VERSION ""

NS_ :

BS_:

BU_: CEM20 GW IDM Tester

BO_ 719 IFC_FD3: 64 IDM
 SG_ AttentionDivsAlarmTimGrad : 445|2@0+ (1,0) [0|3] "NoUnit" Vector__XXX
 SG_ TraLightCtrlSts : 383|3@0+ (1,0) [0|7] "NoUnit" Vector__XXX
 SG_ RR_SideCamaErrSts : 373|3@0+ (1,0) [0|7] "NoUnit" Vector__XXX
 SG_ LR_SideCamaErrSts : 360|3@0+ (1,0) [0|7] "NoUnit" Vector__XXX
 SG_ ILC_InterSysInfoDisp : 359|3@0+ (1,0) [0|7] "NoUnit" Vector__XXX
 SG_ TraLightSwtResp : 344|1@0+ (1,0) [0|1] "" Vector__XXX
 SG_ TraLightRmdInfoDisp : 349|5@0+ (1,0) [0|31] "" Vector__XXX
 SG_ TraLightWarnInfoDisp : 337|4@0+ (1,0) [0|15] "" Vector__XXX
 SG_ TSR_TFL_EgoVeh : 341|4@0+ (1,0) [0|15] "" Vector__XXX
 SG_ TSR_TFL7_LightColor : 328|3@0+ (1,0) [0|7] "" Vector__XXX
 SG_ TSR_TFL7_LightType : 332|4@0+ (1,0) [0|15] "" Vector__XXX
 SG_ TSR_TFL6_LightColor : 335|3@0+ (1,0) [0|7] "" Vector__XXX
 SG_ TSR_TFL6_LightType : 319|4@0+ (1,0) [0|15] "" Vector__XXX
 SG_ TSR_TFL5_LightColor : 307|3@0+ (1,0) [0|7] "" Vector__XXX
 SG_ TSR_TFL5_LightType : 311|4@0+ (1,0) [0|15] "" Vector__XXX
 SG_ TSR_TFL4_LightColor : 298|3@0+ (1,0) [0|7] "" Vector__XXX
 SG_ TSR_TFL4_LightType : 302|4@0+ (1,0) [0|15] "" Vector__XXX
 SG_ TSR_TFL3_LightColor : 289|3@0+ (1,0) [0|7] "" Vector__XXX
 SG_ TSR_TFL3_LightType : 293|4@0+ (1,0) [0|15] "" Vector__XXX
 SG_ TSR_TFL2_LightColor : 280|3@0+ (1,0) [0|8] "" Vector__XXX
 SG_ TSR_TFL2_LightType : 284|4@0+ (1,0) [0|15] "" Vector__XXX
 SG_ TSR_TFL1_LightColor : 287|3@0+ (1,0) [0|7] "" Vector__XXX
 SG_ TSR_TFL7_LightTime : 279|8@0+ (1,0) [0|255] "s" Vector__XXX
 SG_ TSR_TFL6_LightTime : 271|8@0+ (1,0) [0|255] "s" Vector__XXX
 SG_ NavDecActive : 239|4@0+ (1,0) [0|15] "NoUnit" Vector__XXX
 SG_ NavDecSwtResp : 225|1@0+ (1,0) [0|1] "NoUnit" Vector__XXX
 SG_ LCMode_Swt_Resp : 227|2@0+ (1,0) [0|3] "" Vector__XXX
 SG_ RainMode_Swt_Resp : 228|1@0+ (1,0) [0|1] "" Vector__XXX
 SG_ TSR_Traffic_Light_Ri : 230|2@0+ (1,0) [0|3] "" Vector__XXX
 SG_ Zebra_Mark_Dx : 223|9@0+ (0.5,0) [0|150] "m" Vector__XXX
 SG_ TSR_Traffic_Light_Le : 210|2@0+ (1,0) [0|3] "" Vector__XXX
 SG_ TSR_Traffic_Light_Through : 212|2@0+ (1,0) [0|3] "" Vector__XXX
 SG_ TSR_Traffic_Light : 214|2@0+ (1,0) [0|3] "" Vector__XXX
 SG_ Grid_Mark_Dx : 207|9@0+ (0.5,0) [0|150] "m" Vector__XXX
 SG_ LaneChngCfmSwt_Resp : 189|1@0+ (1,0) [0|1] "" Vector__XXX
 SG_ ALC_SwtReq_Resp : 190|1@0+ (1,0) [0|1] "" Vector__XXX
 SG_ AutoSpdSetSwt_Resp : 191|1@0+ (1,0) [0|1] "" Vector__XXX
 SG_ VoiceBrdcSwt_Resp : 176|1@0+ (1,0) [0|1] "" Vector__XXX
 SG_ UsrManSts_Resp : 180|4@0+ (1,0) [0|15] "" Vector__XXX
 SG_ HWA_InhibitWarn : 183|3@0+ (1,0) [0|7] "" Vector__XXX
 SG_ Grid_Mark_Detn : 169|2@0+ (1,0) [0|3] "" Vector__XXX
 SG_ Zebra_Mark_Detn : 171|2@0+ (1,0) [0|3] "" Vector__XXX
 SG_ Stop_Mark_Detn : 173|2@0+ (1,0) [0|3] "" Vector__XXX
 SG_ IFC_Line02_Source : 174|1@0+ (1,0) [0|1] "" Vector__XXX
 SG_ Stop_Mark_Dx : 167|9@0+ (0.5,0) [0|150] "m" Vector__XXX
 SG_ TSR_Traffic_Light_Posn : 153|2@0+ (1,0) [0|3] "" Vector__XXX
 SG_ NOH_WarnInfoDisp : 157|4@0+ (1,0) [0|15] "" Vector__XXX
 SG_ MRC_TakOver_Req : 159|2@0+ (1,0) [0|3] "" Vector__XXX
 SG_ IFC_Line01_Source : 144|1@0+ (1,0) [0|1] "" Vector__XXX
 SG_ MRC_InterSysInfoDisp : 148|4@0+ (1,0) [0|15] "" Vector__XXX
 SG_ HWA_TakOver_Trig : 151|3@0+ (1,0) [0|7] "" Vector__XXX
 SG_ HWA_TakOver_Req : 137|2@0+ (1,0) [0|3] "" Vector__XXX
 SG_ HWA_WarnInfoDisp : 141|4@0+ (1,0) [0|15] "" Vector__XXX
 SG_ HWA_ALC_Trig : 143|2@0+ (1,0) [0|3] "" Vector__XXX
 SG_ RollingCounter_IFC7 : 123|4@0+ (1,0) [0|15] "" Vector__XXX
 SG_ HMA_Sts : 127|3@0+ (1,0) [0|7] "" Vector__XXX
 SG_ HMA_HibeamReq : 113|2@0+ (1,0) [0|3] "" Vector__XXX
 SG_ IDC_L2_FWshrReq : 119|2@0+ (1,0) [0|3] "" Vector__XXX
 SG_ TSRSpdLimWarnAu : 104|1@0+ (1,0) [0|1] "NoUnit" Vector__XXX
 SG_ IDC_L2_FWiperReq : 107|3@0+ (1,0) [0|7] "" Vector__XXX
 SG_ TSRWarnResp : 108|1@0+ (1,0) [0|1] "" Vector__XXX
 SG_ IDC_L2_TurnLightReq : 110|2@0+ (1,0) [0|3] "" Vector__XXX
 SG_ IDC_L2_EmgyLightReq : 111|1@0+ (1,0) [0|1] "" Vector__XXX
 SG_ TSR_Snvty : 100|5@0+ (1,-15) [-15|15] "km/h" Vector__XXX
 SG_ TSRSpdLimWarn : 101|1@0+ (1,0) [0|1] "" Vector__XXX
 SG_ TSRTrfcSignVal : 93|8@0+ (1,0) [0|255] "" Vector__XXX
 SG_ TSRTrfcSignValCfdc : 95|2@0+ (1,0) [0|3] "" Vector__XXX
 SG_ TSRSpdLimSts : 81|2@0+ (1,0) [0|3] "" Vector__XXX
 SG_ TSRSpdLim : 87|6@0+ (1,0) [0|63] "" Vector__XXX
 SG_ TSRSts : 74|3@0+ (1,0) [0|7] "" Vector__XXX
 SG_ TSRSpdLimCfdc : 76|2@0+ (1,0) [0|3] "" Vector__XXX
 SG_ TSRSpdLimUnit : 78|2@0+ (1,0) [0|3] "" Vector__XXX
 SG_ TSRResp : 79|1@0+ (1,0) [0|1] "" Vector__XXX
 SG_ Checksum_IFC7 : 71|8@0+ (1,0) [0|255] "" Vector__XXX
 SG_ TSR_TFL1_LightType : 63|4@0+ (1,0) [0|15] "" Vector__XXX
 SG_ TSR_TFL5_LightTime : 55|8@0+ (1,0) [0|255] "s" Vector__XXX
 SG_ TSR_TFL4_LightTime : 47|8@0+ (1,0) [0|255] "s" Vector__XXX
 SG_ TSR_TFL3_LightTime : 39|8@0+ (1,0) [0|255] "s" Vector__XXX
 SG_ TSR_TFL2_LightTime : 31|8@0+ (1,0) [0|255] "s" Vector__XXX
 SG_ TSR_TFL1_LightTime : 23|8@0+ (1,0) [0|255] "s" Vector__XXX
 SG_ TSRConSpdLimWarn : 9|1@0+ (1,0) [0|1] "" Vector__XXX
 SG_ TSRConSpdLim : 15|6@0+ (1,0) [0|63] "" Vector__XXX

BO_ 395 AEB_FD1: 64 IDM
 SG_ RAEB_Warn : 413|3@0+ (1,0) [0|7] "NoUnit" Vector__XXX
 SG_ RAEB_State : 400|3@0+ (1,0) [0|7] "NoUnit" Vector__XXX
 SG_ EBA_State : 403|3@0+ (1,0) [0|7] "NoUnit" Vector__XXX
 SG_ AEB_State : 406|3@0+ (1,0) [0|7] "NoUnit" Vector__XXX
 SG_ AWB_State : 393|3@0+ (1,0) [0|7] "NoUnit" Vector__XXX
 SG_ FCW_State : 396|3@0+ (1,0) [0|7] "NoUnit" Vector__XXX
 SG_ DW_State : 399|3@0+ (1,0) [0|7] "NoUnit" Vector__XXX
 SG_ RollingCounter_AEB6 : 187|4@0+ (1,0) [0|15] "NoUnit" Vector__XXX
 SG_ ExcpADASBrkgHldReq : 173|2@0+ (1,0) [0|3] "NoUnit" Vector__XXX
 SG_ DrvPrsnt : 175|2@0+ (1,0) [0|3] "NoUnit" Vector__XXX
 SG_ BrkgHldReq : 161|2@0+ (1,0) [0|3] "NoUnit" Vector__XXX
 SG_ BrkgSwtReq : 163|2@0+ (1,0) [0|3] "NoUnit" Vector__XXX
 SG_ EPBModEna : 165|2@0+ (1,0) [0|3] "NoUnit" Vector__XXX
 SG_ EPBModReq : 167|2@0+ (1,0) [0|3] "NoUnit" Vector__XXX
 SG_ EPBModReqVld : 152|1@0+ (1,0) [0|1] "NoUnit" Vector__XXX
 SG_ BrkgTgtTyp : 154|2@0+ (1,0) [0|3] "NoUnit" Vector__XXX
 SG_ BrkgTgtTrqMod : 156|2@0+ (1,0) [0|3] "NoUnit" Vector__XXX
 SG_ BrkgTgtTrqEna : 158|2@0+ (1,0) [0|3] "NoUnit" Vector__XXX
 SG_ BrkgTgtTrqVld : 159|1@0+ (1,0) [0|1] "NoUnit" Vector__XXX
 SG_ BrkgTgtTrq : 143|16@0+ (1,-1) [0|65534] "Nm" Vector__XXX
 SG_ Checksum_AEB6 : 135|8@0+ (1,0) [0|255] "NoUnit" Vector__XXX
 SG_ RollingCounter_AEB1 : 123|4@0+ (1,0) [0|15] "" Vector__XXX
 SG_ IntellgntAsscRoadTypConfid : 115|4@0+ (0.1,-0.1) [0|1] "NoUnit" Vector__XXX
 SG_ IntellgntAsscRoadTyp : 119|4@0+ (1,0) [0|15] "NoUnit" Vector__XXX
 SG_ AEB_ObjSty : 111|3@0+ (1,0) [0|7] "" Vector__XXX
 SG_ AEB_BrkReqFunc : 99|3@0+ (1,0) [0|7] "" Vector__XXX
 SG_ AEB_AWB_Level : 103|4@0+ (1,0) [0|15] "" Vector__XXX
 SG_ AEB_TgtDecel_ReqValue : 87|16@0+ (0.000488,-16) [-16|15.980592] "m/s2" Vector__XXX
 SG_ AEB_ABP_Req : 72|1@0+ (1,0) [0|1] "" Vector__XXX
 SG_ AEB_AWB_Req : 73|1@0+ (1,0) [0|1] "" Vector__XXX
 SG_ AEB_TgtDecel_Req : 74|1@0+ (1,0) [0|1] "" Vector__XXX
 SG_ AEB_VehHldReq : 75|1@0+ (1,0) [0|1] "" Vector__XXX
 SG_ EBA_TgtDecel_Req : 76|1@0+ (1,0) [0|1] "" Vector__XXX
 SG_ AEB_ABA_Req : 77|1@0+ (1,0) [0|1] "" Vector__XXX
 SG_ AEB_ABA_Level : 79|2@0+ (1,0) [0|3] "" Vector__XXX
 SG_ Checksum_AEB1 : 71|8@0+ (1,0) [0|255] "" Vector__XXX
 SG_ AEB_Flag_VSI : 60|1@0+ (1,0) [0|1] "" Vector__XXX
 SG_ ADAS_ErrSts : 31|3@0+ (1,0) [0|7] "" Vector__XXX
 SG_ RelTgtObjVel_X : 23|8@0+ (0.167,0) [0|42] "mps" Vector__XXX
 SG_ TimeToCllsn : 15|8@0+ (0.004,0) [0|1] "s" Vector__XXX

BO_ 576 IFC_FD4: 64 IDM
 SG_ RollingCounter_IFC_HCM7 : 443|4@0+ (1,0) [0|15] "NoUnit" Vector__XXX
 SG_ Spots7VehObjClassn : 446|3@0+ (1,0) [0|7] "NoUnit" Vector__XXX
 SG_ Spots7TrackingInfo : 447|1@0+ (1,0) [0|1] "NoUnit" Vector__XXX
 SG_ Spot7VertAng : 439|8@0+ (0.125,-5) [-5|26.875] "NoUnit" Vector__XXX
 SG_ Spots7HozLeAngSpd : 431|8@0+ (0.125,-16) [-16|15.875] "DegPerSec" Vector__XXX
 SG_ Spots7Distance : 408|9@0+ (1,0) [0|510] "m" Vector__XXX
 SG_ Spots7Typ : 410|2@0+ (1,0) [0|3] "NoUnit" Vector__XXX
 SG_ Spots7Valid : 411|1@0+ (1,0) [0|1] "NoUnit" Vector__XXX
 SG_ Spots7HozlPosnRiAng : 405|10@0+ (0.08,-40) [-40|40] "Deg" Vector__XXX
 SG_ Spots7HozlPosnLeAng : 399|10@0+ (0.08,-40) [-40|40] "Deg" Vector__XXX
 SG_ Checksum_IFC_HCM7 : 391|8@0+ (1,0) [0|255] "NoUnit" Vector__XXX
 SG_ RollingCounter_IFC_HCM6 : 379|4@0+ (1,0) [0|15] "NoUnit" Vector__XXX
 SG_ Spots6VehObjClassn : 382|3@0+ (1,0) [0|7] "NoUnit" Vector__XXX
 SG_ Spots6TrackingInfo : 383|1@0+ (1,0) [0|1] "NoUnit" Vector__XXX
 SG_ Spot6VertAng : 375|8@0+ (0.125,-5) [-5|26.875] "NoUnit" Vector__XXX
 SG_ Spots6HozLeAngSpd : 367|8@0+ (0.125,-16) [-16|15.875] "DegPerSec" Vector__XXX
 SG_ Spots6Distance : 344|9@0+ (1,0) [0|510] "m" Vector__XXX
 SG_ Spots6Typ : 346|2@0+ (1,0) [0|3] "NoUnit" Vector__XXX
 SG_ Spots6Valid : 347|1@0+ (1,0) [0|1] "NoUnit" Vector__XXX
 SG_ Spots6HozlPosnRiAng : 341|10@0+ (0.08,-40) [-40|40] "Deg" Vector__XXX
 SG_ Spots6HozlPosnLeAng : 335|10@0+ (0.08,-40) [-40|40] "Deg" Vector__XXX
 SG_ Checksum_IFC_HCM6 : 327|8@0+ (1,0) [0|255] "NoUnit" Vector__XXX
 SG_ RollingCounter_IFC_HCM5 : 315|4@0+ (1,0) [0|15] "NoUnit" Vector__XXX
 SG_ Spots5VehObjClassn : 318|3@0+ (1,0) [0|7] "NoUnit" Vector__XXX
 SG_ Spots5TrackingInfo : 319|1@0+ (1,0) [0|1] "NoUnit" Vector__XXX
 SG_ Spot5VertAng : 311|8@0+ (0.125,-5) [-5|26.875] "NoUnit" Vector__XXX
 SG_ Spots5HozLeAngSpd : 303|8@0+ (0.125,-16) [-16|15.875] "DegPerSec" Vector__XXX
 SG_ Spots5Distance : 280|9@0+ (1,0) [0|510] "m" Vector__XXX
 SG_ Spots5Typ : 282|2@0+ (1,0) [0|3] "NoUnit" Vector__XXX
 SG_ Spots5Valid : 283|1@0+ (1,0) [0|1] "NoUnit" Vector__XXX
 SG_ Spots5HozlPosnRiAng : 277|10@0+ (0.08,-40) [-40|40] "Deg" Vector__XXX
 SG_ Spots5HozlPosnLeAng : 271|10@0+ (0.08,-40) [-40|40] "Deg" Vector__XXX
 SG_ Checksum_IFC_HCM5 : 263|8@0+ (1,0) [0|255] "NoUnit" Vector__XXX
 SG_ RollingCounter_IFC_HCM4 : 251|4@0+ (1,0) [0|15] "NoUnit" Vector__XXX
 SG_ Spots4VehObjClassn : 254|3@0+ (1,0) [0|7] "NoUnit" Vector__XXX
 SG_ Spots4TrackingInfo : 255|1@0+ (1,0) [0|1] "NoUnit" Vector__XXX
 SG_ Spot4VertAng : 247|8@0+ (0.125,-5) [-5|26.875] "NoUnit" Vector__XXX
 SG_ Spots4HozLeAngSpd : 239|8@0+ (0.125,-16) [-16|15.875] "DegPerSec" Vector__XXX
 SG_ Spots4Distance : 216|9@0+ (1,0) [0|510] "m" Vector__XXX
 SG_ Spots4Typ : 218|2@0+ (1,0) [0|3] "NoUnit" Vector__XXX
 SG_ Spots4Valid : 219|1@0+ (1,0) [0|1] "NoUnit" Vector__XXX
 SG_ Spots4HozlPosnRiAng : 213|10@0+ (0.08,-40) [-40|40] "Deg" Vector__XXX
 SG_ Spots4HozlPosnLeAng : 207|10@0+ (0.08,-40) [-40|40] "Deg" Vector__XXX
 SG_ Checksum_IFC_HCM4 : 199|8@0+ (1,0) [0|255] "NoUnit" Vector__XXX
 SG_ RollingCounter_IFC_HCM3 : 187|4@0+ (1,0) [0|15] "NoUnit" Vector__XXX
 SG_ Spots3VehObjClassn : 190|3@0+ (1,0) [0|7] "NoUnit" Vector__XXX
 SG_ Spots3TrackingInfo : 191|1@0+ (1,0) [0|1] "NoUnit" Vector__XXX
 SG_ Spot3VertAng : 183|8@0+ (0.125,-5) [-5|26.875] "NoUnit" Vector__XXX
 SG_ Spots3HozLeAngSpd : 175|8@0+ (0.125,-16) [-16|15.875] "DegPerSec" Vector__XXX
 SG_ Spots3Distance : 152|9@0+ (1,0) [0|510] "m" Vector__XXX
 SG_ Spots3Typ : 154|2@0+ (1,0) [0|3] "NoUnit" Vector__XXX
 SG_ Spots3Valid : 155|1@0+ (1,0) [0|1] "NoUnit" Vector__XXX
 SG_ Spots3HozlPosnRiAng : 149|10@0+ (0.08,-40) [-40|40] "Deg" Vector__XXX
 SG_ Spots3HozlPosnLeAng : 143|10@0+ (0.08,-40) [-40|40] "Deg" Vector__XXX
 SG_ Checksum_IFC_HCM3 : 135|8@0+ (1,0) [0|255] "NoUnit" Vector__XXX
 SG_ RollingCounter_IFC_HCM2 : 123|4@0+ (1,0) [0|15] "NoUnit" Vector__XXX
 SG_ Spots2VehObjClassn : 126|3@0+ (1,0) [0|7] "NoUnit" Vector__XXX
 SG_ Spots2TrackingInfo : 127|1@0+ (1,0) [0|1] "NoUnit" Vector__XXX
 SG_ Spot2VertAng : 119|8@0+ (0.125,-5) [-5|26.875] "NoUnit" Vector__XXX
 SG_ Spots2HozLeAngSpd : 111|8@0+ (0.125,-16) [-16|15.875] "DegPerSec" Vector__XXX
 SG_ Spots2Distance : 88|9@0+ (1,0) [0|510] "m" Vector__XXX
 SG_ Spots2Typ : 90|2@0+ (1,0) [0|3] "NoUnit" Vector__XXX
 SG_ Spots2Valid : 91|1@0+ (1,0) [0|1] "NoUnit" Vector__XXX
 SG_ Spots2HozlPosnRiAng : 85|10@0+ (0.08,-40) [-40|40] "Deg" Vector__XXX
 SG_ Spots2HozlPosnLeAng : 79|10@0+ (0.08,-40) [-40|40] "Deg" Vector__XXX
 SG_ Checksum_IFC_HCM2 : 71|8@0+ (1,0) [0|255] "NoUnit" Vector__XXX
 SG_ RollingCounter_IFC_HCM1 : 59|4@0+ (1,0) [0|15] "NoUnit" Vector__XXX
 SG_ Spots1VehObjClassn : 62|3@0+ (1,0) [0|7] "NoUnit" Vector__XXX
 SG_ Spots1TrackingInfo : 63|1@0+ (1,0) [0|1] "NoUnit" Vector__XXX
 SG_ Spot1VertAng : 55|8@0+ (0.125,-5) [-5|26.875] "NoUnit" Vector__XXX
 SG_ Spots1HozLeAngSpd : 47|8@0+ (0.125,-16) [-16|15.875] "DegPerSec" Vector__XXX
 SG_ Spots1Distance : 24|9@0+ (1,0) [0|510] "m" Vector__XXX
 SG_ Spots1Typ : 26|2@0+ (1,0) [0|3] "NoUnit" Vector__XXX
 SG_ Spots1Valid : 27|1@0+ (1,0) [0|1] "NoUnit" Vector__XXX
 SG_ Spots1HozlPosnRiAng : 21|10@0+ (0.08,-40) [-40|40] "Deg" Vector__XXX
 SG_ Spots1HozlPosnLeAng : 15|10@0+ (0.08,-40) [-40|40] "Deg" Vector__XXX
 SG_ Checksum_IFC_HCM1 : 7|8@0+ (1,0) [0|255] "NoUnit" Vector__XXX

BO_ 667 HAP_FD7: 64 IDM
 SG_ HAVP_LrngDst : 375|10@0+ (1,0) [0|1000] "m" Vector__XXX
 SG_ PAVP_ScFail_info : 367|5@0+ (1,0) [0|31] "" Vector__XXX
 SG_ HAVP_ScFail_info : 351|5@0+ (1,0) [0|31] "" Vector__XXX
 SG_ UnPrkgSpaReasons : 341|6@0+ (1,0) [0|63] "NoUnit" Vector__XXX

BO_ 674 IFC_FD7: 48 IDM
 SG_ RP_Num_Points_Per_Tube : 207|16@0+ (1,0) [0|1200] "" Vector__XXX
 SG_ RP_Algo_MCU_TimeStamp : 135|64@0+ (1,0) [0|18446744073709500416] "ms" Vector__XXX
 SG_ RP_Shock_Dist_R : 108|10@0+ (0.02,0) [0|20] "m" Vector__XXX
 SG_ RP_Shock_Height_R : 101|9@0+ (0.002,-0.3) [-0.3|0.3] "m" Vector__XXX
 SG_ RP_Shock_Dist_L : 95|10@0+ (0.02,0) [0|20] "m" Vector__XXX
 SG_ RP_Shock_Confidence_L : 86|7@0+ (0.01,0) [0|1] "" Vector__XXX
 SG_ RP_Shock_Height_L : 79|9@0+ (0.002,-0.3) [-0.3|0.3] "m" Vector__XXX
 SG_ RP_Shock_Detected_R : 60|1@0+ (1,0) [0|1] "" Vector__XXX
 SG_ RP_Shock_Detected_L : 61|1@0+ (1,0) [0|1] "" Vector__XXX
 SG_ RP_New_Measurment : 62|1@0+ (1,0) [0|1] "" Vector__XXX
 SG_ RP_Valid : 63|1@0+ (1,0) [0|1] "" Vector__XXX
 SG_ RP_Shock_Confidence_R : 55|7@0+ (0.01,0) [0|1] "" Vector__XXX
 SG_ RP_Start_Point_Distance : 35|10@0+ (0.01,0) [0|10] "m" Vector__XXX
 SG_ RP_Used_Speed : 31|12@0+ (0.05,-10) [-10|100] "m/s" Vector__XXX
 SG_ RP_Sync_ID : 15|8@0+ (1,0) [0|255] "" Vector__XXX

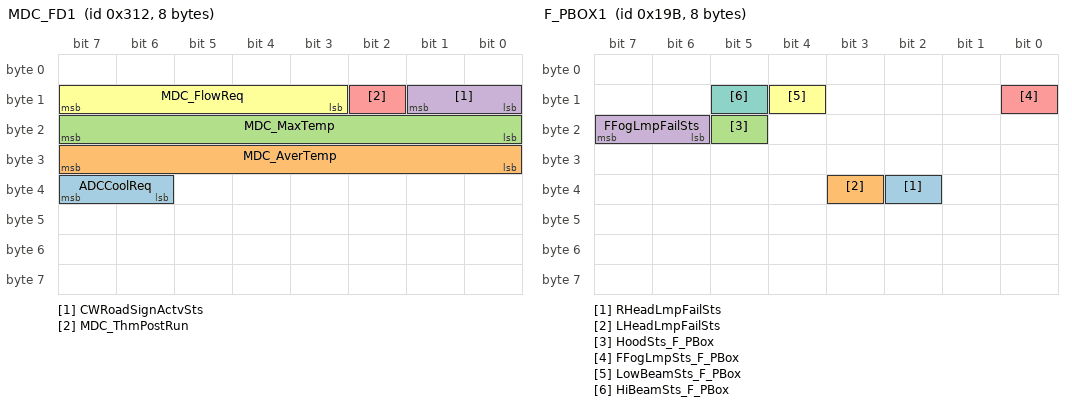
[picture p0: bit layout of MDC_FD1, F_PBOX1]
BO_ 786 MDC_FD1: 8 IDM
 SG_ ADCCoolReq : 39|2@0+ (1,0) [0|3] "NoUnit" Vector__XXX
 SG_ MDC_AverTemp : 31|8@0+ (1,-50) [-50|204] "DegCgrd" Vector__XXX
 SG_ MDC_MaxTemp : 23|8@0+ (1,-50) [-50|204] "DegCgrd" Vector__XXX
 SG_ CWRoadSignActvSts : 9|2@0+ (1,0) [0|3] "NoUnit" Vector__XXX
 SG_ MDC_ThmPostRun : 10|1@0+ (1,0) [0|1] "NoUnit" Vector__XXX
 SG_ MDC_FlowReq : 15|5@0+ (0.25,0) [0|4] "NoUnit" Vector__XXX

BO_ 1125 IDC_Sync_Req: 16 IDM
 SG_ IDC_Sync_Req : 7|128@0+ (1,0) [0|0] "" Vector__XXX

BO_ 573 IFC_FD2: 64 IDM
 SG_ MAC_Check_IFC_FD2 : 471|48@0+ (1,0) [0|281474976710655] "" Vector__XXX
 SG_ FreshnessValue_IFC_FD2 : 455|16@0+ (1,0) [0|65535] "" Vector__XXX
 SG_ SceneModSts : 447|3@0+ (1,0) [0|7] "NoUnit" Vector__XXX
 SG_ IFC_Line_special02_Curv : 431|15@0+ (1.6e-05,-0.25) [-0.25|0.25] "PerMtr" Vector__XXX
 SG_ IFC_Line_special01_DxEnd : 414|15@0+ (0.01,0) [0|200.01] "m" Vector__XXX
 SG_ IFC_Line_special01_DxStart : 399|15@0+ (0.01,0) [0|200.01] "m" Vector__XXX
 SG_ ACC_LeTgtObjBarDisp_03 : 383|3@0+ (1,0) [0|7] "NoUnit" Vector__XXX
 SG_ TargetPathC1 : 360|9@0+ (0.01,-2) [-2|2.01] "rad" Vector__XXX
 SG_ ACC_RiTgtObjBarDisp_02 : 363|3@0+ (1,0) [0|7] "NoUnit" Vector__XXX
 SG_ IFC_Line_special01_CurvChange : 351|20@0+ (5e-08,-0.024) [-0.024|0.024] "PerMtrSq" Vector__XXX
 SG_ IFC_Line_special01_Curv : 335|15@0+ (1.6e-05,-0.25) [-0.25|0.25] "PerMtr" Vector__XXX
 SG_ ACC_LeTgtObjBarDisp_02 : 318|3@0+ (1,0) [0|7] "NoUnit" Vector__XXX
 SG_ SidePrkgSts : 304|2@0+ (1,0) [0|3] "NoUnit" Vector__XXX
 SG_ HandsoffModSts : 306|2@0+ (1,0) [0|3] "NoUnit" Vector__XXX
 SG_ HandsoffTimSts : 308|2@0+ (1,0) [0|3] "NoUnit" Vector__XXX
 SG_ ACC_TgtObjBarDisp_03 : 311|3@0+ (1,0) [0|7] "NoUnit" Vector__XXX
 SG_ ACC_TgtObjBarDisp_02 : 298|3@0+ (1,0) [0|7] "NoUnit" Vector__XXX
 SG_ IFC_Line_special01_Dy : 295|13@0+ (0.01,-30) [-30|30.01] "m" Vector__XXX
 SG_ IFC_NextRiLane_dy : 275|12@0+ (0.00390625,-8) [-8|7.9921875] "" Vector__XXX
 SG_ IFC_NextLeLane_dy : 271|12@0+ (0.00390625,-8) [-8|7.9921875] "" Vector__XXX
 SG_ SmarFrontviewcamSts : 255|3@0+ (1,0) [0|7] "NoUnit" Vector__XXX
 SG_ IFC_RiLane_dy : 235|12@0+ (0.00390625,-8) [-8|7.9921875] "" Vector__XXX
 SG_ IFC_LeLane_dy : 231|12@0+ (0.00390625,-8) [-8|7.9921875] "" Vector__XXX
 SG_ IFC_NextRiLaneTyp : 218|3@0+ (1,0) [0|7] "" Vector__XXX
 SG_ IFC_NextLeLaneTyp : 221|3@0+ (1,0) [0|7] "" Vector__XXX
 SG_ IFC_RiLaneTyp : 208|3@0+ (1,0) [0|7] "" Vector__XXX
 SG_ IFC_LeLaneTyp : 211|3@0+ (1,0) [0|7] "" Vector__XXX
 SG_ IFC_LaneCurve : 207|12@0+ (1.5e-05,-0.030705) [-0.030705|0.030705] "" Vector__XXX
 SG_ ESSintervention : 189|2@0+ (1,0) [0|3] "" Vector__XXX
 SG_ AESintervention : 191|2@0+ (1,0) [0|3] "" Vector__XXX
 SG_ IFC_Line_special02_Type : 179|4@0+ (1,0) [0|15] "NoUnit" Vector__XXX
 SG_ IFC_Line_special01_Type : 183|4@0+ (1,0) [0|15] "NoUnit" Vector__XXX
 SG_ IFC_Line_special02_HeadingAngle : 161|9@0+ (0.01,-2) [-2|2.01] "rad" Vector__XXX
 SG_ LCKStsIndcr : 163|2@0+ (1,0) [0|3] "" Vector__XXX
 SG_ IntelligentEvaActSts : 165|2@0+ (1,0) [0|3] "" Vector__XXX
 SG_ ELKActSts : 167|2@0+ (1,0) [0|3] "" Vector__XXX
 SG_ CameraBlockageSts : 152|1@0+ (1,0) [0|1] "" Vector__XXX
 SG_ IFCCalibrationSts : 154|2@0+ (1,0) [0|3] "" Vector__XXX
 SG_ IFC_Handsoffwarn : 157|3@0+ (1,0) [0|7] "" Vector__XXX
 SG_ LSSErrSts : 144|3@0+ (1,0) [0|7] "" Vector__XXX
 SG_ TJA_FollowSts : 146|2@0+ (1,0) [0|3] "" Vector__XXX
 SG_ LaneAvailability : 148|2@0+ (1,0) [0|3] "" Vector__XXX
 SG_ ELKMainState : 151|3@0+ (1,0) [0|7] "" Vector__XXX
 SG_ LSSFuncSts : 138|3@0+ (1,0) [0|7] "" Vector__XXX
 SG_ LSSIntervention : 141|3@0+ (1,0) [0|7] "" Vector__XXX
 SG_ LDW_LKAWarn : 143|2@0+ (1,0) [0|3] "" Vector__XXX
 SG_ LCP_Warn : 125|2@0+ (1,0) [0|3] "NoUnit" Vector__XXX
 SG_ IFC_Line_special01_HeadingAngle : 118|9@0+ (0.01,-2) [-2|2.01] "rad" Vector__XXX
 SG_ RiRoad_Mark_Dy : 110|8@0+ (0.1,-8) [-8|8] "m" Vector__XXX
 SG_ RiRoad_Mark_Dx : 103|9@0+ (0.5,0) [0|150] "m" Vector__XXX
 SG_ RiRoad_Mark_Typ : 91|4@0+ (1,0) [0|15] "NoUnit" Vector__XXX
 SG_ ESSErrSts : 92|1@0+ (1,0) [0|1] "" Vector__XXX
 SG_ AESErrSts : 93|1@0+ (1,0) [0|1] "" Vector__XXX
 SG_ ESSSts : 95|2@0+ (1,0) [0|3] "" Vector__XXX
 SG_ AESSts : 81|2@0+ (1,0) [0|3] "" Vector__XXX
 SG_ IntelligentEvaResp : 82|1@0+ (1,0) [0|1] "" Vector__XXX
 SG_ LSSResp : 83|1@0+ (1,0) [0|1] "" Vector__XXX
 SG_ LSSWarnFormResp : 85|2@0+ (1,0) [0|3] "" Vector__XXX
 SG_ ESS_VehResp : 86|1@0+ (1,0) [0|1] "" Vector__XXX
 SG_ ESS_PedResp : 87|1@0+ (1,0) [0|1] "" Vector__XXX
 SG_ IFCHUTInterface : 72|1@0+ (1,0) [0|1] "" Vector__XXX
 SG_ LDW_LKA_Snvty : 74|2@0+ (1,0) [0|3] "" Vector__XXX
 SG_ AESResp : 75|1@0+ (1,0) [0|1] "" Vector__XXX
 SG_ ELKResp : 76|1@0+ (1,0) [0|1] "" Vector__XXX
 SG_ LCKResp : 77|1@0+ (1,0) [0|1] "" Vector__XXX
 SG_ LKAResp : 78|1@0+ (1,0) [0|1] "" Vector__XXX
 SG_ LDWResp : 79|1@0+ (1,0) [0|1] "" Vector__XXX
 SG_ LeRoad_Mark_Typ : 63|4@0+ (1,0) [0|15] "NoUnit" Vector__XXX
 SG_ LeRoad_Mark_Dy : 55|8@0+ (0.1,-8) [-8|8] "m" Vector__XXX
 SG_ Road_Mark_Dy : 47|8@0+ (0.1,-8) [-8|8] "m" Vector__XXX
 SG_ LeRoad_Mark_Dx : 24|9@0+ (0.5,0) [0|150] "m" Vector__XXX
 SG_ Road_Mark_Dx : 17|9@0+ (0.5,0) [0|150] "m" Vector__XXX
 SG_ Road_Mark_Typ : 21|4@0+ (1,0) [0|15] "NoUnit" Vector__XXX
 SG_ HWA_Text_Lib : 11|6@0+ (1,0) [0|63] "NoUnit" Vector__XXX
 SG_ IFC_FeatPt_Type : 15|4@0+ (1,0) [0|15] "NoUnit" Vector__XXX

BO_ 411 F_PBOX1: 8 CEM20
 SG_ RHeadLmpFailSts : 34|1@0+ (1,0) [0|1] "NoUnit"  IDM
 SG_ LHeadLmpFailSts : 35|1@0+ (1,0) [0|1] "NoUnit"  IDM
 SG_ HoodSts_F_PBox : 21|1@0+ (1,0) [0|1] ""  IDM
 SG_ FFogLmpFailSts : 23|2@0+ (1,0) [0|3] "NoUnit"  IDM
 SG_ FFogLmpSts_F_PBox : 8|1@0+ (1,0) [0|1] ""  IDM
 SG_ LowBeamSts_F_PBox : 12|1@0+ (1,0) [0|1] ""  IDM
 SG_ HiBeamSts_F_PBox : 13|1@0+ (1,0) [0|1] ""  IDM

BO_ 412 R_PBOX1: 16 CEM20
 SG_ RFogLmpSts_R_PBox : 28|1@0+ (1,0) [0|1] ""  IDM
 SG_ RFogLmpFailSts_R_PBox : 29|1@0+ (1,0) [0|1] ""  IDM
 SG_ RTurnLmpSts_R_PBox : 30|1@0+ (1,0) [0|1] ""  IDM
 SG_ LTurnLmpSts_R_PBox : 31|1@0+ (1,0) [0|1] ""  IDM
 SG_ LTurnLmpFailSts : 17|2@0+ (1,0) [0|3] "NoUnit"  IDM
 SG_ RTurnLmpFailSts : 19|2@0+ (1,0) [0|3] "NoUnit"  IDM
 SG_ PosnLmpOutpSts_R_PBox : 11|1@0+ (1,0) [0|1] ""  IDM
 SG_ RBrkLmpFailSts : 12|1@0+ (1,0) [0|1] ""  IDM
 SG_ LBrkLmpFailSts : 13|1@0+ (1,0) [0|1] ""  IDM
 SG_ HiPosnBrkLmpFailSts : 15|1@0+ (1,0) [0|1] ""  IDM

BO_ 1121 CEM_Sync: 16 CEM20
 SG_ CEM_Sync : 7|128@0+ (1,0) [0|0] ""  IDM

BO_ 833 TPMS1: 16 CEM20
 SG_ MAC_Check_TPMS1 : 87|48@0+ (1,0) [0|281474976710655] "NoUnit"  IDM
 SG_ FreshnessValue_TPMS1 : 71|16@0+ (1,0) [0|65535] "NoUnit"  IDM
 SG_ TPMS_AutoLoctSts : 39|4@0+ (1,0) [0|5] ""  IDM
 SG_ RRTireTempSts : 25|2@0+ (1,0) [0|3] ""  IDM
 SG_ RLTireTempSts : 27|2@0+ (1,0) [0|3] ""  IDM
 SG_ FRTireTempSts : 29|2@0+ (1,0) [0|3] ""  IDM
 SG_ FLTireTempSts : 31|2@0+ (1,0) [0|3] ""  IDM
 SG_ RRTirePressIndSts : 20|3@0+ (1,0) [0|7] ""  IDM
 SG_ RLTirePressIndSts : 23|3@0+ (1,0) [0|7] ""  IDM
 SG_ TirePressSysFailrIndcn : 9|2@0+ (1,0) [0|3] ""  IDM
 SG_ FRTirePressIndSts : 12|3@0+ (1,0) [0|7] ""  IDM
 SG_ FLTirePressIndSts : 15|3@0+ (1,0) [0|7] ""  IDM

BO_ 837 BCM3: 16 CEM20
 SG_ EnvModDetn : 44|2@0+ (1,0) [0|3] "NoUnit"  IDM
 SG_ HiLowBeamSts : 33|2@0+ (1,0) [0|2] "NoUnit"  IDM
 SG_ DrvDoorLockSts : 34|1@0+ (1,0) [0|1] ""  IDM
 SG_ HazardLmpSwtSts : 8|1@0+ (1,0) [0|1] ""  IDM
 SG_ DoorLockSts : 13|2@0+ (1,0) [0|3] "NoUnit"  IDM

BO_ 473 GW_OTA: 8 CEM20
 SG_ OTApowertrainmode : 12|2@0+ (1,0) [0|3] "NoUnit"  IDM

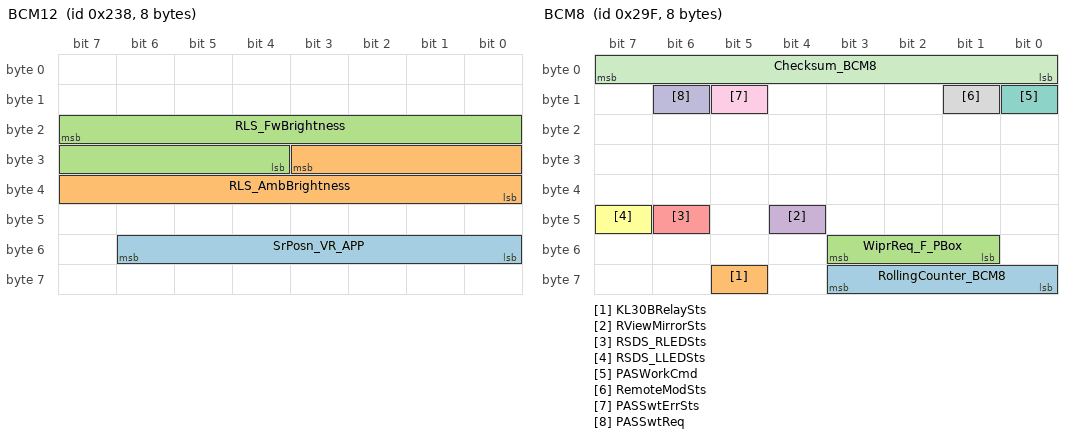
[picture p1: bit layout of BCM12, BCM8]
BO_ 568 BCM12: 8 CEM20
 SG_ SrPosn_VR_APP : 54|7@0+ (1,0) [0|127] ""  IDM
 SG_ RLS_AmbBrightness : 27|12@0+ (20,0) [0|81880] ""  IDM
 SG_ RLS_FwBrightness : 23|12@0+ (6,0) [0|24564] ""  IDM

BO_ 569 GW1: 8 CEM20
 SG_ BasicFunReq : 31|8@0+ (1,0) [1|254] "NoUnit"  IDM
 SG_ BasicFunID : 23|8@0+ (1,0) [1|254] "NoUnit"  IDM

BO_ 661 PEPS2: 8 CEM20
 SG_ SysPowerModVld : 13|1@0+ (1,0) [0|1] ""  IDM
 SG_ SysPowerMod : 15|2@0+ (1,0) [0|3] ""  IDM

BO_ 671 BCM8: 8 CEM20
 SG_ RollingCounter_BCM8 : 59|4@0+ (1,0) [0|15] ""  IDM
 SG_ KL30BRelaySts : 61|1@0+ (1,0) [0|1] ""  IDM
 SG_ WiprReq_F_PBox : 51|3@0+ (1,0) [0|7] ""  IDM
 SG_ RViewMirrorSts : 44|1@0+ (1,0) [0|1] ""  IDM
 SG_ RSDS_RLEDSts : 46|1@0+ (1,0) [0|1] "NoUnit"  IDM
 SG_ RSDS_LLEDSts : 47|1@0+ (1,0) [0|1] "NoUnit"  IDM
 SG_ PASWorkCmd : 8|1@0+ (1,0) [0|1] ""  IDM
 SG_ RemoteModSts : 9|1@0+ (1,0) [0|1] "1"  IDM
 SG_ PASSwtErrSts : 13|1@0+ (1,0) [0|1] "NoUnit"  IDM
 SG_ PASSwtReq : 14|1@0+ (1,0) [0|1] "NoUnit"  IDM
 SG_ Checksum_BCM8 : 7|8@0+ (1,0) [0|255] ""  IDM

BO_ 699 GW_FD1: 64 CEM20
 SG_ OTA_UpgrdModSts : 343|2@0+ (1,0) [0|3] "NoUnit"  IDM

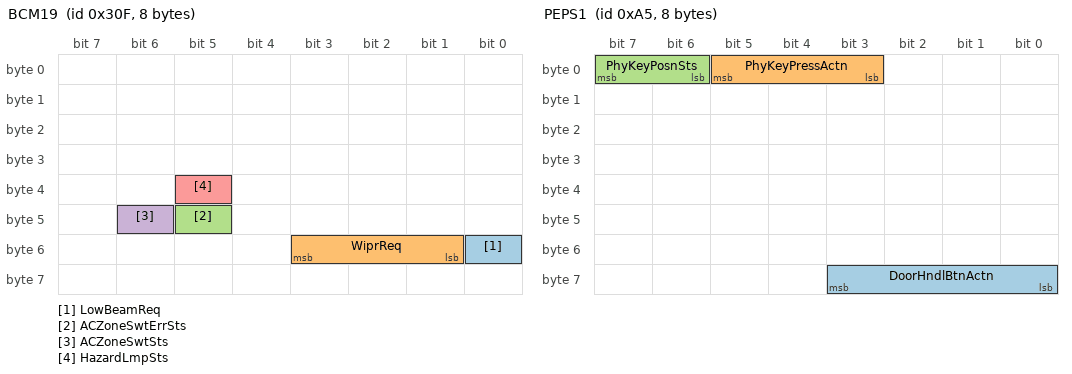
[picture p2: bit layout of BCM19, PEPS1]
BO_ 783 BCM19: 8 CEM20
 SG_ LowBeamReq : 48|1@0+ (1,0) [0|1] "NoUnit"  IDM
 SG_ WiprReq : 51|3@0+ (1,0) [0|7] ""  IDM
 SG_ ACZoneSwtErrSts : 45|1@0+ (1,0) [0|1] ""  IDM
 SG_ ACZoneSwtSts : 46|1@0+ (1,0) [0|1] ""  IDM
 SG_ HazardLmpSts : 37|1@0+ (1,0) [0|1] "NoUnit"  IDM

BO_ 793 BCM1: 16 CEM20
 SG_ RollingCounter_BCM1 : 59|4@0+ (1,0) [0|15] "NoUnit"  IDM
 SG_ PosnLightReq : 61|1@0+ (1,0) [0|1] "NoUnit"  IDM
 SG_ LowBeamSts : 62|1@0+ (1,0) [0|1] "NoUnit"  IDM
 SG_ RLSFailSts : 63|1@0+ (1,0) [0|1] "NoUnit"  IDM
 SG_ HoodSts : 40|1@0+ (1,0) [0|1] "NoUnit"  IDM
 SG_ ReversGearSts : 42|2@0+ (1,0) [0|3] "NoUnit"  IDM
 SG_ BrkPedalSts_BCM : 16|1@0+ (1,0) [0|1] "NoUnit"  IDM
 SG_ WindshldWiprActvSts : 17|1@0+ (1,0) [0|1] ""  IDM
 SG_ RRDoorSts : 19|1@0+ (1,0) [0|1] ""  IDM
 SG_ PassengerDoorSts : 20|1@0+ (1,0) [0|1] ""  IDM
 SG_ LRDoorSts : 21|1@0+ (1,0) [0|1] ""  IDM
 SG_ DrvDoorSts : 22|1@0+ (1,0) [0|1] ""  IDM
 SG_ TrunkSts : 23|1@0+ (1,0) [0|1] ""  IDM
 SG_ HiBeamSts : 11|1@0+ (1,0) [0|1] "NoUnit"  IDM
 SG_ Checksum_BCM1 : 7|8@0+ (1,0) [0|255] "NoUnit"  IDM

BO_ 917 TPMS2: 16 CEM20
 SG_ RRTireTemp : 63|8@0+ (1,-50) [-50|204] "°C"  IDM
 SG_ RRTirePress : 55|8@0+ (1.3725,0) [0|348.615] "kPa"  IDM
 SG_ RLTireTemp : 47|8@0+ (1,-50) [-50|204] "°C"  IDM
 SG_ RLTirePress : 39|8@0+ (1.3725,0) [0|348.615] "kPa"  IDM
 SG_ FRTireTemp : 31|8@0+ (1,-50) [-50|204] "°C"  IDM
 SG_ FRTirePress : 23|8@0+ (1.3725,0) [0|348.615] "kPa"  IDM
 SG_ FLTireTemp : 15|8@0+ (1,-50) [-50|204] "°C"  IDM
 SG_ FLTirePress : 7|8@0+ (1.3725,0) [0|348.615] "kPa"  IDM

BO_ 165 PEPS1: 8 CEM20
 SG_ DoorHndlBtnActn : 59|4@0+ (1,0) [0|15] "NoUnit"  IDM
 SG_ PhyKeyPressActn : 5|3@0+ (1,0) [0|7] "NoUnit"  IDM
 SG_ PhyKeyPosnSts : 7|2@0+ (1,0) [0|3] "NoUnit"  IDM

BO_ 259 ECM_FD2: 64 GW
 SG_ IdleSpdSts : 381|1@0+ (1,0) [0|1] ""  IDM
 SG_ IdleCtrlWhlTrq : 354|11@0+ (5,-3005) [-3000|4500] "Nm"  IDM
 SG_ EngState_PHEV : 351|3@0+ (1,0) [0|7] ""  IDM
 SG_ RollingCounter_ECM2 : 251|4@0+ (1,0) [0|15] "NoUnit"  IDM
 SG_ EngState : 254|2@0+ (1,0) [0|3] "NoUnit"  IDM
 SG_ AccelPedalPosnVldty : 242|2@0+ (1,0) [0|3] "NoUnit"  IDM
 SG_ AccelPedalPosn : 223|8@0+ (0.3937,0) [0|100.3935] "Perc"  IDM
 SG_ Checksum_ECM2 : 199|8@0+ (1,0) [0|255] "NoUnit"  IDM
 SG_ RollingCounter_ECM9 : 123|4@0+ (1,0) [0|15] "NoUnit"  IDM
 SG_ AccelPedlPosnDiagc : 103|8@0+ (0.3937,0) [0|100.3935] "Perc"  IDM
 SG_ EngTgtIdleSpd : 87|8@0+ (10,0) [0|2550] "rpm"  IDM
 SG_ Checksum_ECM9 : 71|8@0+ (1,0) [0|255] "NoUnit"  IDM

BO_ 273 ECM1: 8 GW
 SG_ EngSpdVldty : 63|2@0+ (1,0) [0|3] ""  IDM
 SG_ EngSpd : 47|16@0+ (0.125,0) [0|8191.875] "rpm"  IDM

BO_ 283 VCU_FD2: 64 GW
 SG_ VMCFucActvSts : 423|4@0+ (1,0) [0|15] "NoUnit"  IDM
 SG_ VCU_DrvReqTqWhl_FA : 351|15@0+ (1,-16383) [-16383|16383] "Nm"  IDM
 SG_ VCU_DrvReqTqWhl_RA : 335|15@0+ (1,-16383) [-16383|16383] "Nm"  IDM
 SG_ HCU_VirtLoad_FA : 276|5@0+ (1,0) [0|31] ""  IDM
 SG_ IdleSpdSetPointReq : 271|11@0+ (2,0) [0|4090] "rpm"  IDM
 SG_ AccrPedlAntiMsstpngSts : 209|2@0+ (1,0) [0|3] "NoUnit"  IDM
 SG_ IOTACoolingResp : 211|2@0+ (1,0) [0|3] "NoUnit"  IDM
 SG_ VCU_MaxSpdLimit : 207|12@0+ (0.1,0) [0|300] "kph"  IDM
 SG_ RollingCounter_VCU26 : 187|4@0+ (1,0) [0|15] ""  IDM
 SG_ DrvTrqReqOvld : 189|2@0+ (1,0) [0|3] "NoUnit"  IDM
 SG_ ActTotWheelTrq : 171|13@0+ (5,-20475) [-20475|20475] "Nm"  IDM
 SG_ VCU_DrvReqTqWhl : 167|12@0+ (5,-6000) [-6000|14470] "Nm"  IDM
 SG_ MaxPsblPosWheelTrq : 147|12@0+ (5,0) [0|20470] "Nm"  IDM
 SG_ MinPsblNegWheelTrq : 143|12@0+ (5,-20470) [-20470|0] "Nm"  IDM
 SG_ Checksum_VCU26 : 135|8@0+ (1,0) [0|255] ""  IDM
 SG_ RollingCounter_VCU21 : 123|4@0+ (1,0) [0|15] "NoUnit"  IDM
 SG_ DrvgPrkgTrqRespFlg : 125|2@0+ (1,0) [0|3] "NoUnit"  IDM
 SG_ DrvgPrkgTrqAvailSts : 127|2@0+ (1,0) [0|3] "NoUnit"  IDM
 SG_ DrvTrqReqOvrdvld : 89|1@0+ (1,0) [0|1] "NoUnit"  IDM
 SG_ FMCUIdleSts : 91|2@0+ (1,0) [0|3] "NoUnit"  IDM
 SG_ Checksum_VCU21 : 71|8@0+ (1,0) [0|255] "NoUnit"  IDM
 SG_ RollingCounter_VCU12 : 59|4@0+ (1,0) [0|15] ""  IDM
 SG_ PTDrvMod : 62|3@0+ (1,0) [0|7] "No Unit"  IDM
 SG_ DrvMod : 20|5@0+ (1,0) [0|31] ""  IDM
 SG_ VCU_ACCComIf : 23|1@0+ (1,0) [0|1] "No Unit"  IDM
 SG_ ActDrvMod : 15|5@0+ (1,0) [0|31] "NoUnit"  IDM
 SG_ Checksum_VCU12 : 7|8@0+ (1,0) [0|255] ""  IDM

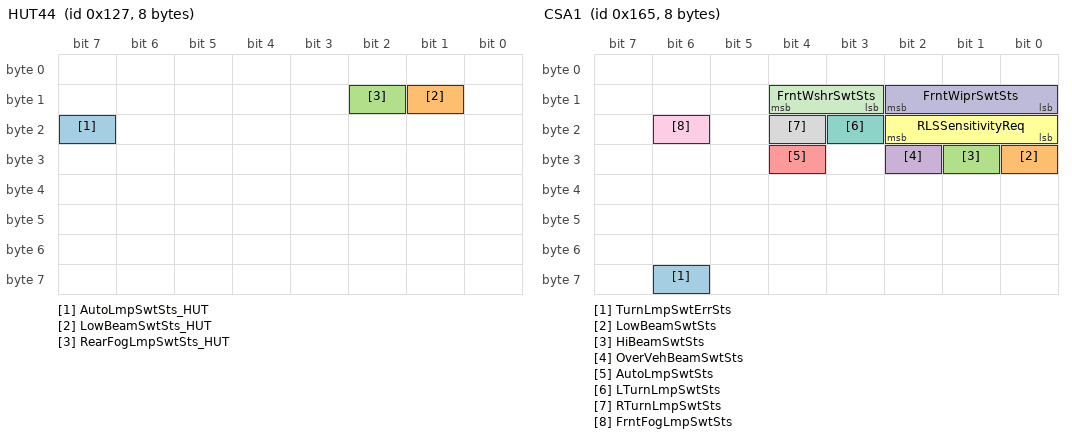
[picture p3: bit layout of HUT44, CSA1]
BO_ 295 HUT44: 8 GW
 SG_ AutoLmpSwtSts_HUT : 23|1@0+ (1,0) [0|1] "NoUnit"  IDM
 SG_ LowBeamSwtSts_HUT : 9|1@0+ (1,0) [0|1] "NoUnit"  IDM
 SG_ RearFogLmpSwtSts_HUT : 10|1@0+ (1,0) [0|1] "NoUnit"  IDM

BO_ 302 IBC_FD1: 64 GW
 SG_ RollingCounter_IBC_FD1_5 : 315|4@0+ (1,0) [0|15] ""  IDM
 SG_ APCFailrSts : 318|3@0+ (1,0) [0|7] ""  IDM
 SG_ BrkgOvrdVld : 306|1@0+ (1,0) [0|1] "NoUnit"  IDM
 SG_ MEBavailability : 308|1@0+ (1,0) [0|1] ""  IDM
 SG_ APCSts : 311|3@0+ (1,0) [0|7] ""  IDM
 SG_ RPAavailability : 297|2@0+ (1,0) [0|3] ""  IDM
 SG_ APAavailability : 298|1@0+ (1,0) [0|1] ""  IDM
 SG_ CddApActvVehHld : 299|1@0+ (1,0) [0|1] ""  IDM
 SG_ AVPavailability : 301|2@0+ (1,0) [0|3] "NoUnit"  IDM
 SG_ DrvBrkOvrdFlg : 303|2@0+ (1,0) [0|3] ""  IDM
 SG_ Checksum_IBC_FD1_5 : 263|8@0+ (1,0) [0|255] ""  IDM
 SG_ HydBrkgActTrq : 163|14@0+ (1,-1) [0|16383] "Nm"  IDM
 SG_ HydBrkgTrqReq : 145|14@0+ (1,-1) [0|16383] "Nm"  IDM
 SG_ DrvBrkgTrqReq : 143|14@0+ (1,-1) [0|16383] "Nm"  IDM
 SG_ RollingCounter_IBC_FD1_2 : 123|4@0+ (1,0) [0|15] "NoUnit"  IDM
 SG_ BrkHldActvSts : 113|2@0+ (1,0) [0|3] "NoUnit"  IDM
 SG_ BrkHldAvailSts : 115|2@0+ (1,0) [0|3] "NoUnit"  IDM
 SG_ BrkgTrqModResp : 119|2@0+ (1,0) [0|3] "NoUnit"  IDM
 SG_ PrkgBrkgTrqAvailSts : 90|3@0+ (1,0) [0|7] "NoUnit"  IDM
 SG_ DrvgBrkgTrqAvailSts : 93|3@0+ (1,0) [0|7] "NoUnit"  IDM
 SG_ Checksum_IBC_FD1_2 : 71|8@0+ (1,0) [0|255] "NoUnit"  IDM
 SG_ RollingCounter_IBC_FD1_1 : 59|4@0+ (1,0) [0|15] "NoUnit"  IDM
 SG_ CST_Status : 49|2@0+ (1,0) [0|3] ""  IDM
 SG_ PushrodStauts : 51|2@0+ (1,0) [0|3] "NoUnit"  IDM
 SG_ BrkFldWarn : 53|2@0+ (1,0) [0|3] ""  IDM
 SG_ InpRodStk : 47|10@0+ (0.05,-5) [-5|46.15] "mm"  IDM
 SG_ InpRodStkSts : 32|1@0+ (1,0) [0|1] "NoUnit"  IDM
 SG_ FWA_Warn : 34|2@0+ (1,0) [0|3] "NoUnit"  IDM
 SG_ PlungerPressSts : 35|1@0+ (1,0) [0|1] "NoUnit"  IDM
 SG_ PlungerPress : 31|12@0+ (0.3,-5) [-5|301.9] "bar"  IDM
 SG_ IBCSysSts : 18|3@0+ (1,0) [0|7] ""  IDM
 SG_ SimtorPressSts : 19|1@0+ (1,0) [0|1] ""  IDM
 SG_ SimtorPress : 15|12@0+ (0.3,-5) [-5|301.9] "Bar"  IDM
 SG_ Checksum_IBC_FD1_1 : 7|8@0+ (1,0) [0|255] "NoUnit"  IDM

BO_ 311 ESP_FD2: 64 GW
 SG_ MAC_Check_ESP_FD2 : 471|48@0+ (1,0) [0|281474976710655] ""  IDM
 SG_ FreshnessValue_ESP_FD2 : 455|16@0+ (1,0) [0|65535] ""  IDM
 SG_ RWSAngMinLimn : 437|10@0+ (0.01,-10) [-10|0] "Deg"  IDM
 SG_ RWSAngMaxLimn : 431|10@0+ (0.01,0) [0|10] "Deg"  IDM
 SG_ RollingCounter_ABS3 : 379|4@0+ (1,0) [0|15] ""  IDM
 SG_ VehOdoInfo : 345|10@0+ (1,0) [0|999] "m"  IDM
 SG_ VehOdoInfoSts : 346|1@0+ (1,0) [0|1] ""  IDM
 SG_ ABSActv : 347|1@0+ (1,0) [0|1] ""  IDM
 SG_ ESP_MILSts : 349|1@0+ (1,0) [0|1] ""  IDM
 SG_ EBDActv : 351|1@0+ (1,0) [0|1] "NoUnit"  IDM
 SG_ VehSpd : 332|13@0+ (0.05625,0) [0|299.98125] "kph"  IDM
 SG_ VehSpdVld : 333|1@0+ (1,0) [0|1] ""  IDM
 SG_ EBDFailSts : 334|1@0+ (1,0) [0|1] ""  IDM
 SG_ ABSFailSts : 335|1@0+ (1,0) [0|1] ""  IDM
 SG_ Checksum_ABS3 : 327|8@0+ (1,0) [0|255] ""  IDM
 SG_ RollingCounter_ESP4 : 315|4@0+ (1,0) [0|15] "NoUnit"  IDM
 SG_ EBDfailsts_RM : 317|2@0+ (1,0) [0|3] ""  IDM
 SG_ DrvTrqIncReqActv_FA : 318|1@0+ (1,0) [0|1] "NoUnit"  IDM
 SG_ DrvTrqRedReqActv_FA : 319|1@0+ (1,0) [0|1] "NoUnit"  IDM
 SG_ DrvTrqRedSlowReq_FA : 303|16@0+ (1,-3000) [-3000|14475] "Nm"  IDM
 SG_ DrvTrqRedFastReq_FA : 287|16@0+ (1,-3000) [-3000|14475] "NM"  IDM
 SG_ DrvTrqIncReq_FA : 271|16@0+ (1,-3000) [-3000|5000] "NM"  IDM
 SG_ Checksum_ESP4 : 263|8@0+ (1,0) [0|255] "NoUnit"  IDM
 SG_ RollingCounter_ESP7 : 251|4@0+ (1,0) [0|15] ""  IDM
 SG_ ESP_APS_GearBoxEna : 252|1@0+ (1,0) [0|1] ""  IDM
 SG_ ESP_APS_TgtGear : 242|3@0+ (1,0) [0|7] ""  IDM
 SG_ APS_EngTrqReqEna : 247|1@0+ (1,0) [0|1] ""  IDM
 SG_ EngTrqReq : 231|16@0+ (1,-16383) [-16383|16384] "Nm"  IDM
 SG_ LgtCtrlrFailr : 220|3@0+ (1,0) [0|7] ""  IDM
 SG_ LgtCtrlrSts : 223|3@0+ (1,0) [0|7] "NoUnit"  IDM
 SG_ ESP_MEBBrkAvail : 209|1@0+ (1,0) [0|1] "NoUnit"  IDM
 SG_ FourWhlsBrkTrq : 207|14@0+ (1,0) [0|16383] ""  IDM
 SG_ Checksum_ESP7 : 199|8@0+ (1,0) [0|255] ""  IDM
 SG_ RollingCounter_ESP1 : 187|4@0+ (1,0) [0|15] ""  IDM
 SG_ TrqMaxLim : 171|12@0+ (1,0) [0|4094] "Nm"  IDM
 SG_ ClutOpenReq : 173|2@0+ (1,0) [0|3] ""  IDM
 SG_ MSRActv_RA : 174|1@0+ (1,0) [0|1] ""  IDM
 SG_ IMC_Actv : 175|1@0+ (1,0) [0|1] ""  IDM
 SG_ ESP_MasterCylBrkPress : 159|16@0+ (0.03125,-42.5) [-42.5|425] "bar"  IDM
 SG_ ESP_MasterCylBrkPressVld : 144|1@0+ (1,0) [0|1] ""  IDM
 SG_ GearShftInhibitReq_FA : 145|1@0+ (1,0) [0|1] ""  IDM
 SG_ VDCActv : 148|1@0+ (1,0) [0|1] ""  IDM
 SG_ MSRActv : 149|1@0+ (1,0) [0|1] ""  IDM
 SG_ PTCActv : 150|1@0+ (1,0) [0|1] ""  IDM
 SG_ BTCActv : 151|1@0+ (1,0) [0|1] ""  IDM
 SG_ PTCActv_RA : 136|1@0+ (1,0) [0|1] ""  IDM
 SG_ BTCActv_RA : 137|1@0+ (1,0) [0|1] ""  IDM
 SG_ ESPFuncOffSts : 140|1@0+ (1,0) [0|1] ""  IDM
 SG_ ESPActvInfoLmp : 141|1@0+ (1,0) [0|1] ""  IDM
 SG_ ESPBrkLmpCtrl : 142|1@0+ (1,0) [0|1] ""  IDM
 SG_ ESPFailSts : 143|1@0+ (1,0) [0|1] ""  IDM
 SG_ Checksum_ESP1 : 135|8@0+ (1,0) [0|255] ""  IDM
 SG_ RollingCounter_ESP2 : 123|4@0+ (1,0) [0|15] ""  IDM
 SG_ SysOperatingMod_ESP : 127|4@0+ (1,0) [0|15] ""  IDM
 SG_ TAB_Sts : 113|2@0+ (1,0) [0|3] ""  IDM
 SG_ Shift_N_Warn : 114|1@0+ (1,0) [0|1] ""  IDM
 SG_ DrivingModDis : 119|5@0+ (1,0) [0|31] ""  IDM
 SG_ FOURLModShift_Flg : 105|1@0+ (1,0) [0|1] ""  IDM
 SG_ FOURL_Warn : 106|1@0+ (1,0) [0|1] ""  IDM
 SG_ Over_Spd_Warn : 107|1@0+ (1,0) [0|1] ""  IDM
 SG_ DrivingModReq_ESP : 96|5@0+ (1,0) [0|31] ""  IDM
 SG_ SS_func_off : 97|1@0+ (1,0) [0|1] ""  IDM
 SG_ AVHErrSts : 99|2@0+ (1,0) [0|3] ""  IDM
 SG_ AVHSts : 101|2@0+ (1,0) [0|3] ""  IDM
 SG_ CDPVld : 102|1@0+ (1,0) [0|1] ""  IDM
 SG_ CDPActv : 103|1@0+ (1,0) [0|1] "NoUnit"  IDM
 SG_ HDCFault : 89|2@0+ (1,0) [0|3] ""  IDM
 SG_ HDCCtrl : 91|2@0+ (1,0) [0|3] ""  IDM
 SG_ CDDActv : 92|1@0+ (1,0) [0|1] ""  IDM
 SG_ CDDAvailable : 93|1@0+ (1,0) [0|1] ""  IDM
 SG_ AWBAvailable : 94|1@0+ (1,0) [0|1] ""  IDM
 SG_ AWBActv : 95|1@0+ (1,0) [0|1] ""  IDM
 SG_ HHCSts : 80|1@0+ (1,0) [0|1] "NoUnit"  IDM
 SG_ AEBIBActv : 81|1@0+ (1,0) [0|1] ""  IDM
 SG_ AEBBAActv : 82|1@0+ (1,0) [0|1] ""  IDM
 SG_ AEBAvailable : 83|1@0+ (1,0) [0|1] ""  IDM
 SG_ ABPAvailable : 84|1@0+ (1,0) [0|1] ""  IDM
 SG_ ABPActv : 85|1@0+ (1,0) [0|1] ""  IDM
 SG_ ABAavailable : 86|1@0+ (1,0) [0|1] ""  IDM
 SG_ ABAActv : 87|1@0+ (1,0) [0|1] ""  IDM
 SG_ SCMActv : 72|1@0+ (1,0) [0|1] ""  IDM
 SG_ ESP_DiagActv : 73|1@0+ (1,0) [0|1] ""  IDM
 SG_ CTABrkAvailable : 74|1@0+ (1,0) [0|1] "NoUnit"  IDM
 SG_ BrkDskOvrheatd : 75|1@0+ (1,0) [0|1] ""  IDM
 SG_ NoBrkForce : 76|1@0+ (1,0) [0|1] ""  IDM
 SG_ VehStandstill : 78|2@0+ (1,0) [0|3] ""  IDM
 SG_ SwtOffCrsCtrl : 79|1@0+ (1,0) [0|1] ""  IDM
 SG_ Checksum_ESP2 : 71|8@0+ (1,0) [0|255] ""  IDM
 SG_ RWSAngLimnSts : 54|3@0+ (1,0) [0|7] "NoUnit"  IDM
 SG_ RWSAngLimnVld : 55|1@0+ (1,0) [0|1] "NoUnit"  IDM

BO_ 315 ESP_FD3: 64 GW
 SG_ MAC_Check_ESP_FD3 : 471|48@0+ (1,0) [0|281474976710655] ""  IDM
 SG_ FreshnessValue_ESP_FD3 : 455|16@0+ (1,0) [0|65535] ""  IDM
 SG_ RollingCounter_ABS2 : 379|4@0+ (1,0) [0|15] ""  IDM
 SG_ WssRREdgesSumVld : 382|1@0+ (1,0) [0|1] ""  IDM
 SG_ WssRLEdgesSumVld : 383|1@0+ (1,0) [0|1] ""  IDM
 SG_ WssRLEdgesSum : 375|8@0+ (1,0) [0|255] ""  IDM
 SG_ WssRREdgesSum : 367|8@0+ (1,0) [0|255] ""  IDM
 SG_ RRWheelSpd : 348|13@0+ (0.05625,0) [0|299.98125] "km/h"  IDM
 SG_ RRWheelSpdVld : 349|1@0+ (1,0) [0|1] ""  IDM
 SG_ RRWheelDriveDirection : 351|2@0+ (1,0) [0|3] ""  IDM
 SG_ RLWheelSpd : 332|13@0+ (0.05625,0) [0|299.98125] "km/h"  IDM
 SG_ RLWheelSpdVld : 333|1@0+ (1,0) [0|1] ""  IDM
 SG_ RLWheelDriveDirection : 335|2@0+ (1,0) [0|3] ""  IDM
 SG_ Checksum_ABS2 : 327|8@0+ (1,0) [0|255] ""  IDM
 SG_ RollingCounter_ESP9 : 315|4@0+ (1,0) [0|14] ""  IDM
 SG_ IBC_RwsAngReq : 311|12@0+ (0.01,-10) [-10|10] "Deg"  IDM
 SG_ WheelSpdSnsr_GenDir : 294|1@0+ (1,0) [0|1] ""  IDM
 SG_ WheelSpdSnsrGeneralErr : 295|1@0+ (1,0) [0|1] ""  IDM
 SG_ RRWheelSpdSnsr_Dir : 280|1@0+ (1,0) [0|1] ""  IDM
 SG_ RRWheelSpdSnsr_UnderLineFail : 281|1@0+ (1,0) [0|1] ""  IDM
 SG_ RRWheelSpdSnsr_MultiSigFail : 282|1@0+ (1,0) [0|1] ""  IDM
 SG_ RRWheelSpdSnsr_Open : 283|1@0+ (1,0) [0|1] ""  IDM
 SG_ RRWheelSpdSnsr_ShortUBAT : 284|1@0+ (1,0) [0|1] ""  IDM
 SG_ RRWheelSpdSnsr_GND : 285|1@0+ (1,0) [0|1] ""  IDM
 SG_ RLWheelSpdSnsr_Dir : 286|1@0+ (1,0) [0|1] ""  IDM
 SG_ RLWheelSpdSnsr_UnderLineFail : 287|1@0+ (1,0) [0|1] ""  IDM
 SG_ RLWheelSpdSnsr_MultiSigFail : 272|1@0+ (1,0) [0|1] ""  IDM
 SG_ RLWheelSpdSnsr_Open : 273|1@0+ (1,0) [0|1] ""  IDM
 SG_ RLWheelSpdSnsr_ShortUBAT : 274|1@0+ (1,0) [0|1] ""  IDM
 SG_ RLWheelSpdSnsr_GND : 275|1@0+ (1,0) [0|1] ""  IDM
 SG_ FRWheelSpdSnsr_Dir : 276|1@0+ (1,0) [0|1] ""  IDM
 SG_ FRWheelSpdSnsr_UnderLineFail : 277|1@0+ (1,0) [0|1] ""  IDM
 SG_ FRWheelSpdSnsr_MultiSigFail : 278|1@0+ (1,0) [0|1] ""  IDM
 SG_ FRWheelSpdSnsr_Open : 279|1@0+ (1,0) [0|1] ""  IDM
 SG_ FRWheelSpdSnsr_ShortUBAT : 264|1@0+ (1,0) [0|1] ""  IDM
 SG_ FRWheelSpdSnsr_GND : 265|1@0+ (1,0) [0|1] ""  IDM
 SG_ FLWheelSpdSnsr_Dir : 266|1@0+ (1,0) [0|1] ""  IDM
 SG_ FLWheelSpdSnsr_UnderLineFail : 267|1@0+ (1,0) [0|1] ""  IDM
 SG_ FLWheelSpdSnsr_MultiSigFail : 268|1@0+ (1,0) [0|1] ""  IDM
 SG_ FLWheelSpdSnsr_Open : 269|1@0+ (1,0) [0|1] ""  IDM
 SG_ FLWheelSpdSnsr_ShortUBAT : 270|1@0+ (1,0) [0|1] ""  IDM
 SG_ FLWheelSpdSnsr_GND : 271|1@0+ (1,0) [0|1] ""  IDM
 SG_ Checksum_ESP9 : 263|8@0+ (1,0) [0|255] ""  IDM
 SG_ RollingCounter_ESP13 : 251|4@0+ (1,0) [0|14] ""  IDM
 SG_ IBC_RwsCtrlMod : 253|2@0+ (1,0) [0|3] ""  IDM
 SG_ DrvTrqIncReqActv_RA : 255|1@0+ (1,0) [0|1] "NoUnit"  IDM
 SG_ DrvTrqRedReqActv_RA : 232|1@0+ (1,0) [0|1] "NoUnit"  IDM
 SG_ MSRVld : 233|1@0+ (1,0) [0|1] ""  IDM
 SG_ GearShftInhibitReq_RA : 239|1@0+ (1,0) [0|1] ""  IDM
 SG_ DrvTrqRedReq_RA : 223|16@0+ (1,-6000) [-6000|14475] "Nm"  IDM
 SG_ DrvTrqIncReq_RA : 207|16@0+ (1,-6000) [-6000|14475] "Nm"  IDM
 SG_ Checksum_ESP13 : 199|8@0+ (1,0) [0|255] ""  IDM
 SG_ RollingCounter_ESP8 : 187|4@0+ (1,0) [0|14] ""  IDM
 SG_ BumpSts : 188|1@0+ (1,0) [0|1] ""  IDM
 SG_ DrivingModShiftLimn : 191|3@0+ (1,0) [0|7] ""  IDM
 SG_ CCO_TrqReq : 175|16@0+ (0.0030518,-100) [-100|99.999713] "Perc"  IDM
 SG_ CCO_TgtVel : 164|5@0+ (1,2.6) [2.6|33.6] "kph"  IDM
 SG_ HBASts : 165|1@0+ (1,0) [0|1] ""  IDM
 SG_ CCO_Warn : 167|2@0+ (1,0) [0|3] ""  IDM
 SG_ EspFuncOffSts_mode : 152|1@0+ (1,0) [0|1] ""  IDM
 SG_ CCO_Active : 159|2@0+ (1,0) [0|3] ""  IDM
 SG_ DrivingModShiftLimnDisp : 144|1@0+ (1,0) [0|1] ""  IDM
 SG_ SSASts : 150|3@0+ (1,0) [0|7] ""  IDM
 SG_ Checksum_ESP8 : 135|8@0+ (1,0) [0|255] ""  IDM
 SG_ RollingCounter_EPB1 : 123|4@0+ (1,0) [0|15] ""  IDM
 SG_ ESP_DSTSts : 116|3@0+ (1,0) [0|7] ""  IDM
 SG_ ESP_DSTTrqReqDir : 117|1@0+ (1,0) [0|1] ""  IDM
 SG_ ESP_DSTTrqReq : 111|10@0+ (0.01,0) [0|8] "Nm"  IDM
 SG_ EPBTextDisp : 103|4@0+ (1,0) [0|15] ""  IDM
 SG_ EPBRedLmpSts : 89|2@0+ (1,0) [0|3] "NoUnit"  IDM
 SG_ EPBErrSts : 91|2@0+ (1,0) [0|3] ""  IDM
 SG_ EPBSts : 93|2@0+ (1,0) [0|3] ""  IDM
 SG_ EPB_SwtPosn : 95|2@0+ (1,0) [0|3] ""  IDM
 SG_ EPB_SwtPosnVld : 80|1@0+ (1,0) [0|1] ""  IDM
 SG_ PressBrakePedalPointOut : 81|1@0+ (1,0) [0|1] ""  IDM
 SG_ EPB_VirtSwtAvailable : 85|1@0+ (1,0) [0|1] ""  IDM
 SG_ Checksum_EPB1 : 71|8@0+ (1,0) [0|255] ""  IDM
 SG_ RollingCounter_ABS1 : 59|4@0+ (1,0) [0|15] ""  IDM
 SG_ WssFREdgesSumVld : 62|1@0+ (1,0) [0|1] ""  IDM
 SG_ WssFLEdgesSumVld : 63|1@0+ (1,0) [0|1] ""  IDM
 SG_ WssFREdgesSum : 55|8@0+ (1,0) [0|255] ""  IDM
 SG_ WssFLEdgesSum : 47|8@0+ (1,0) [0|255] ""  IDM
 SG_ FRWheelSpd : 28|13@0+ (0.05625,0) [0|299.98125] "km/h"  IDM
 SG_ FRWheelSpdVld : 29|1@0+ (1,0) [0|1] ""  IDM
 SG_ FRWheelDriveDirection : 31|2@0+ (1,0) [0|3] ""  IDM
 SG_ FLWheelSpd : 12|13@0+ (0.05625,0) [0|299.98125] "km/h"  IDM
 SG_ FLWheelSpdVld : 13|1@0+ (1,0) [0|1] ""  IDM
 SG_ FLWheelDriveDirection : 15|2@0+ (1,0) [0|3] ""  IDM
 SG_ Checksum_ABS1 : 7|8@0+ (1,0) [0|255] ""  IDM

BO_ 327 EPS_FD1: 64 GW
 SG_ RollingCounter_EPS3 : 187|4@0+ (1,0) [0|15] "NoUnit"  IDM
 SG_ EPS_HADHndShkRespSt : 190|3@0+ (1,0) [0|7] "NoUnit"  IDM
 SG_ EPS_AngCmdOverRange : 191|1@0+ (1,0) [0|1] "NoUnit"  IDM
 SG_ EPS_AvailStsforHAD : 177|2@0+ (1,0) [0|3] "NoUnit"  IDM
 SG_ EPS_SteerWheelAngVld : 178|1@0+ (1,0) [0|1] "NoUnit"  IDM
 SG_ EPS_HADerror_Reason : 183|4@0+ (1,0) [0|15] "NoUnit"  IDM
 SG_ EPS_SteerWheelSpdSign : 168|1@0+ (1,0) [0|1] "NoUnit"  IDM
 SG_ EPS_SteerWheelSpd : 167|15@0+ (0.1,0) [0|1016] "DegPerSec"  IDM
 SG_ EPS_SteerWheelAngSign : 152|1@0+ (1,0) [0|1] "NoUnit"  IDM
 SG_ EPS_SteerWheelAng : 151|15@0+ (0.1,0) [0|780] "deg"  IDM
 SG_ Checksum_EPS3 : 135|8@0+ (1,0) [0|255] "NoUnit"  IDM
 SG_ RollingCounter_EPS2 : 123|4@0+ (1,0) [0|15] ""  IDM
 SG_ EPS_LKATrqOvlDlvdSts : 125|2@0+ (1,0) [0|3] ""  IDM
 SG_ EPS_DrvInpTrqVal_HighResVld : 126|1@0+ (1,0) [0|1] "NoUnit"  IDM
 SG_ EPS_LKATorqOvrlDlvdVld : 127|1@0+ (1,0) [0|1] ""  IDM
 SG_ EPS_LKATorqOvrlDlvd : 111|16@0+ (0.01,-15) [-15|15] "Nm"  IDM
 SG_ EPS_LKAAngDlvdSts : 83|2@0+ (1,0) [0|3] ""  IDM
 SG_ EPS_DrvInpTrqVal_HighReslolution : 79|12@0+ (0.015625,-31.984375) [-31.984375|32] "Nm"  IDM
 SG_ Checksum_EPS2 : 71|8@0+ (1,0) [0|255] ""  IDM
 SG_ RollingCounter_EPS1 : 59|4@0+ (1,0) [0|15] ""  IDM
 SG_ EPS_SteerMod : 55|3@0+ (1,0) [0|7] ""  IDM
 SG_ SteerSysFltTyp : 39|4@0+ (1,0) [0|15] "NoUnit"  IDM
 SG_ EPS_AvailSts : 29|2@0+ (1,0) [0|3] ""  IDM
 SG_ EPS_InterferDetdVld : 30|1@0+ (1,0) [0|1] ""  IDM
 SG_ EPS_InterferDetd : 31|1@0+ (1,0) [0|1] ""  IDM
 SG_ EPS_DSTCtrlSts : 11|3@0+ (1,0) [0|7] ""  IDM
 SG_ EPS_FailSts : 13|2@0+ (1,0) [0|3] ""  IDM
 SG_ EPS_TrqSnsrSts : 14|1@0+ (1,0) [0|1] ""  IDM
 SG_ Checksum_EPS1 : 7|8@0+ (1,0) [0|255] ""  IDM

BO_ 338 ELD1: 8 GW
 SG_ RearELDLckSts : 39|4@0+ (1,0) [0|15] "NoUnit"  IDM

BO_ 357 CSA1: 8 GW
 SG_ TurnLmpSwtErrSts : 62|1@0+ (1,0) [0|1] "NoUnit"  IDM
 SG_ LowBeamSwtSts : 24|1@0+ (1,0) [0|1] "NoUnit"  IDM
 SG_ HiBeamSwtSts : 25|1@0+ (1,0) [0|1] ""  IDM
 SG_ OverVehBeamSwtSts : 26|1@0+ (1,0) [0|1] "NoUnit"  IDM
 SG_ AutoLmpSwtSts : 28|1@0+ (1,0) [0|1] "NoUnit"  IDM
 SG_ RLSSensitivityReq : 18|3@0+ (1,0) [0|7] ""  IDM
 SG_ LTurnLmpSwtSts : 19|1@0+ (1,0) [0|1] ""  IDM
 SG_ RTurnLmpSwtSts : 20|1@0+ (1,0) [0|1] ""  IDM
 SG_ FrntFogLmpSwtSts : 22|1@0+ (1,0) [0|1] "NoUnit"  IDM
 SG_ FrntWiprSwtSts : 10|3@0+ (1,0) [0|7] ""  IDM
 SG_ FrntWshrSwtSts : 12|2@0+ (1,0) [0|3] ""  IDM

BO_ 388 VCU_FD28: 16 GW
 SG_ RollingCounter_VCU_FD28_2 : 123|4@0+ (1,0) [0|14] "NoUnit"  IDM
 SG_ RRIntgrtdWheelSpd : 81|14@0+ (0.01,-25.01) [-25|138] "mps"  IDM
 SG_ RLIntgrtdWheelSpd : 79|14@0+ (0.01,-25.01) [-25|138] "mps"  IDM
 SG_ Checksum_VCU_FD28_2 : 71|8@0+ (1,0) [0|255] "NoUnit"  IDM
 SG_ RollingCounter_VCU_FD28_1 : 59|4@0+ (1,0) [0|14] "NoUnit"  IDM
 SG_ EstimrResutReliabt : 61|2@0+ (1,0) [0|3] "NoUnit"  IDM
 SG_ EstimdRoadFricCoeff : 53|5@0+ (0.05,-0.05) [0|1] "NoUnit"  IDM
 SG_ FRIntgrtdWheelSpd : 35|14@0+ (0.01,-25.01) [-25|138] "mps"  IDM
 SG_ FLIntgrtdWheelSpd : 17|14@0+ (0.01,-25.01) [-25|138] "mps"  IDM
 SG_ IntgrtdVehSpd : 15|14@0+ (0.01,-25.01) [-25|138] "mps"  IDM
 SG_ Checksum_VCU_FD28_1 : 7|8@0+ (1,0) [0|255] "NoUnit"  IDM

BO_ 474 HUT_FD4: 64 GW
 SG_ OneclickClsIntellgntDrvgReq : 147|2@0+ (1,0) [0|3] "NoUnit"  IDM
 SG_ OutdPrkgReq : 149|2@0+ (1,0) [0|3] "NoUnit"  IDM
 SG_ CamFolwSwtReq : 140|1@0+ (1,0) [0|1] "NoUnit"  IDM
 SG_ PrkModReq : 57|2@0+ (1,0) [0|3] "NoUnit"  IDM
 SG_ TJA_ASCruise : 59|2@0+ (1,0) [0|3] "NoUnit"  IDM
 SG_ RCTA_DispSwtReq : 60|1@0+ (1,0) [0|1] "NoUnit"  IDM
 SG_ AutoPrkOutSwtReq : 61|1@0+ (1,0) [0|1] "NoUnit"  IDM
 SG_ PrkgSlotId : 55|10@0+ (1,0) [1|1023] "NoUnit"  IDM
 SG_ HAVP_UseMod : 41|2@0+ (1,0) [0|3] "NoUnit"  IDM
 SG_ HUT_HAVP_APA_Permit : 43|2@0+ (1,0) [0|3] ""  IDM
 SG_ UserDefinedParkCmd : 44|1@0+ (1,0) [0|1] ""  IDM
 SG_ SlotNum_VR : 35|4@0+ (1,0) [0|15] ""  IDM
 SG_ UserDefPrkMenuSelCmd : 18|3@0+ (1,0) [0|7] ""  IDM
 SG_ HUT_HAVP_Set_Path_Ending : 21|1@0+ (1,0) [0|1] ""  IDM
 SG_ HUT_HAVP_Comfirm_Btn : 8|1@0+ (1,0) [0|1] ""  IDM
 SG_ HUT_HAVP_SelfParLot_Ending : 9|1@0+ (1,0) [0|1] ""  IDM
 SG_ HUT_HAVP_Set_Starting : 10|1@0+ (1,0) [0|1] ""  IDM
 SG_ BackReq_RPA : 15|1@0+ (1,0) [0|1] "NoUnit"  IDM
 SG_ SteerWheelsilentReq : 1|2@0+ (1,0) [0|3] "NoUnit"  IDM

BO_ 489 HUT30: 8 GW
 SG_ BackReq_AVM : 13|1@0+ (1,0) [0|1] ""  IDM

BO_ 490 BLE2: 8 GW
 SG_ RmtPrkRadShieldSet : 34|2@0+ (1,0) [0|3] "NoUnit"  IDM

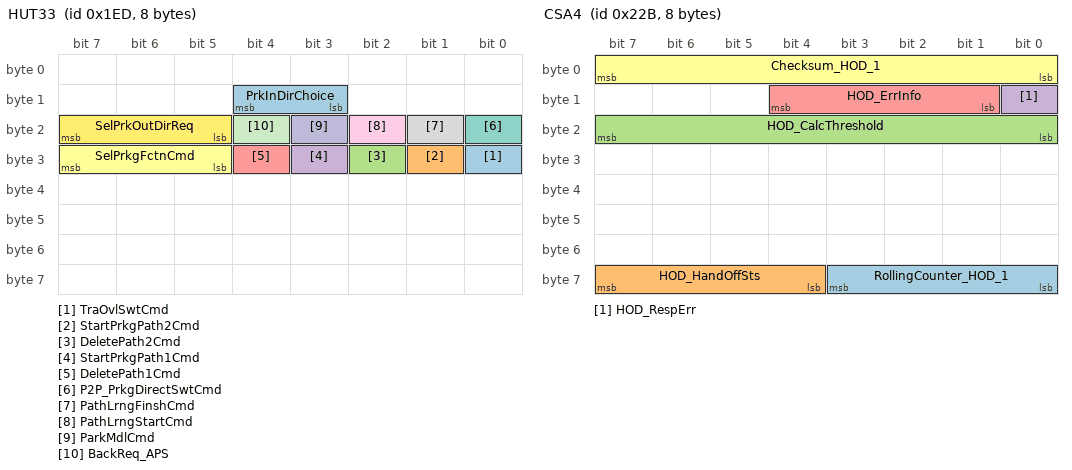
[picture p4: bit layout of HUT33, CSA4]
BO_ 493 HUT33: 8 GW
 SG_ TraOvlSwtCmd : 24|1@0+ (1,0) [0|1] "NoUnit"  IDM
 SG_ StartPrkgPath2Cmd : 25|1@0+ (1,0) [0|1] ""  IDM
 SG_ DeletePath2Cmd : 26|1@0+ (1,0) [0|1] ""  IDM
 SG_ StartPrkgPath1Cmd : 27|1@0+ (1,0) [0|1] ""  IDM
 SG_ DeletePath1Cmd : 28|1@0+ (1,0) [0|1] ""  IDM
 SG_ SelPrkgFctnCmd : 31|3@0+ (1,0) [0|7] ""  IDM
 SG_ P2P_PrkgDirectSwtCmd : 16|1@0+ (1,0) [0|1] ""  IDM
 SG_ PathLrngFinshCmd : 17|1@0+ (1,0) [0|1] ""  IDM
 SG_ PathLrngStartCmd : 18|1@0+ (1,0) [0|1] ""  IDM
 SG_ ParkMdlCmd : 19|1@0+ (1,0) [0|1] ""  IDM
 SG_ BackReq_APS : 20|1@0+ (1,0) [0|1] ""  IDM
 SG_ SelPrkOutDirReq : 23|3@0+ (1,0) [0|7] ""  IDM
 SG_ PrkInDirChoice : 12|2@0+ (1,0) [0|3] ""  IDM

BO_ 494 HUT15: 16 GW
 SG_ APSSwtReq_VR : 55|2@0+ (1,0) [0|3] ""  IDM
 SG_ APSPrkgTypSeln : 34|2@0+ (1,0) [0|3] ""  IDM
 SG_ SDWSwtSet : 39|1@0+ (1,0) [0|1] ""  IDM

BO_ 545 DCT5: 8 GW
 SG_ RollingCounter_DCT5 : 59|4@0+ (1,0) [0|15] ""  IDM
 SG_ ShiftLeverPosn_SBWM : 62|3@0+ (1,0) [0|7] "NoUnit"  IDM
 SG_ TRANS_Warning_LAMP : 63|1@0+ (1,0) [0|1] ""  IDM
 SG_ TGS_LEVER : 51|4@0+ (1,0) [0|15] ""  IDM
 SG_ CURRENT_GEAR : 55|4@0+ (1,0) [0|15] ""  IDM
 SG_ TCU_OSS : 39|14@0+ (1,0) [0|10000] "rpm"  IDM
 SG_ TARGET_GEAR : 27|4@0+ (1,0) [0|15] ""  IDM
 SG_ TCU_APS_Available : 28|1@0+ (1,0) [0|1] ""  IDM
 SG_ ShiftInPrgValid : 31|1@0+ (1,0) [0|1] ""  IDM
 SG_ TargetGearValid : 16|1@0+ (1,0) [0|1] ""  IDM
 SG_ SHIFT_IN_PROGRESS : 17|1@0+ (1,0) [0|1] ""  IDM
 SG_ CurrentGearValid : 18|1@0+ (1,0) [0|1] ""  IDM
 SG_ TCUDrivingMode : 23|5@0+ (1,0) [0|31] ""  IDM
 SG_ TCU_ESP_DriverIntervention : 8|1@0+ (1,0) [0|1] ""  IDM
 SG_ TGS_LEVERValid : 9|1@0+ (1,0) [0|1] "NoUnit"  IDM
 SG_ TCU_PEPSAuthReq : 10|1@0+ (1,0) [0|1] ""  IDM
 SG_ TrsmShaftDirection : 12|2@0+ (1,0) [0|3] ""  IDM
 SG_ Checksum_DCT5 : 7|8@0+ (1,0) [0|255] ""  IDM

BO_ 555 CSA4: 8 GW
 SG_ RollingCounter_HOD_1 : 59|4@0+ (1,0) [0|14] "NoUnit"  IDM
 SG_ HOD_HandOffSts : 63|4@0+ (1,0) [0|15] "NoUnit"  IDM
 SG_ HOD_CalcThreshold : 23|8@0+ (1,0) [0|254] ""  IDM
 SG_ HOD_RespErr : 8|1@0+ (1,0) [0|1] "NoUnit"  IDM
 SG_ HOD_ErrInfo : 12|4@0+ (1,0) [0|15] "NoUnit"  IDM
 SG_ Checksum_HOD_1 : 7|8@0+ (1,0) [0|255] "NoUnit"  IDM

BO_ 565 DCT7: 8 GW
 SG_ DrvFaiMsg : 36|4@0+ (1,0) [0|15] "NoUnit"  IDM

BO_ 570 CSA5: 8 GW
 SG_ CustomSwtSts_Park : 13|2@0+ (1,0) [0|3] "NoUnit"  IDM

CM_ SG_ 719 ILC_InterSysInfoDisp "/";
CM_ SG_ 786 ADCCoolReq "/";
CM_ SG_ 837 EnvModDetn "/";
CM_ SG_ 473 OTApowertrainmode "升级过程中对高压ON/OFF的需求，切换请求";
CM_ SG_ 699 OTA_UpgrdModSts "/";
CM_ SG_ 783 ACZoneSwtErrSts "/";
CM_ SG_ 783 ACZoneSwtSts "/";
CM_ SG_ 259 IdleSpdSts "/";
CM_ SG_ 259 IdleCtrlWhlTrq "/";
CM_ SG_ 259 RollingCounter_ECM2 "/";
CM_ SG_ 259 EngState "/";
CM_ SG_ 259 AccelPedalPosnVldty "/";
CM_ SG_ 259 AccelPedalPosn "/";
CM_ SG_ 259 Checksum_ECM2 "/";
CM_ SG_ 259 RollingCounter_ECM9 "/";
CM_ SG_ 259 AccelPedlPosnDiagc "/";
CM_ SG_ 259 Checksum_ECM9 "/";
CM_ SG_ 283 HCU_VirtLoad_FA "/";
CM_ SG_ 283 AccrPedlAntiMsstpngSts "/";
CM_ SG_ 283 IOTACoolingResp "/";
CM_ SG_ 283 VCU_MaxSpdLimit "/";
CM_ SG_ 283 ActTotWheelTrq "/";
CM_ SG_ 283 MaxPsblPosWheelTrq "/";
CM_ SG_ 283 MinPsblNegWheelTrq "/";
CM_ SG_ 283 PTDrvMod "/";
CM_ SG_ 283 DrvMod "/";
CM_ SG_ 283 VCU_ACCComIf "/";
CM_ SG_ 283 ActDrvMod "/";
CM_ SG_ 302 CST_Status "/";
CM_ SG_ 302 BrkFldWarn "/";
CM_ SG_ 302 IBCSysSts "/";
CM_ SG_ 302 SimtorPressSts "/";
CM_ SG_ 302 SimtorPress "/";
CM_ SG_ 311 VehOdoInfo "/";
CM_ SG_ 311 VehOdoInfoSts "/";
CM_ SG_ 311 ESP_MILSts "/";
CM_ SG_ 311 EBDfailsts_RM "/";
CM_ SG_ 311 DrvTrqRedSlowReq_FA "/";
CM_ SG_ 311 ESP_APS_GearBoxEna "/";
CM_ SG_ 311 ESP_APS_TgtGear "/";
CM_ SG_ 311 TrqMaxLim "/";
CM_ SG_ 311 ClutOpenReq "/";
CM_ SG_ 311 IMC_Actv "/";
CM_ SG_ 311 GearShftInhibitReq_FA "/";
CM_ SG_ 311 ESPActvInfoLmp "/";
CM_ SG_ 311 SysOperatingMod_ESP "/";
CM_ SG_ 311 TAB_Sts "/";
CM_ SG_ 311 Shift_N_Warn "/";
CM_ SG_ 311 DrivingModDis "/";
CM_ SG_ 311 FOURLModShift_Flg "/";
CM_ SG_ 311 FOURL_Warn "/";
CM_ SG_ 311 Over_Spd_Warn "/";
CM_ SG_ 311 SS_func_off "/";
CM_ SG_ 311 CDPVld "/";
CM_ SG_ 311 HDCFault "/";
CM_ SG_ 311 SCMActv "/";
CM_ SG_ 311 SwtOffCrsCtrl "/";
CM_ SG_ 315 RollingCounter_ESP9 "/";
CM_ SG_ 315 IBC_RwsAngReq "/";
CM_ SG_ 315 WheelSpdSnsr_GenDir "/";
CM_ SG_ 315 WheelSpdSnsrGeneralErr "/";
CM_ SG_ 315 RRWheelSpdSnsr_Dir "/";
CM_ SG_ 315 RRWheelSpdSnsr_UnderLineFail "/";
CM_ SG_ 315 RRWheelSpdSnsr_MultiSigFail "/";
CM_ SG_ 315 RRWheelSpdSnsr_Open "/";
CM_ SG_ 315 RRWheelSpdSnsr_ShortUBAT "/";
CM_ SG_ 315 RRWheelSpdSnsr_GND "/";
CM_ SG_ 315 RLWheelSpdSnsr_Dir "/";
CM_ SG_ 315 RLWheelSpdSnsr_UnderLineFail "/";
CM_ SG_ 315 RLWheelSpdSnsr_MultiSigFail "/";
CM_ SG_ 315 RLWheelSpdSnsr_Open "/";
CM_ SG_ 315 RLWheelSpdSnsr_ShortUBAT "/";
CM_ SG_ 315 RLWheelSpdSnsr_GND "/";
CM_ SG_ 315 FRWheelSpdSnsr_Dir "/";
CM_ SG_ 315 FRWheelSpdSnsr_UnderLineFail "/";
CM_ SG_ 315 FRWheelSpdSnsr_MultiSigFail "/";
CM_ SG_ 315 FRWheelSpdSnsr_Open "/";
CM_ SG_ 315 FRWheelSpdSnsr_ShortUBAT "/";
CM_ SG_ 315 FRWheelSpdSnsr_GND "/";
CM_ SG_ 315 FLWheelSpdSnsr_Dir "/";
CM_ SG_ 315 FLWheelSpdSnsr_UnderLineFail "/";
CM_ SG_ 315 FLWheelSpdSnsr_MultiSigFail "/";
CM_ SG_ 315 FLWheelSpdSnsr_Open "/";
CM_ SG_ 315 FLWheelSpdSnsr_ShortUBAT "/";
CM_ SG_ 315 FLWheelSpdSnsr_GND "/";
CM_ SG_ 315 Checksum_ESP9 "/";
CM_ SG_ 315 RollingCounter_ESP13 "/";
CM_ SG_ 315 IBC_RwsCtrlMod "/";
CM_ SG_ 315 MSRVld "/";
CM_ SG_ 315 GearShftInhibitReq_RA "/";
CM_ SG_ 315 Checksum_ESP13 "/";
CM_ SG_ 315 RollingCounter_ESP8 "/";
CM_ SG_ 315 BumpSts "/";
CM_ SG_ 315 DrivingModShiftLimn "/";
CM_ SG_ 315 CCO_TrqReq "/";
CM_ SG_ 315 CCO_TgtVel "/";
CM_ SG_ 315 HBASts "/";
CM_ SG_ 315 CCO_Warn "/";
CM_ SG_ 315 EspFuncOffSts_mode "/";
CM_ SG_ 315 CCO_Active "/";
CM_ SG_ 315 DrivingModShiftLimnDisp "/";
CM_ SG_ 315 SSASts "/";
CM_ SG_ 315 Checksum_ESP8 "/";
CM_ SG_ 315 ESP_DSTTrqReqDir "/";
CM_ SG_ 315 ESP_DSTTrqReq "/";
CM_ SG_ 315 EPBTextDisp "/";
CM_ SG_ 315 PressBrakePedalPointOut "/";
CM_ SG_ 315 EPB_VirtSwtAvailable "/";
CM_ SG_ 357 RLSSensitivityReq "/";
CM_ SG_ 388 RollingCounter_VCU_FD28_2 "/";
CM_ SG_ 388 Checksum_VCU_FD28_2 "/";
CM_ SG_ 388 RollingCounter_VCU_FD28_1 "/";
CM_ SG_ 388 Checksum_VCU_FD28_1 "/";
CM_ SG_ 474 TJA_ASCruise "A";
CM_ SG_ 474 UserDefinedParkCmd "自选车位功能";
CM_ SG_ 474 UserDefPrkMenuSelCmd "自选车位功能";
CM_ SG_ 474 BackReq_RPA "/";
CM_ SG_ 545 TRANS_Warning_LAMP "/";
CM_ SG_ 545 TCU_OSS "/";
CM_ SG_ 545 TCUDrivingMode "/";
CM_ SG_ 545 TCU_ESP_DriverIntervention "/";
CM_ SG_ 545 TCU_PEPSAuthReq "/";
CM_ SG_ 545 TrsmShaftDirection "/";
CM_ SG_ 555 HOD_CalcThreshold "/";
BA_DEF_ BO_  "GenMsgILSupport" ENUM  "No","Yes";
BA_DEF_ BO_  "VFrameFormat" ENUM  "StandardCAN","ExtendedCAN","reserved","reserved","reserved","reserved","reserved","reserved","reserved","reserved","reserved","reserved","reserved","reserved","StandardCAN_FD","ExtendedCAN_FD";
BA_DEF_ BO_  "DiagState" ENUM  "No","Yes";
BA_DEF_ BO_  "DiagRequest" ENUM  "No","Yes";
BA_DEF_ BO_  "DiagResponse" ENUM  "No","Yes";
BA_DEF_ BO_  "NmAsrMessage" ENUM  "No","Yes";
BA_DEF_ SG_  "GenSigSendType" ENUM  "Cyclic","OnWrite","OnWriteWithRepetition","OnChange","OnChangeWithRepetition","IfActive","IfActiveWithRepetition","NoSigSendType","CyclicAndSpontanX","NotUsed","Event","CE";
BA_DEF_ SG_  "IsMonitor" ENUM  "*","Monitor";
BA_DEF_ SG_  "UnitConversionFactor" FLOAT -100 100;
BA_DEF_ SG_  "SigInvalidSetFlag" ENUM  "*","Yes";
BA_DEF_ SG_  "Internal_type" ENUM  "*","UB","UW","UL","SB","SW","SL";
BA_DEF_ SG_  "IsCrcSignal" ENUM  "No","Yes";
BA_DEF_ SG_  "IsRcSignal" ENUM  "No","Yes";
BA_DEF_ BO_  "GenMsgSendType" ENUM  "Cyclic","Event","CE","NotUsed","NotUsed","NotUsed","NotUsed","NotUsed","NoMsgSendType","IfActive","IfActiveWithRepetition","CyclicAndSpontanX";
BA_DEF_ SG_  "GenSigStartValue" INT 0 2147483647;
BA_DEF_ SG_  "GenSigInactiveValue" INT 0 2147483647;
BA_DEF_ BO_  "MsgType" ENUM  "Normal","NM","Diag","";
BA_DEF_ BO_  "GenMsgCycleTime" INT 0 65535;
BA_DEF_DEF_  "GenMsgILSupport" "Yes";
BA_DEF_DEF_  "VFrameFormat" "StandardCAN";
BA_DEF_DEF_  "DiagState" "No";
BA_DEF_DEF_  "DiagRequest" "No";
BA_DEF_DEF_  "DiagResponse" "No";
BA_DEF_DEF_  "NmAsrMessage" "No";
BA_DEF_DEF_  "GenSigSendType" "Cyclic";
BA_DEF_DEF_  "IsMonitor" "*";
BA_DEF_DEF_  "UnitConversionFactor" 1;
BA_DEF_DEF_  "SigInvalidSetFlag" "*";
BA_DEF_DEF_  "Internal_type" "*";
BA_DEF_DEF_  "IsCrcSignal" "No";
BA_DEF_DEF_  "IsRcSignal" "No";
BA_DEF_DEF_  "GenMsgSendType" "Cyclic";
BA_DEF_DEF_  "GenSigStartValue" 0;
BA_DEF_DEF_  "GenSigInactiveValue" 0;
BA_DEF_DEF_  "MsgType" "";
BA_DEF_DEF_  "GenMsgCycleTime" 0;
BA_ "VFrameFormat" BO_ 719 14;
BA_ "MsgType" BO_ 719 0;
BA_ "GenMsgCycleTime" BO_ 719 100;
BA_ "GenSigInactiveValue" SG_ 719 Grid_Mark_Detn 3;
BA_ "GenSigInactiveValue" SG_ 719 Zebra_Mark_Detn 3;
BA_ "GenSigInactiveValue" SG_ 719 Stop_Mark_Detn 3;
BA_ "GenSigInactiveValue" SG_ 719 RollingCounter_IFC7 15;
BA_ "IsRcSignal" SG_ 719 RollingCounter_IFC7 1;
BA_ "GenSigInactiveValue" SG_ 719 IDC_L2_FWiperReq 7;
BA_ "GenSigStartValue" SG_ 719 TSR_Snvty 15;
BA_ "GenSigInactiveValue" SG_ 719 TSR_Snvty 31;
BA_ "GenSigInactiveValue" SG_ 719 TSRTrfcSignVal 255;
BA_ "GenSigInactiveValue" SG_ 719 TSRSpdLim 63;
BA_ "GenSigInactiveValue" SG_ 719 TSRSts 4;
BA_ "GenSigStartValue" SG_ 719 TSRSpdLimUnit 1;
BA_ "IsCrcSignal" SG_ 719 Checksum_IFC7 1;
BA_ "GenSigInactiveValue" SG_ 719 TSRConSpdLim 63;
BA_ "VFrameFormat" BO_ 395 14;
BA_ "MsgType" BO_ 395 0;
BA_ "GenMsgCycleTime" BO_ 395 20;
BA_ "GenSigInactiveValue" SG_ 395 RollingCounter_AEB6 15;
BA_ "IsRcSignal" SG_ 395 RollingCounter_AEB6 1;
BA_ "IsCrcSignal" SG_ 395 Checksum_AEB6 1;
BA_ "GenSigInactiveValue" SG_ 395 RollingCounter_AEB1 15;
BA_ "IsRcSignal" SG_ 395 RollingCounter_AEB1 1;
BA_ "GenSigInactiveValue" SG_ 395 IntellgntAsscRoadTypConfid 15;
BA_ "GenSigInactiveValue" SG_ 395 IntellgntAsscRoadTyp 15;
BA_ "GenSigInactiveValue" SG_ 395 AEB_TgtDecel_ReqValue 65535;
BA_ "IsCrcSignal" SG_ 395 Checksum_AEB1 1;
BA_ "GenSigInactiveValue" SG_ 395 ADAS_ErrSts 1;
BA_ "GenSigStartValue" SG_ 395 TimeToCllsn 250;
BA_ "VFrameFormat" BO_ 576 14;
BA_ "MsgType" BO_ 576 0;
BA_ "GenMsgCycleTime" BO_ 576 50;
BA_ "GenSigInactiveValue" SG_ 576 RollingCounter_IFC_HCM7 15;
BA_ "IsRcSignal" SG_ 576 RollingCounter_IFC_HCM7 1;
BA_ "IsCrcSignal" SG_ 576 Checksum_IFC_HCM7 1;
BA_ "GenSigInactiveValue" SG_ 576 RollingCounter_IFC_HCM6 15;
BA_ "IsRcSignal" SG_ 576 RollingCounter_IFC_HCM6 1;
BA_ "IsCrcSignal" SG_ 576 Checksum_IFC_HCM6 1;
BA_ "GenSigInactiveValue" SG_ 576 RollingCounter_IFC_HCM5 15;
BA_ "IsRcSignal" SG_ 576 RollingCounter_IFC_HCM5 1;
BA_ "IsCrcSignal" SG_ 576 Checksum_IFC_HCM5 1;
BA_ "GenSigInactiveValue" SG_ 576 RollingCounter_IFC_HCM4 15;
BA_ "IsRcSignal" SG_ 576 RollingCounter_IFC_HCM4 1;
BA_ "IsCrcSignal" SG_ 576 Checksum_IFC_HCM4 1;
BA_ "GenSigInactiveValue" SG_ 576 RollingCounter_IFC_HCM3 15;
BA_ "IsRcSignal" SG_ 576 RollingCounter_IFC_HCM3 1;
BA_ "IsCrcSignal" SG_ 576 Checksum_IFC_HCM3 1;
BA_ "GenSigInactiveValue" SG_ 576 RollingCounter_IFC_HCM2 15;
BA_ "IsRcSignal" SG_ 576 RollingCounter_IFC_HCM2 1;
BA_ "IsCrcSignal" SG_ 576 Checksum_IFC_HCM2 1;
BA_ "GenSigInactiveValue" SG_ 576 RollingCounter_IFC_HCM1 15;
BA_ "IsRcSignal" SG_ 576 RollingCounter_IFC_HCM1 1;
BA_ "IsCrcSignal" SG_ 576 Checksum_IFC_HCM1 1;
BA_ "VFrameFormat" BO_ 667 14;
BA_ "MsgType" BO_ 667 0;
BA_ "GenMsgCycleTime" BO_ 667 100;
BA_ "GenSigStartValue" SG_ 667 HAVP_LrngDst 1023;
BA_ "VFrameFormat" BO_ 674 14;
BA_ "MsgType" BO_ 674 0;
BA_ "GenMsgCycleTime" BO_ 674 55;
BA_ "GenSigInactiveValue" SG_ 674 RP_Shock_Dist_R 1023;
BA_ "GenSigStartValue" SG_ 674 RP_Shock_Height_R 150;
BA_ "GenSigInactiveValue" SG_ 674 RP_Shock_Height_R 511;
BA_ "GenSigInactiveValue" SG_ 674 RP_Shock_Dist_L 1023;
BA_ "GenSigInactiveValue" SG_ 674 RP_Shock_Confidence_L 127;
BA_ "GenSigStartValue" SG_ 674 RP_Shock_Height_L 150;
BA_ "GenSigInactiveValue" SG_ 674 RP_Shock_Height_L 511;
BA_ "GenSigInactiveValue" SG_ 674 RP_Shock_Confidence_R 127;
BA_ "GenSigStartValue" SG_ 674 RP_Used_Speed 2200;
BA_ "GenSigInactiveValue" SG_ 674 RP_Used_Speed 4095;
BA_ "VFrameFormat" BO_ 786 14;
BA_ "MsgType" BO_ 786 0;
BA_ "GenMsgCycleTime" BO_ 786 200;
BA_ "GenSigStartValue" SG_ 786 MDC_AverTemp 255;
BA_ "GenSigInactiveValue" SG_ 786 MDC_AverTemp 255;
BA_ "GenSigStartValue" SG_ 786 MDC_MaxTemp 255;
BA_ "GenSigInactiveValue" SG_ 786 MDC_MaxTemp 255;
BA_ "GenSigStartValue" SG_ 786 MDC_FlowReq 2;
BA_ "GenMsgSendType" BO_ 1125 8;
BA_ "VFrameFormat" BO_ 1125 14;
BA_ "MsgType" BO_ 1125 0;
BA_ "GenSigSendType" SG_ 1125 IDC_Sync_Req 1;
BA_ "VFrameFormat" BO_ 573 14;
BA_ "MsgType" BO_ 573 0;
BA_ "GenMsgCycleTime" BO_ 573 50;
BA_ "GenSigStartValue" SG_ 573 IFC_Line_special02_Curv 15625;
BA_ "GenSigStartValue" SG_ 573 TargetPathC1 201;
BA_ "GenSigStartValue" SG_ 573 IFC_Line_special01_CurvChange 480000;
BA_ "GenSigStartValue" SG_ 573 IFC_Line_special01_Curv 15625;
BA_ "GenSigStartValue" SG_ 573 HandsoffTimSts 1;
BA_ "GenSigStartValue" SG_ 573 IFC_Line_special01_Dy 2825;
BA_ "GenSigStartValue" SG_ 573 IFC_NextRiLane_dy 2496;
BA_ "GenSigInactiveValue" SG_ 573 IFC_NextRiLane_dy 4095;
BA_ "GenSigStartValue" SG_ 573 IFC_NextLeLane_dy 2496;
BA_ "GenSigInactiveValue" SG_ 573 IFC_NextLeLane_dy 4095;
BA_ "GenSigStartValue" SG_ 573 IFC_RiLane_dy 2496;
BA_ "GenSigInactiveValue" SG_ 573 IFC_RiLane_dy 4095;
BA_ "GenSigStartValue" SG_ 573 IFC_LeLane_dy 2496;
BA_ "GenSigInactiveValue" SG_ 573 IFC_LeLane_dy 4095;
BA_ "GenSigStartValue" SG_ 573 IFC_LaneCurve 2047;
BA_ "GenSigStartValue" SG_ 573 IFC_Line_special02_HeadingAngle 201;
BA_ "GenSigInactiveValue" SG_ 573 IFCCalibrationSts 2;
BA_ "GenSigInactiveValue" SG_ 573 LSSErrSts 1;
BA_ "GenSigInactiveValue" SG_ 573 ELKMainState 6;
BA_ "GenSigInactiveValue" SG_ 573 LCP_Warn 3;
BA_ "GenSigStartValue" SG_ 573 IFC_Line_special01_HeadingAngle 201;
BA_ "GenSigInactiveValue" SG_ 573 ESSErrSts 1;
BA_ "GenSigInactiveValue" SG_ 573 AESErrSts 1;
BA_ "GenSigInactiveValue" SG_ 573 HWA_Text_Lib 61;
BA_ "VFrameFormat" BO_ 411 14;
BA_ "MsgType" BO_ 411 0;
BA_ "GenMsgCycleTime" BO_ 411 50;
BA_ "GenSigInactiveValue" SG_ 411 RHeadLmpFailSts 1;
BA_ "GenSigInactiveValue" SG_ 411 LHeadLmpFailSts 1;
BA_ "VFrameFormat" BO_ 412 14;
BA_ "MsgType" BO_ 412 0;
BA_ "GenMsgCycleTime" BO_ 412 50;
BA_ "GenSigInactiveValue" SG_ 412 RFogLmpFailSts_R_PBox 1;
BA_ "GenSigInactiveValue" SG_ 412 RBrkLmpFailSts 1;
BA_ "GenSigInactiveValue" SG_ 412 LBrkLmpFailSts 1;
BA_ "GenSigInactiveValue" SG_ 412 HiPosnBrkLmpFailSts 1;
BA_ "VFrameFormat" BO_ 1121 14;
BA_ "MsgType" BO_ 1121 0;
BA_ "GenMsgCycleTime" BO_ 1121 30000;
BA_ "VFrameFormat" BO_ 833 14;
BA_ "MsgType" BO_ 833 0;
BA_ "GenMsgCycleTime" BO_ 833 500;
BA_ "GenSigInactiveValue" SG_ 833 TirePressSysFailrIndcn 1;
BA_ "VFrameFormat" BO_ 837 14;
BA_ "MsgType" BO_ 837 0;
BA_ "GenMsgCycleTime" BO_ 837 50;
BA_ "GenSigInactiveValue" SG_ 837 HiLowBeamSts 2;
BA_ "GenMsgSendType" BO_ 473 1;
BA_ "VFrameFormat" BO_ 473 14;
BA_ "MsgType" BO_ 473 0;
BA_ "GenSigSendType" SG_ 473 OTApowertrainmode 9;
BA_ "VFrameFormat" BO_ 568 14;
BA_ "MsgType" BO_ 568 0;
BA_ "GenMsgCycleTime" BO_ 568 50;
BA_ "GenSigStartValue" SG_ 568 SrPosn_VR_APP 127;
BA_ "VFrameFormat" BO_ 569 14;
BA_ "MsgType" BO_ 569 0;
BA_ "GenMsgCycleTime" BO_ 569 50;
BA_ "VFrameFormat" BO_ 661 14;
BA_ "MsgType" BO_ 661 0;
BA_ "GenMsgCycleTime" BO_ 661 50;
BA_ "VFrameFormat" BO_ 671 14;
BA_ "MsgType" BO_ 671 0;
BA_ "GenMsgCycleTime" BO_ 671 100;
BA_ "GenSigInactiveValue" SG_ 671 RollingCounter_BCM8 15;
BA_ "IsRcSignal" SG_ 671 RollingCounter_BCM8 1;
BA_ "GenSigInactiveValue" SG_ 671 WiprReq_F_PBox 7;
BA_ "IsCrcSignal" SG_ 671 Checksum_BCM8 1;
BA_ "VFrameFormat" BO_ 699 14;
BA_ "MsgType" BO_ 699 0;
BA_ "GenMsgCycleTime" BO_ 699 100;
BA_ "VFrameFormat" BO_ 783 14;
BA_ "MsgType" BO_ 783 0;
BA_ "GenMsgCycleTime" BO_ 783 100;
BA_ "VFrameFormat" BO_ 793 14;
BA_ "MsgType" BO_ 793 0;
BA_ "GenMsgCycleTime" BO_ 793 50;
BA_ "GenSigInactiveValue" SG_ 793 RollingCounter_BCM1 15;
BA_ "IsRcSignal" SG_ 793 RollingCounter_BCM1 1;
BA_ "IsCrcSignal" SG_ 793 Checksum_BCM1 1;
BA_ "VFrameFormat" BO_ 917 14;
BA_ "MsgType" BO_ 917 0;
BA_ "GenMsgCycleTime" BO_ 917 500;
BA_ "GenSigInactiveValue" SG_ 917 RRTireTemp 255;
BA_ "GenSigInactiveValue" SG_ 917 RRTirePress 255;
BA_ "GenSigInactiveValue" SG_ 917 RLTireTemp 255;
BA_ "GenSigInactiveValue" SG_ 917 RLTirePress 255;
BA_ "GenSigInactiveValue" SG_ 917 FRTireTemp 255;
BA_ "GenSigInactiveValue" SG_ 917 FRTirePress 255;
BA_ "GenSigInactiveValue" SG_ 917 FLTireTemp 255;
BA_ "GenSigInactiveValue" SG_ 917 FLTirePress 255;
BA_ "GenMsgSendType" BO_ 165 1;
BA_ "VFrameFormat" BO_ 165 14;
BA_ "MsgType" BO_ 165 0;
BA_ "GenSigSendType" SG_ 165 DoorHndlBtnActn 9;
BA_ "GenSigSendType" SG_ 165 PhyKeyPressActn 9;
BA_ "GenSigSendType" SG_ 165 PhyKeyPosnSts 9;
BA_ "VFrameFormat" BO_ 259 14;
BA_ "MsgType" BO_ 259 0;
BA_ "GenMsgCycleTime" BO_ 259 20;
BA_ "GenSigInactiveValue" SG_ 259 RollingCounter_ECM2 15;
BA_ "IsRcSignal" SG_ 259 RollingCounter_ECM2 1;
BA_ "GenSigStartValue" SG_ 259 AccelPedalPosnVldty 2;
BA_ "IsCrcSignal" SG_ 259 Checksum_ECM2 1;
BA_ "GenSigInactiveValue" SG_ 259 RollingCounter_ECM9 15;
BA_ "IsRcSignal" SG_ 259 RollingCounter_ECM9 1;
BA_ "IsCrcSignal" SG_ 259 Checksum_ECM9 1;
BA_ "VFrameFormat" BO_ 273 14;
BA_ "MsgType" BO_ 273 0;
BA_ "GenMsgCycleTime" BO_ 273 10;
BA_ "GenSigStartValue" SG_ 273 EngSpdVldty 2;
BA_ "VFrameFormat" BO_ 283 14;
BA_ "MsgType" BO_ 283 0;
BA_ "GenMsgCycleTime" BO_ 283 20;
BA_ "GenSigInactiveValue" SG_ 283 VMCFucActvSts 9;
BA_ "GenSigStartValue" SG_ 283 VCU_DrvReqTqWhl_FA 16383;
BA_ "GenSigInactiveValue" SG_ 283 VCU_DrvReqTqWhl_FA 32767;
BA_ "GenSigStartValue" SG_ 283 VCU_DrvReqTqWhl_RA 16383;
BA_ "GenSigInactiveValue" SG_ 283 VCU_DrvReqTqWhl_RA 32767;
BA_ "GenSigInactiveValue" SG_ 283 HCU_VirtLoad_FA 31;
BA_ "GenSigStartValue" SG_ 283 IdleSpdSetPointReq 2046;
BA_ "GenSigInactiveValue" SG_ 283 IdleSpdSetPointReq 2047;
BA_ "GenSigStartValue" SG_ 283 VCU_MaxSpdLimit 3000;
BA_ "GenSigInactiveValue" SG_ 283 VCU_MaxSpdLimit 3001;
BA_ "GenSigInactiveValue" SG_ 283 RollingCounter_VCU26 15;
BA_ "IsRcSignal" SG_ 283 RollingCounter_VCU26 1;
BA_ "GenSigInactiveValue" SG_ 283 DrvTrqReqOvld 3;
BA_ "GenSigStartValue" SG_ 283 ActTotWheelTrq 4094;
BA_ "GenSigInactiveValue" SG_ 283 ActTotWheelTrq 8191;
BA_ "GenSigStartValue" SG_ 283 VCU_DrvReqTqWhl 1200;
BA_ "GenSigInactiveValue" SG_ 283 VCU_DrvReqTqWhl 4095;
BA_ "GenSigInactiveValue" SG_ 283 MaxPsblPosWheelTrq 4095;
BA_ "GenSigStartValue" SG_ 283 MinPsblNegWheelTrq 4094;
BA_ "GenSigInactiveValue" SG_ 283 MinPsblNegWheelTrq 4095;
BA_ "IsCrcSignal" SG_ 283 Checksum_VCU26 1;
BA_ "GenSigInactiveValue" SG_ 283 RollingCounter_VCU21 15;
BA_ "IsRcSignal" SG_ 283 RollingCounter_VCU21 1;
BA_ "IsCrcSignal" SG_ 283 Checksum_VCU21 1;
BA_ "GenSigInactiveValue" SG_ 283 RollingCounter_VCU12 15;
BA_ "IsRcSignal" SG_ 283 RollingCounter_VCU12 1;
BA_ "IsCrcSignal" SG_ 283 Checksum_VCU12 1;
BA_ "VFrameFormat" BO_ 295 14;
BA_ "MsgType" BO_ 295 0;
BA_ "GenMsgCycleTime" BO_ 295 20;
BA_ "VFrameFormat" BO_ 302 14;
BA_ "MsgType" BO_ 302 0;
BA_ "GenMsgCycleTime" BO_ 302 20;
BA_ "GenSigInactiveValue" SG_ 302 RollingCounter_IBC_FD1_5 15;
BA_ "IsRcSignal" SG_ 302 RollingCounter_IBC_FD1_5 1;
BA_ "GenSigInactiveValue" SG_ 302 APCFailrSts 7;
BA_ "GenSigStartValue" SG_ 302 AVPavailability 1;
BA_ "IsCrcSignal" SG_ 302 Checksum_IBC_FD1_5 1;
BA_ "GenSigInactiveValue" SG_ 302 RollingCounter_IBC_FD1_2 15;
BA_ "IsRcSignal" SG_ 302 RollingCounter_IBC_FD1_2 1;
BA_ "IsCrcSignal" SG_ 302 Checksum_IBC_FD1_2 1;
BA_ "GenSigInactiveValue" SG_ 302 RollingCounter_IBC_FD1_1 15;
BA_ "IsRcSignal" SG_ 302 RollingCounter_IBC_FD1_1 1;
BA_ "GenSigInactiveValue" SG_ 302 CST_Status 3;
BA_ "GenSigInactiveValue" SG_ 302 PushrodStauts 3;
BA_ "GenSigInactiveValue" SG_ 302 BrkFldWarn 2;
BA_ "GenSigInactiveValue" SG_ 302 InpRodStkSts 1;
BA_ "GenSigInactiveValue" SG_ 302 PlungerPressSts 1;
BA_ "GenSigInactiveValue" SG_ 302 SimtorPressSts 1;
BA_ "IsCrcSignal" SG_ 302 Checksum_IBC_FD1_1 1;
BA_ "VFrameFormat" BO_ 311 14;
BA_ "MsgType" BO_ 311 0;
BA_ "GenMsgCycleTime" BO_ 311 20;
BA_ "GenSigStartValue" SG_ 311 RWSAngMinLimn 1023;
BA_ "GenSigStartValue" SG_ 311 RWSAngMaxLimn 1023;
BA_ "GenSigInactiveValue" SG_ 311 RollingCounter_ABS3 15;
BA_ "IsRcSignal" SG_ 311 RollingCounter_ABS3 1;
BA_ "GenSigStartValue" SG_ 311 VehOdoInfoSts 1;
BA_ "GenSigInactiveValue" SG_ 311 EBDFailSts 1;
BA_ "GenSigStartValue" SG_ 311 ABSFailSts 1;
BA_ "GenSigInactiveValue" SG_ 311 ABSFailSts 1;
BA_ "IsCrcSignal" SG_ 311 Checksum_ABS3 1;
BA_ "GenSigInactiveValue" SG_ 311 RollingCounter_ESP4 15;
BA_ "IsRcSignal" SG_ 311 RollingCounter_ESP4 1;
BA_ "GenSigStartValue" SG_ 311 DrvTrqRedSlowReq_FA 65535;
BA_ "GenSigStartValue" SG_ 311 DrvTrqRedFastReq_FA 65535;
BA_ "IsCrcSignal" SG_ 311 Checksum_ESP4 1;
BA_ "GenSigInactiveValue" SG_ 311 RollingCounter_ESP7 15;
BA_ "IsRcSignal" SG_ 311 RollingCounter_ESP7 1;
BA_ "GenSigInactiveValue" SG_ 311 LgtCtrlrFailr 6;
BA_ "GenSigInactiveValue" SG_ 311 LgtCtrlrSts 7;
BA_ "IsCrcSignal" SG_ 311 Checksum_ESP7 1;
BA_ "GenSigInactiveValue" SG_ 311 RollingCounter_ESP1 15;
BA_ "IsRcSignal" SG_ 311 RollingCounter_ESP1 1;
BA_ "GenSigInactiveValue" SG_ 311 TrqMaxLim 4095;
BA_ "GenSigInactiveValue" SG_ 311 ClutOpenReq 3;
BA_ "GenSigStartValue" SG_ 311 ESP_MasterCylBrkPressVld 1;
BA_ "GenSigInactiveValue" SG_ 311 ESPFailSts 1;
BA_ "IsCrcSignal" SG_ 311 Checksum_ESP1 1;
BA_ "GenSigInactiveValue" SG_ 311 RollingCounter_ESP2 15;
BA_ "IsRcSignal" SG_ 311 RollingCounter_ESP2 1;
BA_ "GenSigStartValue" SG_ 311 SysOperatingMod_ESP 1;
BA_ "GenSigInactiveValue" SG_ 311 TAB_Sts 3;
BA_ "GenSigInactiveValue" SG_ 311 DrivingModDis 14;
BA_ "GenSigStartValue" SG_ 311 DrivingModReq_ESP 1;
BA_ "GenSigInactiveValue" SG_ 311 DrivingModReq_ESP 15;
BA_ "GenSigInactiveValue" SG_ 311 AVHErrSts 1;
BA_ "GenSigInactiveValue" SG_ 311 VehStandstill 2;
BA_ "GenSigStartValue" SG_ 311 SwtOffCrsCtrl 1;
BA_ "IsCrcSignal" SG_ 311 Checksum_ESP2 1;
BA_ "VFrameFormat" BO_ 315 14;
BA_ "MsgType" BO_ 315 0;
BA_ "GenMsgCycleTime" BO_ 315 20;
BA_ "GenSigInactiveValue" SG_ 315 RollingCounter_ABS2 15;
BA_ "IsRcSignal" SG_ 315 RollingCounter_ABS2 1;
BA_ "GenSigStartValue" SG_ 315 WssRREdgesSumVld 1;
BA_ "GenSigStartValue" SG_ 315 WssRLEdgesSumVld 1;
BA_ "IsCrcSignal" SG_ 315 Checksum_ABS2 1;
BA_ "GenSigInactiveValue" SG_ 315 RollingCounter_ESP9 15;
BA_ "IsRcSignal" SG_ 315 RollingCounter_ESP9 1;
BA_ "GenSigStartValue" SG_ 315 IBC_RwsAngReq 4095;
BA_ "IsCrcSignal" SG_ 315 Checksum_ESP9 1;
BA_ "GenSigInactiveValue" SG_ 315 RollingCounter_ESP13 15;
BA_ "IsRcSignal" SG_ 315 RollingCounter_ESP13 1;
BA_ "GenSigStartValue" SG_ 315 MSRVld 1;
BA_ "GenSigStartValue" SG_ 315 DrvTrqRedReq_RA 65535;
BA_ "IsCrcSignal" SG_ 315 Checksum_ESP13 1;
BA_ "GenSigInactiveValue" SG_ 315 RollingCounter_ESP8 15;
BA_ "IsRcSignal" SG_ 315 RollingCounter_ESP8 1;
BA_ "GenSigStartValue" SG_ 315 CCO_TrqReq 65535;
BA_ "GenSigInactiveValue" SG_ 315 CCO_Active 3;
BA_ "GenSigInactiveValue" SG_ 315 SSASts 3;
BA_ "IsCrcSignal" SG_ 315 Checksum_ESP8 1;
BA_ "GenSigInactiveValue" SG_ 315 RollingCounter_EPB1 15;
BA_ "IsRcSignal" SG_ 315 RollingCounter_EPB1 1;
BA_ "GenSigInactiveValue" SG_ 315 ESP_DSTTrqReq 1023;
BA_ "GenSigInactiveValue" SG_ 315 EPBErrSts 2;
BA_ "IsCrcSignal" SG_ 315 Checksum_EPB1 1;
BA_ "GenSigInactiveValue" SG_ 315 RollingCounter_ABS1 15;
BA_ "IsRcSignal" SG_ 315 RollingCounter_ABS1 1;
BA_ "GenSigStartValue" SG_ 315 WssFREdgesSumVld 1;
BA_ "GenSigStartValue" SG_ 315 WssFLEdgesSumVld 1;
BA_ "IsCrcSignal" SG_ 315 Checksum_ABS1 1;
BA_ "VFrameFormat" BO_ 327 14;
BA_ "MsgType" BO_ 327 0;
BA_ "GenMsgCycleTime" BO_ 327 20;
BA_ "GenSigInactiveValue" SG_ 327 RollingCounter_EPS3 15;
BA_ "IsRcSignal" SG_ 327 RollingCounter_EPS3 1;
BA_ "GenSigInactiveValue" SG_ 327 EPS_HADHndShkRespSt 5;
BA_ "GenSigInactiveValue" SG_ 327 EPS_SteerWheelSpd 32767;
BA_ "GenSigInactiveValue" SG_ 327 EPS_SteerWheelAng 32767;
BA_ "IsCrcSignal" SG_ 327 Checksum_EPS3 1;
BA_ "GenSigInactiveValue" SG_ 327 RollingCounter_EPS2 15;
BA_ "IsRcSignal" SG_ 327 RollingCounter_EPS2 1;
BA_ "GenSigInactiveValue" SG_ 327 EPS_LKATrqOvlDlvdSts 3;
BA_ "GenSigInactiveValue" SG_ 327 EPS_LKAAngDlvdSts 3;
BA_ "GenSigStartValue" SG_ 327 EPS_DrvInpTrqVal_HighReslolution 2047;
BA_ "IsCrcSignal" SG_ 327 Checksum_EPS2 1;
BA_ "GenSigInactiveValue" SG_ 327 RollingCounter_EPS1 15;
BA_ "IsRcSignal" SG_ 327 RollingCounter_EPS1 1;
BA_ "GenSigInactiveValue" SG_ 327 SteerSysFltTyp 5;
BA_ "GenSigInactiveValue" SG_ 327 EPS_AvailSts 3;
BA_ "GenSigStartValue" SG_ 327 EPS_DSTCtrlSts 1;
BA_ "GenSigInactiveValue" SG_ 327 EPS_FailSts 1;
BA_ "GenSigStartValue" SG_ 327 EPS_TrqSnsrSts 1;
BA_ "IsCrcSignal" SG_ 327 Checksum_EPS1 1;
BA_ "VFrameFormat" BO_ 338 14;
BA_ "MsgType" BO_ 338 0;
BA_ "GenMsgCycleTime" BO_ 338 20;
BA_ "GenSigInactiveValue" SG_ 338 RearELDLckSts 3;
BA_ "VFrameFormat" BO_ 357 14;
BA_ "MsgType" BO_ 357 0;
BA_ "GenMsgCycleTime" BO_ 357 20;
BA_ "GenSigInactiveValue" SG_ 357 TurnLmpSwtErrSts 1;
BA_ "GenSigInactiveValue" SG_ 357 FrntWiprSwtSts 7;
BA_ "VFrameFormat" BO_ 388 14;
BA_ "MsgType" BO_ 388 0;
BA_ "GenMsgCycleTime" BO_ 388 20;
BA_ "GenSigInactiveValue" SG_ 388 RollingCounter_VCU_FD28_2 15;
BA_ "IsRcSignal" SG_ 388 RollingCounter_VCU_FD28_2 1;
BA_ "IsCrcSignal" SG_ 388 Checksum_VCU_FD28_2 1;
BA_ "GenSigInactiveValue" SG_ 388 RollingCounter_VCU_FD28_1 15;
BA_ "IsRcSignal" SG_ 388 RollingCounter_VCU_FD28_1 1;
BA_ "IsCrcSignal" SG_ 388 Checksum_VCU_FD28_1 1;
BA_ "GenMsgSendType" BO_ 474 1;
BA_ "VFrameFormat" BO_ 474 14;
BA_ "MsgType" BO_ 474 0;
BA_ "GenSigSendType" SG_ 474 OneclickClsIntellgntDrvgReq 9;
BA_ "GenSigSendType" SG_ 474 OutdPrkgReq 9;
BA_ "GenSigSendType" SG_ 474 CamFolwSwtReq 9;
BA_ "GenSigSendType" SG_ 474 PrkModReq 9;
BA_ "GenSigSendType" SG_ 474 TJA_ASCruise 9;
BA_ "GenSigSendType" SG_ 474 RCTA_DispSwtReq 9;
BA_ "GenSigSendType" SG_ 474 AutoPrkOutSwtReq 9;
BA_ "GenSigSendType" SG_ 474 PrkgSlotId 9;
BA_ "GenSigSendType" SG_ 474 HAVP_UseMod 9;
BA_ "GenSigSendType" SG_ 474 HUT_HAVP_APA_Permit 9;
BA_ "GenSigSendType" SG_ 474 UserDefinedParkCmd 9;
BA_ "GenSigSendType" SG_ 474 SlotNum_VR 9;
BA_ "GenSigSendType" SG_ 474 UserDefPrkMenuSelCmd 9;
BA_ "GenSigSendType" SG_ 474 HUT_HAVP_Set_Path_Ending 9;
BA_ "GenSigSendType" SG_ 474 HUT_HAVP_Comfirm_Btn 9;
BA_ "GenSigSendType" SG_ 474 HUT_HAVP_SelfParLot_Ending 9;
BA_ "GenSigSendType" SG_ 474 HUT_HAVP_Set_Starting 9;
BA_ "GenSigSendType" SG_ 474 BackReq_RPA 9;
BA_ "GenSigSendType" SG_ 474 SteerWheelsilentReq 9;
BA_ "GenMsgSendType" BO_ 489 1;
BA_ "VFrameFormat" BO_ 489 14;
BA_ "MsgType" BO_ 489 0;
BA_ "GenSigSendType" SG_ 489 BackReq_AVM 9;
BA_ "GenMsgSendType" BO_ 490 1;
BA_ "VFrameFormat" BO_ 490 14;
BA_ "MsgType" BO_ 490 0;
BA_ "GenSigSendType" SG_ 490 RmtPrkRadShieldSet 9;
BA_ "GenMsgSendType" BO_ 493 1;
BA_ "VFrameFormat" BO_ 493 14;
BA_ "MsgType" BO_ 493 0;
BA_ "GenSigSendType" SG_ 493 TraOvlSwtCmd 9;
BA_ "GenSigSendType" SG_ 493 StartPrkgPath2Cmd 9;
BA_ "GenSigSendType" SG_ 493 DeletePath2Cmd 9;
BA_ "GenSigSendType" SG_ 493 StartPrkgPath1Cmd 9;
BA_ "GenSigSendType" SG_ 493 DeletePath1Cmd 9;
BA_ "GenSigSendType" SG_ 493 SelPrkgFctnCmd 9;
BA_ "GenSigSendType" SG_ 493 P2P_PrkgDirectSwtCmd 9;
BA_ "GenSigSendType" SG_ 493 PathLrngFinshCmd 9;
BA_ "GenSigSendType" SG_ 493 PathLrngStartCmd 9;
BA_ "GenSigSendType" SG_ 493 ParkMdlCmd 9;
BA_ "GenSigSendType" SG_ 493 BackReq_APS 9;
BA_ "GenSigSendType" SG_ 493 SelPrkOutDirReq 9;
BA_ "GenSigSendType" SG_ 493 PrkInDirChoice 9;
BA_ "GenMsgSendType" BO_ 494 1;
BA_ "VFrameFormat" BO_ 494 14;
BA_ "MsgType" BO_ 494 0;
BA_ "GenSigSendType" SG_ 494 APSSwtReq_VR 9;
BA_ "GenSigSendType" SG_ 494 APSPrkgTypSeln 9;
BA_ "GenSigSendType" SG_ 494 SDWSwtSet 9;
BA_ "VFrameFormat" BO_ 545 14;
BA_ "MsgType" BO_ 545 0;
BA_ "GenMsgCycleTime" BO_ 545 20;
BA_ "GenSigInactiveValue" SG_ 545 RollingCounter_DCT5 15;
BA_ "IsRcSignal" SG_ 545 RollingCounter_DCT5 1;
BA_ "GenSigStartValue" SG_ 545 ShiftLeverPosn_SBWM 7;
BA_ "GenSigInactiveValue" SG_ 545 ShiftLeverPosn_SBWM 7;
BA_ "GenSigStartValue" SG_ 545 TGS_LEVER 14;
BA_ "GenSigInactiveValue" SG_ 545 TGS_LEVER 15;
BA_ "GenSigInactiveValue" SG_ 545 TCU_OSS 16383;
BA_ "GenSigInactiveValue" SG_ 545 TCUDrivingMode 10;
BA_ "IsCrcSignal" SG_ 545 Checksum_DCT5 1;
BA_ "VFrameFormat" BO_ 555 14;
BA_ "MsgType" BO_ 555 0;
BA_ "GenMsgCycleTime" BO_ 555 50;
BA_ "GenSigInactiveValue" SG_ 555 RollingCounter_HOD_1 15;
BA_ "IsRcSignal" SG_ 555 RollingCounter_HOD_1 1;
BA_ "GenSigStartValue" SG_ 555 HOD_HandOffSts 15;
BA_ "GenSigInactiveValue" SG_ 555 HOD_HandOffSts 4;
BA_ "GenSigStartValue" SG_ 555 HOD_CalcThreshold 255;
BA_ "GenSigInactiveValue" SG_ 555 HOD_CalcThreshold 255;
BA_ "GenSigStartValue" SG_ 555 HOD_ErrInfo 15;
BA_ "IsCrcSignal" SG_ 555 Checksum_HOD_1 1;
BA_ "VFrameFormat" BO_ 565 14;
BA_ "MsgType" BO_ 565 0;
BA_ "GenMsgCycleTime" BO_ 565 50;
BA_ "GenSigInactiveValue" SG_ 565 DrvFaiMsg 4;
BA_ "VFrameFormat" BO_ 570 14;
BA_ "MsgType" BO_ 570 0;
BA_ "GenMsgCycleTime" BO_ 570 50;
BA_ "GenSigInactiveValue" SG_ 570 CustomSwtSts_Park 2;
VAL_ 719 AttentionDivsAlarmTimGrad 0 "Initial_Value" 1 "Warning_Level_1" 2 "Warning_Level_2" 3 "Warning_Level_3" ;
VAL_ 719 TraLightCtrlSts 0 "No_display" 1 "OFF" 2 "Passive" 3 "Standby" 4 "Active" 5 "Fault" 6 "Reserved" ;
VAL_ 719 RR_SideCamaErrSts 0 "No_error" 1 "Error" 2 "Blindness" 3 "Reserved" ;
VAL_ 719 LR_SideCamaErrSts 0 "No_error" 1 "Error" 2 "Blindness" 3 "Reserved" ;
VAL_ 719 ILC_InterSysInfoDisp 0 "No_display" 1 "Low_speed_don't_support_lane_change" 2 "Resvered" ;
VAL_ 719 TraLightSwtResp 0 "OFF" 1 "ON" ;
VAL_ 719 TraLightRmdInfoDisp 0 "No_display" 1 "TLC_Activated" 2 "TLC_Deactivated" 3 "Stopping_by_yellow_light" 4 "Stopping_by_red_light" 5 "Launching_by_green_light" 6 "Stepping_into_waiting_area" 7 "Going_straight" 8 "Going_straight,pay_attention_pls" 9 "Left_turning" 10 "Left_turning,_pay_attention_pls" 11 "Right_turning" 12 "Right_turning_pay_attention_pls" 13 "Turning_around,_pay_attention_pls" 14 "Warning" 15 "Take_over_pls" 16 "Reserved" ;
VAL_ 719 TraLightWarnInfoDisp 0 "No_Traffic_light" 1 "Left_Turn" 2 "Straight" 3 "Right_Turn" 4 "Warning" 5 "Turn_round_Warning" 6 "Run_Ared_Light" 7 "Stop_About_To_Cross_The_Line" 8 "Slow_Down_The_Yellow_Light" 9 "Camera_is_covered" 10 "Traffic_Light_Observation_Limited" 11 "Roundabout" ;
VAL_ 719 TSR_TFL_EgoVeh 0 "No_warning" 1 "One" 2 "Two" 3 "Three" 4 "Four" 5 "Five" 6 "Six" 7 "Seven" 8 "Eight" 9 "Reserved" ;
VAL_ 719 TSR_TFL7_LightColor 0 "No_warning" 1 "Red_light" 2 "Green_light" 3 "Yellow_light" 4 "Red_light_flash" 5 "Green_light_flash" 6 "Yellow_light_flash" 7 "Reserved" ;
VAL_ 719 TSR_TFL7_LightType 0 "No_warning" 1 "S" 2 "LT" 3 "RT" 4 "TA" 5 "SLT" 6 "SRT" 7 "SLRT" 8 "STA" 9 "Red_light_allow_to_turn_left" 10 "Red_light_allow_to_turn_right" 11 "Reserved" ;
VAL_ 719 TSR_TFL6_LightColor 0 "No_warning" 1 "Red_light" 2 "Green_light" 3 "Yellow_light" 4 "Red_light_flash" 5 "Green_light_flash" 6 "Yellow_light_flash" 7 "Reserved" ;
VAL_ 719 TSR_TFL6_LightType 0 "No_warning" 1 "S" 2 "LT" 3 "RT" 4 "TA" 5 "SLT" 6 "SRT" 7 "SLRT" 8 "STA" 9 "Red_light_allow_to_turn_left" 10 "Red_light_allow_to_turn_right" 11 "Reserved" ;
VAL_ 719 TSR_TFL5_LightColor 0 "No_warning" 1 "Red_light" 2 "Green_light" 3 "Yellow_light" 4 "Red_light_flash" 5 "Green_light_flash" 6 "Yellow_light_flash" 7 "Reserved" ;
VAL_ 719 TSR_TFL5_LightType 0 "No_warning" 1 "S" 2 "LT" 3 "RT" 4 "TA" 5 "SLT" 6 "SRT" 7 "SLRT" 8 "STA" 9 "Red_light_allow_to_turn_left" 10 "Red_light_allow_to_turn_right" 11 "Reserved" ;
VAL_ 719 TSR_TFL4_LightColor 0 "No_warning" 1 "Red_light" 2 "Green_light" 3 "Yellow_light" 4 "Red_light_flash" 5 "Green_light_flash" 6 "Yellow_light_flash" 7 "Reserved" ;
VAL_ 719 TSR_TFL4_LightType 0 "No_warning" 1 "S" 2 "LT" 3 "RT" 4 "TA" 5 "SLT" 6 "SRT" 7 "SLRT" 8 "STA" 9 "Red_light_allow_to_turn_left" 10 "Red_light_allow_to_turn_right" 11 "Reserved" ;
VAL_ 719 TSR_TFL3_LightColor 0 "No_warning" 1 "Red_light" 2 "Green_light" 3 "Yellow_light" 4 "Red_light_flash" 5 "Green_light_flash" 6 "Yellow_light_flash" 7 "Reserved" ;
VAL_ 719 TSR_TFL3_LightType 0 "No_warning" 1 "S" 2 "LT" 3 "RT" 4 "TA" 5 "SLT" 6 "SRT" 7 "SLRT" 8 "STA" 9 "Red_light_allow_to_turn_left" 10 "Red_light_allow_to_turn_right" 11 "Reserved" ;
VAL_ 719 TSR_TFL2_LightColor 0 "No_warning" 1 "Red_light" 2 "Green_light" 3 "Yellow_light" 4 "Red_light_flash" 5 "Green_light_flash" 6 "Yellow_light_flash" 7 "Reserved" ;
VAL_ 719 TSR_TFL2_LightType 0 "No_warning" 1 "S" 2 "LT" 3 "RT" 4 "TA" 5 "SLT" 6 "SRT" 7 "SLRT" 8 "STA" 9 "Red_light_allow_to_turn_left" 10 "Red_light_allow_to_turn_right" 11 "Reserved" ;
VAL_ 719 TSR_TFL1_LightColor 0 "No_warning" 1 "Red_light" 2 "Green_light" 3 "Yellow_light" 4 "Red_light_flash" 5 "Green_light_flash" 6 "Yellow_light_flash" 7 "Reserved" ;
VAL_ 719 TSR_TFL7_LightTime 0 "Valid_values" ;
VAL_ 719 TSR_TFL6_LightTime 0 "Valid_values" ;
VAL_ 719 NavDecActive 0 "Inactive" 1 "NavDec_Active" 2 "NavDec_Take_Over_Warning" 3 "SPL_60__NavDec_Take_Over_Warning" 4 "SPL_70__NavDec_Take_Over_Warning" 5 "SPL_80__NavDec_Take_Over_Warning" 6 "SPL_90__NavDec_Take_Over_Warning" 7 "SPL_100_NavDec_Take_Over_Warning" 8 "SPL_110_NavDec_Take_Over_Warning" 9 "SPL_120_NavDec_Take_Over_Warning" 10 "Set_speed_over_NavDec" 11 "Reserved" ;
VAL_ 719 NavDecSwtResp 0 "OFF" 1 "ON" ;
VAL_ 719 LCMode_Swt_Resp 0 "Normal" 1 "Sport" 2 "Comfort" 3 "Reserve" ;
VAL_ 719 RainMode_Swt_Resp 0 "OFF" 1 "ON" ;
VAL_ 719 TSR_Traffic_Light_Ri 0 "No_Display" 1 "Greenlight" 2 "Redlight" 3 "Yellowlight" ;
VAL_ 719 Zebra_Mark_Dx 0 "Validvalue" 301 "Reserved" ;
VAL_ 719 TSR_Traffic_Light_Le 0 "No_Display" 1 "Greenlight" 2 "Redlight" 3 "Yellowlight" ;
VAL_ 719 TSR_Traffic_Light_Through 0 "No_Display" 1 "Greenlight" 2 "Redlight" 3 "Yellowlight" ;
VAL_ 719 TSR_Traffic_Light 0 "No_Display" 1 "Greenlight" 2 "Redlight" 3 "Yellowlight" ;
VAL_ 719 Grid_Mark_Dx 0 "Validvalue" 301 "Reserved" ;
VAL_ 719 LaneChngCfmSwt_Resp 0 "OFF" 1 "ON" ;
VAL_ 719 ALC_SwtReq_Resp 0 "OFF" 1 "ON" ;
VAL_ 719 AutoSpdSetSwt_Resp 0 "OFF" 1 "ON" ;
VAL_ 719 VoiceBrdcSwt_Resp 0 "OFF" 1 "ON" ;
VAL_ 719 UsrManSts_Resp 0 "OFF" 1 "Page_1" 2 "Page_2" 3 "Page_3" 4 "Page_4" 5 "Page_5" 6 "Page_6" 7 "Page_7" 8 "Page_8" 9 "Page_9" 160 "reserved" ;
VAL_ 719 HWA_InhibitWarn 0 "Default" 1 "Environment_inhibit" 2 "Attention" 3 "Handson" 4 "Seatbelt" 5 "Close_door" 6 "DMS_Off" 7 "Forward_gear" ;
VAL_ 719 Grid_Mark_Detn 0 "Not_dectected" 1 "Dectected" 2 "Reserved" 3 "Invalid" ;
VAL_ 719 Zebra_Mark_Detn 0 "Not_dectected" 1 "Dectected" 2 "Reserved" 3 "Invalid" ;
VAL_ 719 Stop_Mark_Detn 0 "Not_dectected" 1 "Dectected" 2 "Reserved" 3 "Invalid" ;
VAL_ 719 IFC_Line02_Source 0 "Detected_value" 1 "Fitted_value" ;
VAL_ 719 Stop_Mark_Dx 0 "Validvalue" 301 "Reserved" ;
VAL_ 719 TSR_Traffic_Light_Posn 0 "No_Display" 1 "Front" 2 "Left" 3 "Right" ;
VAL_ 719 NOH_WarnInfoDisp 0 "Default" 1 "Auto store to debug NOH" 2 "Restart to activate NOH" 3 "Off ramp fail" 4 "To mainroad fail" 5 "Turning fail" 6 "Toll gate fail" 7 "Roundabout fail" 8 "Reroute" 9 "Lane change manually" 10 "NOH resumed" 11 "Veh merge warn" 12 "Ramp off warn" 13 "GPS fail" 14 "Lane mark blurred" 15 "To drive out of main road" ;
VAL_ 719 MRC_TakOver_Req 0 "No_display" 1 "Slow_stop" 2 "Roadside_stop" 3 "Emergent_stop" ;
VAL_ 719 IFC_Line01_Source 0 "Detected_value" 1 "Fitted_value" ;
VAL_ 719 MRC_InterSysInfoDisp 0 "default" 1 "L_CR_fail" 2 "R_CR_fail" 3 "L_RSDS_fail" 4 "R_RSDS_fail" 5 "Radar_or_Cam_fail" 96 "Reserved" ;
VAL_ 719 HWA_TakOver_Trig 0 "Default" 1 "Off_ramp_fail" 2 "To_mainroad_fail" 3 "Turning_fail" 4 "Toll_gate_fail" 5 "Roundabout_fail" 6 "To slow stop" 7 "Reserved" ;
VAL_ 719 HWA_TakOver_Req 0 "Default" 1 "Steer_wheel_req" 2 "Takeover_req" 3 "Reserved" ;
VAL_ 719 HWA_WarnInfoDisp 0 "No display" 1 "Construction site ahead" 2 "Large vehicles warn" 3 "night warning" 4 "Adverse weather warning" 5 "Restart to activate HIPilot" 6 "Camera blocked" 7 "Auto store to debug HIPilot" 8 "Confirm left lane change" 9 "Confirm right lane change" 10 "Try ALC later" 11 "lane change is cancelled because of risk" 12 "lane change aborted" 13 "Please Keep Attention_distraction" 14 "Fasten copilot seatbelt" 15 "Curve driving, please hold the steering wheel" ;
VAL_ 719 HWA_ALC_Trig 0 "No_display" 1 "Slow_vehicle_ahead" 2 "Reserved" 3 "Reserved" ;
VAL_ 719 RollingCounter_IFC7 0 "Valid value" 15 "Invalid value" ;
VAL_ 719 HMA_Sts 0 "Off" 1 "Passive" 2 "Active" 3 "Temporary_fault" 4 "Permanently_fault" 5 "Suppression_Condition" 6 "LowTransform_Suppression" 7 "HighTransform_Suppression" ;
VAL_ 719 HMA_HibeamReq 0 "High beam request OFF" 1 "High beam request ON" 2 "High beam and laser beam request ON" 3 "Reserved" ;
VAL_ 719 IDC_L2_FWshrReq 0 "OFF" 1 "Wiper Wash" 2 "Wash in Auto Mode" 3 "Reserved" ;
VAL_ 719 TSRSpdLimWarnAu 0 "No_Warning" 1 "Warning" ;
VAL_ 719 IDC_L2_FWiperReq 0 "Wiper Off" 1 "Wiper Auto Or Intermittent" 2 "Low Speed" 3 "High Speed" 4 "reserved" 7 "Error" ;
VAL_ 719 TSRWarnResp 0 "OFF" 1 "ON" ;
VAL_ 719 IDC_L2_TurnLightReq 0 "Turn OFF" 1 "Turn Left ON" 2 "Turn Right ON" 3 "Turn OFF Light Sw" ;
VAL_ 719 IDC_L2_EmgyLightReq 0 "Turn OFF" 1 "Turn ON" ;
VAL_ 719 TSR_Snvty 0 "valid" 31 "Invalid" ;
VAL_ 719 TSRSpdLimWarn 0 "No Warning" 1 "Warning" ;
VAL_ 719 TSRTrfcSignVal 0 "None" 1 "Snow" 2 "Fog" 3 "ThunderStorm" 4 "Rain" 5 "FWay" 6 "EFWay" 7 "Straight" 8 "FrontageLeft" 9 "TurnLeftRight" 10 "FrontageRight" 11 "Right" 12 "TurnRight" 13 "Left" 14 "TurnLeft" 15 "RelieveNoOvertake" 16 "NoOvertake" 17 "StopGiveWay" 18 "GiveWay" 19 "NoPass" 20 "NoEntry" 21 "NoCar" 22 "NoTruck" 23 "NoBus" 24 "NoTurnaround" 25 "NoStraightLeftTurn" 26 "NoStraightRightTurn" 27 "NoLeftRightTurn" 28 "NoLeftTurn" 29 "NoRightTurn" 30 "NoStraight" 31 "WarnKids" 32 "WarnPed" 33 "WarnBike" 34 "WarnWorks" 35 "WarnWildanimal" 36 "WarnCattle" 37 "ACCidentProneSection" 38 "Town" 39 "Slow" 40 "SharpTurnR" 41 "SharpTurnL" 42 "ReverseCurveL" 43 "ReverseCurveR" 44 "ContinuousBend" 45 "Crossroads" 46 "ConfluenceR" 47 "ConfluenceL" 48 "Rain/Wetness" 49 "Snow/Icy" 50 "Time" 51 "Distance For" 52 "Distance In" 53 "Straight" 54 "FrontageLeft" 55 "TurnLeftRight" 56 "FrontageRight" 57 "Right" 58 "Turn Right" 59 "Left" 60 "Turn Left" 61 "Highway Start" 62 "Highway End" 63 "Mortorway Start" 64 "Mortorway End" 65 "City Entry" 66 "City Exit" 67 "Residential zones Entry" 68 "Residential zones Exit" 69 "Trailer" 70 "GiveWay to?Oncoming Vehicles" 71 "No Stopping" 72 "No Parking" 73 "Drive With Caution" 74 "Road Narrow" 75 "Beware of Crosswind" 76 "Slippery Surface" 77 "Bumpy Road Ahead" 78 "Low Water Crossing" 79 "Reserved" 255 "Invalid" ;
VAL_ 719 TSRTrfcSignValCfdc 0 "Null" 1 "Implicit" 2 "Explicit" 3 "Reserved" ;
VAL_ 719 TSRSpdLimSts 0 "No Speed Limit" 1 "Speed Limit" 2 "Speed Limit Cancel" 3 "Reserved" ;
VAL_ 719 TSRSpdLim 0 "No Display" 1 "SPL 5" 2 "SPL 10" 3 "SPL 15" 4 "SPL 20" 5 "SPL 25" 6 "SPL 30" 7 "SPL 35" 8 "SPL 40" 9 "SPL 45" 10 "SPL 50" 11 "SPL 55" 12 "SPL 60" 13 "SPL 65" 14 "SPL 70" 15 "SPL 75" 16 "SPL 80" 17 "SPL 85" 18 "SPL 90" 19 "SPL 95" 20 "SPL 100" 21 "SPL 105" 22 "SPL 110" 23 "SPL 115" 24 "SPL 120" 25 "SPL 125" 26 "SPL 130" 27 "SPL 135" 28 "SPL 140" 29 "SPL 145" 30 "SPL 150" 31 "Reserved" 63 "Invalid" ;
VAL_ 719 TSRSts 0 "Off" 1 "Fusion mode" 2 "Vision mode" 3 "Navigation only mode" 4 "Failed" 5 "ISA_Failed" 6 "ISA_Off" 7 "Reserved" ;
VAL_ 719 TSRSpdLimCfdc 0 "Null" 1 "Implicit" 2 "Explicit" 3 "Reserved" ;
VAL_ 719 TSRSpdLimUnit 0 "Unknown" 1 "KMH" 2 "MPH" 3 "Reserved" ;
VAL_ 719 TSRResp 0 "OFF" 1 "ON" ;
VAL_ 719 Checksum_IFC7 0 "Valid value" ;
VAL_ 719 TSR_TFL1_LightType 0 "No_warning" 1 "S" 2 "LT" 3 "RT" 4 "TA" 5 "SLT" 6 "SRT" 7 "SLRT" 8 "STA" 9 "Red_light_allow_to_turn_left" 10 "Red_light_allow_to_turn_right" 11 "Reserved" ;
VAL_ 719 TSR_TFL5_LightTime 0 "Valid_values" ;
VAL_ 719 TSR_TFL4_LightTime 0 "Valid_values" ;
VAL_ 719 TSR_TFL3_LightTime 0 "Valid_values" ;
VAL_ 719 TSR_TFL2_LightTime 0 "Valid_values" ;
VAL_ 719 TSR_TFL1_LightTime 0 "Valid_values" ;
VAL_ 719 TSRConSpdLimWarn 0 "No_Warning" 1 "Warning" ;
VAL_ 719 TSRConSpdLim 0 "No_Display" 1 "SPL_5" 2 "SPL_10" 3 "SPL_15" 4 "SPL_20" 5 "SPL_25" 6 "SPL_30" 7 "SPL_35" 8 "SPL_40" 9 "SPL_45" 10 "SPL_50" 11 "SPL_55" 12 "SPL_60" 13 "SPL_65" 14 "SPL_70" 15 "SPL_75" 16 "SPL_80" 17 "SPL_85" 18 "SPL_90" 19 "SPL_95" 20 "SPL_100" 21 "SPL_105" 22 "SPL_110" 23 "SPL_115" 24 "SPL_120" 25 "SPL_125" 26 "SPL_130" 27 "SPL_135" 28 "SPL_140" 29 "SPL_145" 30 "SPL_150" 31 "Reserved" 63 "Invalid" ;
VAL_ 395 RAEB_Warn 0 "Initial_Value" 1 "Vehicle_triggering" 2 "Pedestrian_triggering" ;
VAL_ 395 RAEB_State 0 "Initial_value" 1 "Off" 2 "Standby" 3 "Active" 4 "Passive" 5 "Fault" 6 "Hold" 7 "EBA_Active" ;
VAL_ 395 EBA_State 0 "Initial_value" 1 "OFF" 2 "Standby" 3 "Active" 4 "Passive" 5 "Fault" 6 "Reserved" ;
VAL_ 395 AEB_State 0 "Initial_value" 1 "OFF" 2 "Standby" 3 "Active" 4 "Passive" 5 "Fault" 6 "Hold" 7 "EBA_Active" ;
VAL_ 395 AWB_State 0 "Initial_value" 1 "OFF" 2 "Standby" 3 "Active" 4 "Passive" 5 "Fault" 6 "Reserved" ;
VAL_ 395 FCW_State 0 "Initial_value" 1 "OFF" 2 "Standby" 3 "Active" 4 "Passive" 5 "Fault" 6 "Reserved" ;
VAL_ 395 DW_State 0 "Initial_value" 1 "OFF" 2 "Standby" 3 "Active" 4 "Passive" 5 "Fault" 6 "Reserved" ;
VAL_ 395 RollingCounter_AEB6 0 "Valid value" 15 "Invalid value" ;
VAL_ 395 ExcpADASBrkgHldReq 0 "Initial_value" 1 "No_request" 2 "Request_brake" 3 "Request_hold" ;
VAL_ 395 DrvPrsnt 0 "Initial_value" 1 "With_driver" 2 "Without_driver" ;
VAL_ 395 BrkgHldReq 0 "No_request" 1 "AVH_off" 2 "AVH_active" 3 "AVH_standy" ;
VAL_ 395 BrkgSwtReq 0 "Initial_value" 1 "ON" 2 "OFF" ;
VAL_ 395 EPBModEna 0 "Initial_value" 1 "Disable" 2 "Enable" ;
VAL_ 395 EPBModReq 0 "No_request" 1 "Lock" 2 "Release" ;
VAL_ 395 EPBModReqVld 0 "Invalid" 1 "Valid" ;
VAL_ 395 BrkgTgtTyp 0 "Initial_value" 1 "Comfort" 2 "Emergency" ;
VAL_ 395 BrkgTgtTrqMod 0 "No_request" 1 "ACC" 2 "APA" ;
VAL_ 395 BrkgTgtTrqEna 0 "Initial_value" 1 "Disable" 2 "Enable" ;
VAL_ 395 BrkgTgtTrqVld 0 "Invalid" 1 "Valid" ;
VAL_ 395 BrkgTgtTrq 0 "Initial_value" ;
VAL_ 395 Checksum_AEB6 0 "Valid value" ;
VAL_ 395 RollingCounter_AEB1 0 "Valid value" 15 "Invalid value" ;
VAL_ 395 IntellgntAsscRoadTypConfid 0 "Initial_value" 1 "Valid_value" 15 "Invalid_Value" ;
VAL_ 395 IntellgntAsscRoadTyp 0 "Initial_value" 1 "Normal" 2 "Snow_covered_road" 3 "Ice_covered_road" 4 "Muddy_covered_road" 5 "Sand_covered_road" 6 "Dirt_covered_road" 7 "Asphalt_covered_road" 8 "Cement_covered_road" 9 "Pitted_covered_road" 15 "Invalid_Value" ;
VAL_ 395 AEB_ObjSty 0 "No Object" 1 "Vehicle" 2 "Pedestrian" 3 "Cyclist" 4 "Unknown" 5 "Speed_drop_increase" ;
VAL_ 395 AEB_BrkReqFunc 0 "No Request" 1 "AEB-V" 2 "AEB-VRU" 3 "AEB-JA" 4 "Reserved" 5 "AEB-FCTB" 6 "Reserved" ;
VAL_ 395 AEB_AWB_Level 0 "No level" 1 "Level 1" 2 "Level 2" 3 "Level 3" 4 "Level 4" 5 "Resvered" ;
VAL_ 395 AEB_TgtDecel_ReqValue 0 "Valid value" 65535 "Invalid" ;
VAL_ 395 AEB_ABP_Req 0 "No Request" 1 "Request" ;
VAL_ 395 AEB_AWB_Req 0 "No Request" 1 "Request" ;
VAL_ 395 AEB_TgtDecel_Req 0 "No Request" 1 "Request" ;
VAL_ 395 AEB_VehHldReq 0 "No Request" 1 "Request" ;
VAL_ 395 EBA_TgtDecel_Req 0 "No Request" 1 "Request" ;
VAL_ 395 AEB_ABA_Req 0 "No Request" 1 "Request" ;
VAL_ 395 AEB_ABA_Level 0 "Level 0" 1 "Level 1" 2 "Level 2" 3 "Level 3" ;
VAL_ 395 Checksum_AEB1 0 "Valid value" ;
VAL_ 395 AEB_Flag_VSI 0 "No_Request" 1 "Request" ;
VAL_ 395 ADAS_ErrSts 0 "System_Initializing" 1 "No_error" 2 "Blindness" 3 "Misalignment" 4 "Failure" 5 "reserved" ;
VAL_ 395 RelTgtObjVel_X 0 "Valid_values" 252 "Reserved" ;
VAL_ 395 TimeToCllsn 0 "Valid_value" 251 "Reserved" ;
VAL_ 576 RollingCounter_IFC_HCM7 0 "Valid_value" 15 "Invalid_value" ;
VAL_ 576 Spots7VehObjClassn 0 "No_Vehicle" 1 "Car" 2 "Truck" 3 "Bus" 4 "BikeOrMotoBike" 5 "Pedestrain" 6 "Mixed" 7 "Unknow" ;
VAL_ 576 Spots7TrackingInfo 0 "Not_Tracking" 1 "Tracking" ;
VAL_ 576 Spot7VertAng 0 "Valid_Values" ;
VAL_ 576 Spots7HozLeAngSpd 0 "Valid_Values" ;
VAL_ 576 Spots7Distance 0 "valid_value" 511 "NotAvailable" ;
VAL_ 576 Spots7Typ 0 "Unknown" 1 "Oncoming_object" 2 "Preceding_object" 3 "Reflective_object" ;
VAL_ 576 Spots7Valid 0 "Invalid" 1 "Valid" ;
VAL_ 576 Spots7HozlPosnRiAng 0 "valid_value" 1001 "Reserved" 1023 "NotAvailable" ;
VAL_ 576 Spots7HozlPosnLeAng 0 "valid_value" 1001 "Reserved" 1023 "NotAvailable" ;
VAL_ 576 Checksum_IFC_HCM7 0 "Valid_values" ;
VAL_ 576 RollingCounter_IFC_HCM6 0 "Valid_value" 15 "Invalid_value" ;
VAL_ 576 Spots6VehObjClassn 0 "No_Vehicle" 1 "Car" 2 "Truck" 3 "Bus" 4 "BikeOrMotoBike" 5 "Pedestrain" 6 "Mixed" 7 "Unknow" ;
VAL_ 576 Spots6TrackingInfo 0 "Not_Tracking" 1 "Tracking" ;
VAL_ 576 Spot6VertAng 0 "Valid_Values" ;
VAL_ 576 Spots6HozLeAngSpd 0 "Valid_Values" ;
VAL_ 576 Spots6Distance 0 "valid_value" 511 "NotAvailable" ;
VAL_ 576 Spots6Typ 0 "Unknown" 1 "Oncoming_object" 2 "Preceding_object" 3 "Reflective_object" ;
VAL_ 576 Spots6Valid 0 "Invalid" 1 "Valid" ;
VAL_ 576 Spots6HozlPosnRiAng 0 "valid_value" 1001 "Reserved" 1023 "NotAvailable" ;
VAL_ 576 Spots6HozlPosnLeAng 0 "valid_value" 1001 "Reserved" 1023 "NotAvailable" ;
VAL_ 576 Checksum_IFC_HCM6 0 "Valid_values" ;
VAL_ 576 RollingCounter_IFC_HCM5 0 "Valid_value" 15 "Invalid_value" ;
VAL_ 576 Spots5VehObjClassn 0 "No_Vehicle" 1 "Car" 2 "Truck" 3 "Bus" 4 "BikeOrMotoBike" 5 "Pedestrain" 6 "Mixed" 7 "Unknow" ;
VAL_ 576 Spots5TrackingInfo 0 "Not_Tracking" 1 "Tracking" ;
VAL_ 576 Spot5VertAng 0 "Valid_Values" ;
VAL_ 576 Spots5HozLeAngSpd 0 "Valid_Values" ;
VAL_ 576 Spots5Distance 0 "valid_value" 511 "NotAvailable" ;
VAL_ 576 Spots5Typ 0 "Unknown" 1 "Oncoming_object" 2 "Preceding_object" 3 "Reflective_object" ;
VAL_ 576 Spots5Valid 0 "Invalid" 1 "Valid" ;
VAL_ 576 Spots5HozlPosnRiAng 0 "valid_value" 1001 "Reserved" 1023 "NotAvailable" ;
VAL_ 576 Spots5HozlPosnLeAng 0 "valid_value" 1001 "Reserved" 1023 "NotAvailable" ;
VAL_ 576 Checksum_IFC_HCM5 0 "Valid_values" ;
VAL_ 576 RollingCounter_IFC_HCM4 0 "Valid_value" 15 "Invalid_value" ;
VAL_ 576 Spots4VehObjClassn 0 "No_Vehicle" 1 "Car" 2 "Truck" 3 "Bus" 4 "BikeOrMotoBike" 5 "Pedestrain" 6 "Mixed" 7 "Unknow" ;
VAL_ 576 Spots4TrackingInfo 0 "Not_Tracking" 1 "Tracking" ;
VAL_ 576 Spot4VertAng 0 "Valid_Values" ;
VAL_ 576 Spots4HozLeAngSpd 0 "Valid_Values" ;
VAL_ 576 Spots4Distance 0 "valid_value" 511 "NotAvailable" ;
VAL_ 576 Spots4Typ 0 "Unknown" 1 "Oncoming_object" 2 "Preceding_object" 3 "Reflective_object" ;
VAL_ 576 Spots4Valid 0 "Invalid" 1 "Valid" ;
VAL_ 576 Spots4HozlPosnRiAng 0 "valid_value" 1001 "Reserved" 1023 "NotAvailable" ;
VAL_ 576 Spots4HozlPosnLeAng 0 "valid_value" 1001 "Reserved" 1023 "NotAvailable" ;
VAL_ 576 Checksum_IFC_HCM4 0 "Valid_values" ;
VAL_ 576 RollingCounter_IFC_HCM3 0 "Valid_value" 15 "Invalid_value" ;
VAL_ 576 Spots3VehObjClassn 0 "No_Vehicle" 1 "Car" 2 "Truck" 3 "Bus" 4 "BikeOrMotoBike" 5 "Pedestrain" 6 "Mixed" 7 "Unknow" ;
VAL_ 576 Spots3TrackingInfo 0 "Not_Tracking" 1 "Tracking" ;
VAL_ 576 Spot3VertAng 0 "Valid_Values" ;
VAL_ 576 Spots3HozLeAngSpd 0 "Valid_Values" ;
VAL_ 576 Spots3Distance 0 "valid_value" 511 "NotAvailable" ;
VAL_ 576 Spots3Typ 0 "Unknown" 1 "Oncoming_object" 2 "Preceding_object" 3 "Reflective_object" ;
VAL_ 576 Spots3Valid 0 "Invalid" 1 "Valid" ;
VAL_ 576 Spots3HozlPosnRiAng 0 "valid_value" 1001 "Reserved" 1023 "NotAvailable" ;
VAL_ 576 Spots3HozlPosnLeAng 0 "valid_value" 1001 "Reserved" 1023 "NotAvailable" ;
VAL_ 576 Checksum_IFC_HCM3 0 "Valid_values" ;
VAL_ 576 RollingCounter_IFC_HCM2 0 "Valid_value" 15 "Invalid_value" ;
VAL_ 576 Spots2VehObjClassn 0 "No_Vehicle" 1 "Car" 2 "Truck" 3 "Bus" 4 "BikeOrMotoBike" 5 "Pedestrain" 6 "Mixed" 7 "Unknow" ;
VAL_ 576 Spots2TrackingInfo 0 "Not_Tracking" 1 "Tracking" ;
VAL_ 576 Spot2VertAng 0 "Valid_Values" ;
VAL_ 576 Spots2HozLeAngSpd 0 "Valid_Values" ;
VAL_ 576 Spots2Distance 0 "valid_value" 511 "NotAvailable" ;
VAL_ 576 Spots2Typ 0 "Unknown" 1 "Oncoming_object" 2 "Preceding_object" 3 "Reflective_object" ;
VAL_ 576 Spots2Valid 0 "Invalid" 1 "Valid" ;
VAL_ 576 Spots2HozlPosnRiAng 0 "valid_value" 1001 "Reserved" 1023 "NotAvailable" ;
VAL_ 576 Spots2HozlPosnLeAng 0 "valid_value" 1001 "Reserved" 1023 "NotAvailable" ;
VAL_ 576 Checksum_IFC_HCM2 0 "Valid_values" ;
VAL_ 576 RollingCounter_IFC_HCM1 0 "Valid_value" 15 "Invalid_value" ;
VAL_ 576 Spots1VehObjClassn 0 "No_Vehicle" 1 "Car" 2 "Truck" 3 "Bus" 4 "BikeOrMotoBike" 5 "Pedestrain" 6 "Mixed" 7 "Unknow" ;
VAL_ 576 Spots1TrackingInfo 0 "Not_Tracking" 1 "Tracking" ;
VAL_ 576 Spot1VertAng 0 "Valid_Values" ;
VAL_ 576 Spots1HozLeAngSpd 0 "Valid_Values" ;
VAL_ 576 Spots1Distance 0 "valid_value" 511 "NotAvailable" ;
VAL_ 576 Spots1Typ 0 "Unknown" 1 "Oncoming_object" 2 "Preceding_object" 3 "Reflective_object" ;
VAL_ 576 Spots1Valid 0 "Invalid" 1 "Valid" ;
VAL_ 576 Spots1HozlPosnRiAng 0 "valid_value" 1001 "Reserved" 1023 "NotAvailable" ;
VAL_ 576 Spots1HozlPosnLeAng 0 "valid_value" 1001 "Reserved" 1023 "NotAvailable" ;
VAL_ 576 Checksum_IFC_HCM1 0 "Valid_values" ;
VAL_ 667 HAVP_LrngDst 0 "Valid_values" 1023 "No_Display" ;
VAL_ 667 PAVP_ScFail_info 0 "Idle" 1 "Camera fault" 2 "Ultrasonic fault" 3 "AVP HW fault" 4 "AVP SW fault" 5 "AVP Eth1 connection fault" 6 "AVP Eth2 connection fault" 7 "Chasis&Powertrain ECU fault" 8 "Reserved" ;
VAL_ 667 HAVP_ScFail_info 0 "Idle" 1 "Front Wide Camera fault" 2 "Around View Camera fault" 3 "Ultrasonic fault" 4 "Controller HW fault" 5 "Controller SW fault" 6 "Reserved" ;
VAL_ 667 UnPrkgSpaReasons 0 "Initial_value" 1 "The_environment_is_dark" 2 "Slot_narrow" 3 "Passage_narrow" 4 "Far_from_the_slot" 5 "Ground_lock_is_opened" 6 "Slot_is_occupied" 7 "Wheelstopper_invade" 8 "Truck_invade" 9 "Vehicle_invade" 10 "Cone_barrel_invade" 11 "Pedestrian_invade" 12 "Pillar_invade" 13 "Bushes_invade" 14 "Tree_invade" 15 "Fire_fighting_facilities_invade" 16 "Charging_equipment_invade" 17 "Unknown" 18 "Vehicles_can_be_taken_over_in_advance" 19 "You_have_taken_over_the_vehicle" 20 "Obstacles_near_the_vehicle_please_step_back_and_try_again" ;
VAL_ 674 RP_Num_Points_Per_Tube 0 "Valid Value" ;
VAL_ 674 RP_Algo_MCU_TimeStamp 0 "Valide Value" ;
VAL_ 674 RP_Shock_Dist_R 0 "Valid_Value" 1004 "Reserved" 1023 "Invalid_Value" ;
VAL_ 674 RP_Shock_Height_R 0 "Valid_Value" 301 "Reserved" 511 "Invalid_Value" ;
VAL_ 674 RP_Shock_Dist_L 0 "Valid_Value" 1004 "Reserved" 1023 "Invalid_Value" ;
VAL_ 674 RP_Shock_Confidence_L 0 "Valid_Value" 101 "Reserved" 127 "Invalid_Value" ;
VAL_ 674 RP_Shock_Height_L 0 "Valid_Value" 301 "Reserved" 511 "Invalid_Value" ;
VAL_ 674 RP_Shock_Detected_R 0 "NO_SHOCK_DETECTED" 1 "SHOCK_DETECTED" ;
VAL_ 674 RP_Shock_Detected_L 0 "NO_SHOCK_DETECTED" 1 "SHOCK_DETECTED" ;
VAL_ 674 RP_New_Measurment 0 "FALSE" 1 "TRUE" ;
VAL_ 674 RP_Valid 0 "FALSE" 1 "TRUE" ;
VAL_ 674 RP_Shock_Confidence_R 0 "Valid_Value" 101 "Reserved" 127 "Invalid_Value" ;
VAL_ 674 RP_Start_Point_Distance 0 "Valid Value" ;
VAL_ 674 RP_Used_Speed 0 "Valid_Value" 2201 "Reserved" 4095 "Invalide_Value" ;
VAL_ 674 RP_Sync_ID 0 "Valid Value" ;
VAL_ 786 ADCCoolReq 0 "Initial_value" 1 "No_Request" 2 "Request" ;
VAL_ 786 MDC_AverTemp 0 "Valid" 255 "Invalid" ;
VAL_ 786 MDC_MaxTemp 0 "Valid" 255 "Invalid" ;
VAL_ 786 CWRoadSignActvSts 0 "Initial_value" 1 "No_Active" 2 "Active" ;
VAL_ 786 MDC_ThmPostRun 0 "Inactive" 1 "Active" ;
VAL_ 786 MDC_FlowReq 0 "Valid" 17 "Reserved" ;
VAL_ 573 SceneModSts 0 "Initial_value" 1 "Rainy_Mode" 2 "Snowy_Mode" 3 "Foggy_Mode" ;
VAL_ 573 IFC_Line_special02_Curv 0 "Valid_value" 31251 "Reversed" ;
VAL_ 573 IFC_Line_special01_DxEnd 0 "Valid_value" 20002 "Reversed" ;
VAL_ 573 IFC_Line_special01_DxStart 0 "Valid_value" 20002 "Reversed" ;
VAL_ 573 ACC_LeTgtObjBarDisp_03 0 "No_display" 1 "Distance_1_one_bar" 2 "Distance_2_two_bars" 3 "Distance_3_three_bars" 4 "Distance_4_four_bars" 5 "Resvered" ;
VAL_ 573 TargetPathC1 0 "Valid_value" 402 "Reversed" ;
VAL_ 573 ACC_RiTgtObjBarDisp_02 0 "No_display" 1 "Distance_1_one_bar" 2 "Distance_2_two_bars" 3 "Distance_3_three_bars" 4 "Distance_4_four_bars" 5 "Resvered" ;
VAL_ 573 IFC_Line_special01_CurvChange 0 "Valid_value" 960001 "Reversed" ;
VAL_ 573 IFC_Line_special01_Curv 0 "Valid_value" 31251 "Reversed" ;
VAL_ 573 ACC_LeTgtObjBarDisp_02 0 "No_display" 1 "Distance_1_one_bar" 2 "Distance_2_two_bars" 3 "Distance_3_three_bars" 4 "Distance_4_four_bars" 5 "Resvered" ;
VAL_ 573 SidePrkgSts 0 "Initial_value" 1 "OFF" 2 "ON" 3 "Resvered" ;
VAL_ 573 HandsoffModSts 0 "Initial_value" 1 "HandsOff" 2 "Attention_And_HandsOff" ;
VAL_ 573 HandsoffTimSts 0 "Initial" 1 "Handsoff_time_is_normal" 2 "Handsoff_time_is_long" 3 "Reserved" ;
VAL_ 573 ACC_TgtObjBarDisp_03 0 "No_display" 1 "Distance_1_one_bar" 2 "Distance_2_two_bars" 3 "Distance_3_three_bars" 4 "Distance_4_four_bars" 5 "Resvered" ;
VAL_ 573 ACC_TgtObjBarDisp_02 0 "No_display" 1 "Distance_1_one_bar" 2 "Distance_2_two_bars" 3 "Distance_3_three_bars" 4 "Distance_4_four_bars" 5 "Resvered" ;
VAL_ 573 IFC_Line_special01_Dy 0 "Valid_value" 6002 "Reversed" ;
VAL_ 573 IFC_NextRiLane_dy 0 "Valid value" 4095 "Invalid value" ;
VAL_ 573 IFC_NextLeLane_dy 0 "Valid value" 4095 "Invalid value" ;
VAL_ 573 SmarFrontviewcamSts 0 "Initial_value" 1 "Available" 2 "Unavailable" 3 "Soc_off" ;
VAL_ 573 IFC_RiLane_dy 0 "Valid value" 4095 "Invalid value" ;
VAL_ 573 IFC_LeLane_dy 0 "Valid value" 4095 "Invalid value" ;
VAL_ 573 IFC_NextRiLaneTyp 0 "No display" 1 "Solid lane" 2 "Dashed lane" 3 "Rode edge" 4 "Reserved" ;
VAL_ 573 IFC_NextLeLaneTyp 0 "No display" 1 "Solid lane" 2 "Dashed lane" 3 "Rode edge" 4 "Reserved" ;
VAL_ 573 IFC_RiLaneTyp 0 "No display" 1 "Solid lane" 2 "Dashed lane" 3 "Rode edge" 4 "Reserved" ;
VAL_ 573 IFC_LeLaneTyp 0 "No display" 1 "Solid lane" 2 "Dashed lane" 3 "Rode edge" 4 "Reserved" ;
VAL_ 573 IFC_LaneCurve 0 "Valid value" 4095 "Reserved" ;
VAL_ 573 ESSintervention 0 "No intervention" 1 "Left intervention" 2 "Right intervention" 3 "Reserved" ;
VAL_ 573 AESintervention 0 "No intervention" 1 "Left intervention" 2 "Right intervention" 3 "Reserved" ;
VAL_ 573 IFC_Line_special02_Type 0 "Undecided" 1 "Solid" 2 "Dashed" 3 "Double_solid_dashed" 4 "Double_dashed_solid" 5 "Double_solid_solid" 6 "Double_dashed_dashed" 7 "Botts" 8 "Deceleration" 9 "Hov_lane" 10 "Road_edge" 11 "Elevated_structure" 12 "Curb" 13 "Cones_poles" 14 "Reversed" ;
VAL_ 573 IFC_Line_special01_Type 0 "Undecided" 1 "Solid" 2 "Dashed" 3 "Double_solid_dashed" 4 "Double_dashed_solid" 5 "Double_solid_solid" 6 "Double_dashed_dashed" 7 "Botts" 8 "Deceleration" 9 "Hov_lane" 10 "Road_edge" 11 "Elevated_structure" 12 "Curb" 13 "Cones_poles" 14 "Reversed" ;
VAL_ 573 IFC_Line_special02_HeadingAngle 0 "Valid_value" 402 "Reversed" ;
VAL_ 573 LCKStsIndcr 0 "No indicator" 1 "Active indicator" 2 "Passive indicator" 3 "Reserved" ;
VAL_ 573 IntelligentEvaActSts 0 "Inactive" 1 "Left Eva" 2 "Right Eva" 3 "IntelligentDetour" ;
VAL_ 573 ELKActSts 0 "Inactive" 1 "Left Active" 2 "Right active" 3 "Reserved" ;
VAL_ 573 CameraBlockageSts 0 "Camera Not Blocked" 1 "Camera Blocked" ;
VAL_ 573 IFCCalibrationSts 0 "Calibration Success" 1 "Calibration In Process" 2 "Calibration Failed" 3 "Reserved" ;
VAL_ 573 IFC_Handsoffwarn 0 "No warning" 1 "Level1 warning" 2 "Level2 warning" 3 "Level3 warning" 4 "Level4 warning" 5 "Level5 warning" 6 "LKA warning" 7 "Level6 Warning" ;
VAL_ 573 LSSErrSts 0 "No error" 1 "LDW error" 2 "LKA error" 3 "LCK error" 4 "ELK error" 5 "ESS error" 6 "LSS temporarily unavailable" 7 "Reserved" ;
VAL_ 573 TJA_FollowSts 0 "No Follow" 1 "Follow Vehicle" 2 "Reserved" ;
VAL_ 573 LaneAvailability 0 "Not Avaliable" 1 "Left Lane Marker Available" 2 "Right Lane Marker Available" 3 "Both Lane Markers Available" ;
VAL_ 573 ELKMainState 0 "ELK-OFF(关闭)" 1 "ELK-Standby(开启)" 2 "ELK-Enable(已使能，不满足扭矩介入条件)" 3 "ELK-Road edge Active(道路边缘扭矩介入)" 4 "ELK-Oncoming Active（oncoming扭矩介入）" 5 "ELK-Overtaking Active（overtaking扭矩介入）" 6 "ELK-Failure" 7 "Reserved" ;
VAL_ 573 LSSFuncSts 0 "OFF" 1 "LDW on" 2 "LKA on" 3 "LCK ON" 4 "Reserved" ;
VAL_ 573 LSSIntervention 0 "No warning and Intervention" 1 "Left warning" 2 "Right warning" 3 "Left Intervention" 4 "Right Intervention" 5 "Both Intervention" 6 "Left warn only reminder" 7 "Right warn only reminder" ;
VAL_ 573 LDW_LKAWarn 0 "No LDW_LKA warning" 1 "LDW_LKA left warning" 2 "LDW_LKA right warning" 3 "Reserved" ;
VAL_ 573 LCP_Warn 0 "Initial_value" 1 "Left_Warn" 2 "Right_Warn" 3 "Error" ;
VAL_ 573 IFC_Line_special01_HeadingAngle 0 "Valid_value" 402 "Reversed" ;
VAL_ 573 RiRoad_Mark_Dy 0 "Validvalue" 161 "Reserved" ;
VAL_ 573 RiRoad_Mark_Dx 0 "Validvalue_0-150m" 301 "Reserved" ;
VAL_ 573 RiRoad_Mark_Typ 0 "Default" 1 "ARROW_STRAIGHT" 2 "ARROW_RIGHT" 3 "ARROW_LEFT" 4 "ARROW_STRAIGHT_RIGHT" 5 "ARROW_STRAIGHT_LEFT" 6 "ARROW_STRAIGHT_LEFT_RIGHT" 7 "ARROW_LEFT_RIGHT" 8 "U_TURN_LEFT" 9 "U_TURN_RIGHT" 10 "DIAMOND" 11 "BUS" 12 "Reserved" ;
VAL_ 573 ESSErrSts 0 "No Error" 1 "Error" ;
VAL_ 573 AESErrSts 0 "No Error" 1 "Error" ;
VAL_ 573 ESSSts 0 "OFF" 1 "ON" 2 "Reserved" ;
VAL_ 573 AESSts 0 "OFF" 1 "ON" 2 "Reserved" ;
VAL_ 573 IntelligentEvaResp 0 "OFF" 1 "ON" ;
VAL_ 573 LSSResp 0 "OFF" 1 "ON" ;
VAL_ 573 LSSWarnFormResp 0 "Voice" 1 "Haptic" 2 "Voice+Haptic" 3 "Reserved" ;
VAL_ 573 ESS_VehResp 0 "OFF" 1 "ON" ;
VAL_ 573 ESS_PedResp 0 "OFF" 1 "ON" ;
VAL_ 573 IFCHUTInterface 0 "No response" 1 "Response" ;
VAL_ 573 LDW_LKA_Snvty 0 "Normal" 1 "High sensitivity" 2 "Low sensitivity" 3 "Reserved" ;
VAL_ 573 AESResp 0 "OFF" 1 "ON" ;
VAL_ 573 ELKResp 0 "OFF" 1 "ON" ;
VAL_ 573 LCKResp 0 "OFF" 1 "ON" ;
VAL_ 573 LKAResp 0 "OFF" 1 "ON" ;
VAL_ 573 LDWResp 0 "OFF" 1 "ON" ;
VAL_ 573 LeRoad_Mark_Typ 0 "Default" 1 "ARROW_STRAIGHT" 2 "ARROW_RIGHT" 3 "ARROW_LEFT" 4 "ARROW_STRAIGHT_RIGHT" 5 "ARROW_STRAIGHT_LEFT" 6 "ARROW_STRAIGHT_LEFT_RIGHT" 7 "ARROW_LEFT_RIGHT" 8 "U_TURN_LEFT" 9 "U_TURN_RIGHT" 10 "DIAMOND" 11 "BUS" 12 "Reserved" ;
VAL_ 573 LeRoad_Mark_Dy 0 "Validvalue" 161 "Reserved" ;
VAL_ 573 Road_Mark_Dy 0 "Validvalue_0-16m" 161 "Reserved" ;
VAL_ 573 LeRoad_Mark_Dx 0 "Validvalue_0-150m" 301 "Reserved" ;
VAL_ 573 Road_Mark_Dx 0 "Validvalue_0-150m" 301 "Reserved" ;
VAL_ 573 Road_Mark_Typ 0 "Default" 1 "ARROW_STRAIGHT" 2 "ARROW_RIGHT" 3 "ARROW_LEFT" 4 "ARROW_STRAIGHT_RIGHT" 5 "ARROW_STRAIGHT_LEFT" 6 "ARROW_STRAIGHT_LEFT_RIGHT" 7 "ARROW_LEFT_RIGHT" 8 "U_TURN_LEFT" 9 "U_TURN_RIGHT" 10 "DIAMOND" 11 "BUS" 12 "Reserved" ;
VAL_ 573 HWA_Text_Lib 0 "Default" 1 "Cancel_for_long_override" 2 "Cancel_for_lat_override" 3 "Avoid_obstacle" 4 "ISL" 5 "Start_confirm" 6 "Follow_confirm" 7 "Long_override" 8 "Over_speed" 9 "LC_not_cancel" 10 "Adverse_weather" 11 "System_fault" 12 "NOH_fault" 13 "NOH_standby" 14 "NOH_degrade" 15 "Ddverse_weather2" 17 "Function_inhibit" 18 "Pilot_fail" 19 "Avoid_obstacle2" 20 "Auto_spd" 21 "NOH_inhibit" 22 "Restart_to_activate_ALC" 23 "4s_store_to_debug_ALC" 24 "Attention_to_surrounding" 25 "Turn_off_signal" 26 "Speed_is_too_high_to_support_intelligent_cruise" 27 "U_turn_warning" 28 "Roundabout_warning" 29 "Manually_switch_route" 30 "Too_late_to_change_lane" 31 "Off_the_planed_route" 32 "Speeding" 33 "TJA_is_suspend" 34 "Exiting_soon" 35 "Navigation_Left_Lane_Change" 36 "Navigation_Right_Lane_Change" 37 "Transit_Lane" 38 "Left_Lane_Change_Due_Barrier" 39 "Right_Lane_Change_Due_Barrier" 40 "Stay_Away_From_The_Cart" 41 "Abouchement" 42 "Function_About_To_Exit" 43 "Passing_Direction" 44 "Red_Light_Running_Risk" 45 "Road_Pattern_Left_Change" 46 "Construction_ahead_move_slowly" 47 "Departing_Pedestrian" 48 "Stay_away_from_construction" 49 "Cut_In_Car" 50 "Extremity_Land_Change" 51 "Land_Change_Due_To_Special_Lane" 52 "Special_Lane" 53 "TJA_ICA_Resumed" 54 "Change_Lanes_On_Solid_Lines" 55 "Unable_To_Turn" 56 "Attention_Electronic_Eye" 57 "Attention_To_Road_Switching" 58 "Short_Distance" 59 "Driving_Mode" 60 "Safety_Belt" 61 "Lane_Error" 62 "Through_Gate" 63 "Urban_Access_Road" ;
VAL_ 573 IFC_FeatPt_Type 0 "No_display" 1 "Main_road" 2 "Road_split" 3 "Lane_end" 4 "Crossing" 5 "T-junction" 6 "Roundabout" 10 "Guide_line" 11 "Waiting_area" 12 "VLB" 13 "Reserved" ;
VAL_ 411 RHeadLmpFailSts 0 "No failure" 1 "failure" ;
VAL_ 411 LHeadLmpFailSts 0 "No failure" 1 "failure" ;
VAL_ 411 HoodSts_F_PBox 0 "Closed" 1 "Open" ;
VAL_ 411 FFogLmpFailSts 0 "No_failure" 1 "Left_front_side_failure" 2 "Right_front_side_failure" 3 "both_front_side_failure" ;
VAL_ 411 FFogLmpSts_F_PBox 0 "Off" 1 "On" ;
VAL_ 411 LowBeamSts_F_PBox 0 "Off" 1 "On" ;
VAL_ 411 HiBeamSts_F_PBox 0 "Off" 1 "On" ;
VAL_ 412 RFogLmpSts_R_PBox 0 "Off" 1 "On" ;
VAL_ 412 RFogLmpFailSts_R_PBox 0 "No failure" 1 "failure" ;
VAL_ 412 RTurnLmpSts_R_PBox 0 "Off" 1 "On" ;
VAL_ 412 LTurnLmpSts_R_PBox 0 "Off" 1 "On" ;
VAL_ 412 LTurnLmpFailSts 0 "No failure" 1 "Short circuit" 2 "Open circuit" 3 "Reserved" ;
VAL_ 412 RTurnLmpFailSts 0 "No failure" 1 "Short circuit" 2 "Open circuit" 3 "Reserved" ;
VAL_ 412 PosnLmpOutpSts_R_PBox 0 "OFF" 1 "ON" ;
VAL_ 412 RBrkLmpFailSts 0 "No failure" 1 "failure" ;
VAL_ 412 LBrkLmpFailSts 0 "No failure" 1 "failure" ;
VAL_ 412 HiPosnBrkLmpFailSts 0 "No failure" 1 "failure" ;
VAL_ 833 TPMS_AutoLoctSts 0 "Auto-Learn or Auto-Locate not in progress / TPMS is base system" 1 "Auto-Learn in progress" 2 "Auto-Locate in progress (Auto-Learn complete)" 3 "Auto-Locate complete" 4 "Auto-Learn timeout" 5 "Auto-Locate timeout" 6 "Reserved" ;
VAL_ 833 RRTireTempSts 0 "Normal" 1 "High" 2 "Not available" 3 "Reserved" ;
VAL_ 833 RLTireTempSts 0 "Normal" 1 "High" 2 "Not available" 3 "Reserved" ;
VAL_ 833 FRTireTempSts 0 "Normal" 1 "High" 2 "Not available" 3 "Reserved" ;
VAL_ 833 FLTireTempSts 0 "Normal" 1 "High" 2 "Not available" 3 "Reserved" ;
VAL_ 833 RRTirePressIndSts 0 "Normal" 1 "Low" 2 "Reserved" 3 "High" 4 "Not available" 5 "Reserved" ;
VAL_ 833 RLTirePressIndSts 0 "Normal" 1 "Low" 2 "Reserved" 3 "High" 4 "Not available" 5 "Reserved" ;
VAL_ 833 TirePressSysFailrIndcn 0 "No failure" 1 "Failure" 2 "Reserved" ;
VAL_ 833 FRTirePressIndSts 0 "Normal" 1 "Low" 2 "Reserved" 3 "High" 4 "Not available" 5 "Reserved" ;
VAL_ 833 FLTirePressIndSts 0 "Normal" 1 "Low" 2 "Reserved" 3 "High" 4 "Not available" 5 "Reserved" ;
VAL_ 837 EnvModDetn 0 "Day" 1 "Night" 2 "Tunnel" 3 "Darkstart" ;
VAL_ 837 HiLowBeamSts 0 "Off" 1 "ON" 2 "error" 3 "Reserved" ;
VAL_ 837 DrvDoorLockSts 0 "Lock" 1 "Unlock" ;
VAL_ 837 HazardLmpSwtSts 0 "Off" 1 "On" ;
VAL_ 837 DoorLockSts 0 "NA" 1 "All doors locked" 2 "Driver door unlocked" 3 "All doors unlocked" ;
VAL_ 473 OTApowertrainmode 0 "NO_action" 1 "Powertrain_ON" 2 "Powertrain_OFF" 3 "Reserved" ;
VAL_ 568 SrPosn_VR_APP 0 "Tilt up" 1 "reserved" 10 "10%" 11 "reserved" 20 "20%" 21 "reserved" 30 "30%" 31 "reserved" 40 "40%" 41 "reserved" 50 "50%" 51 "reserved" 60 "60%" 61 "reserved" 70 "70%" 71 "reserved" 80 "80%" 81 "reserved" 90 "90%" 91 "reserved" 100 "Fully open" 101 "Fully close" 102 "Vent area" 103 "reserved" ;
VAL_ 568 RLS_AmbBrightness 0 "Vaild value" 4095 "Invaild" ;
VAL_ 568 RLS_FwBrightness 0 "Vaild value" 4095 "Invaild" ;
VAL_ 569 BasicFunReq 0 "No_Control" 1 "Valid_values" ;
VAL_ 569 BasicFunID 0 "No_Control" 1 "Valid_values" 255 "End" ;
VAL_ 661 SysPowerModVld 0 "Invalid" 1 "Valid" ;
VAL_ 661 SysPowerMod 0 "OFF" 1 "ACC (reserved)" 2 "ON" 3 "Crank" ;
VAL_ 671 RollingCounter_BCM8 0 "Valid value" 15 "Invalid value" ;
VAL_ 671 KL30BRelaySts 0 "Off" 1 "On" ;
VAL_ 671 WiprReq_F_PBox 0 "Wiper Off" 1 "Wiper action once" 2 "Speed1 (Lo)" 3 "Speed2 (Hi)" 4 "Reserved" 7 "Invalid" ;
VAL_ 671 RViewMirrorSts 0 "Unfold" 1 "Fold" ;
VAL_ 671 RSDS_RLEDSts 0 "No_Error" 1 "Error" ;
VAL_ 671 RSDS_LLEDSts 0 "No_Error" 1 "Error" ;
VAL_ 671 PASWorkCmd 0 "OFF" 1 "ON" ;
VAL_ 671 RemoteModSts 0 "Normal mode" 1 "Remote mode" ;
VAL_ 671 PASSwtErrSts 0 "Closed" 1 "Open" ;
VAL_ 671 PASSwtReq 0 "Backlight OFF" 1 "Backlight ON" ;
VAL_ 671 Checksum_BCM8 0 "Valid values" ;
VAL_ 699 OTA_UpgrdModSts 0 "Upgrade_mode_Off" 1 "Remote_upgrade_mode_ON_Powertrain_OFF" 2 "Normal_upgrade_mode_ON_Powertrain_OFF" 3 "Reserved" ;
VAL_ 783 LowBeamReq 0 "Off" 1 "On" ;
VAL_ 783 WiprReq 0 "Wiper Off" 1 "Wiper action once" 2 "Speed1_low" 3 "Speed2_high" 4 "Reserved" 7 "Signal not available" ;
VAL_ 783 ACZoneSwtErrSts 0 "No_Error" 1 "Error" ;
VAL_ 783 ACZoneSwtSts 0 "No_Request" 1 "Request" ;
VAL_ 783 HazardLmpSts 0 "OFF" 1 "ON" ;
VAL_ 793 RollingCounter_BCM1 0 "Valid_value" 15 "Invalid_value" ;
VAL_ 793 PosnLightReq 0 "OFF" 1 "ON" ;
VAL_ 793 LowBeamSts 0 "Off" 1 "On" ;
VAL_ 793 RLSFailSts 0 "No_failure" 1 "Failure" ;
VAL_ 793 HoodSts 0 "Closed" 1 "Open" ;
VAL_ 793 ReversGearSts 0 "Off" 1 "On" 2 "Reserved" 3 "Not available" ;
VAL_ 793 BrkPedalSts_BCM 0 "OFF" 1 "ON" ;
VAL_ 793 WindshldWiprActvSts 0 "Not active" 1 "Active" ;
VAL_ 793 RRDoorSts 0 "Closed" 1 "Open" ;
VAL_ 793 PassengerDoorSts 0 "Closed" 1 "Open" ;
VAL_ 793 LRDoorSts 0 "Closed" 1 "Open" ;
VAL_ 793 DrvDoorSts 0 "Closed" 1 "Open" ;
VAL_ 793 TrunkSts 0 "Closed" 1 "Open" ;
VAL_ 793 HiBeamSts 0 "Off" 1 "On" ;
VAL_ 793 Checksum_BCM1 0 "Valid_values" ;
VAL_ 917 RRTireTemp 0 "Valid Value" 255 "Invalid Value" ;
VAL_ 917 RRTirePress 0 "Valid Value" 255 "Invalid Value" ;
VAL_ 917 RLTireTemp 0 "Valid Value" 255 "Invalid Value" ;
VAL_ 917 RLTirePress 0 "Valid Value" 255 "Invalid Value" ;
VAL_ 917 FRTireTemp 0 "Valid Value" 255 "Invalid Value" ;
VAL_ 917 FRTirePress 0 "Valid Value" 255 "Invalid Value" ;
VAL_ 917 FLTireTemp 0 "Valid Value" 255 "Invalid Value" ;
VAL_ 917 FLTirePress 0 "Valid Value" 255 "Invalid Value" ;
VAL_ 165 DoorHndlBtnActn 0 "No_Action" 1 "Main_Door_Handle_Click" 2 "Main_Door_Handle_Tap_and_hold" 3 "Passenger_door_handle_Click" 4 "Passenger_door_handle_Tap_and_hold" ;
VAL_ 165 PhyKeyPressActn 0 "No_Action" 1 "Key_unlock_Tap_and_hold" 2 "Click_any_key" 3 "Block_keyTap_and_hold" ;
VAL_ 165 PhyKeyPosnSts 0 "No_Action" 1 "Inside" 2 "Outside" ;
VAL_ 259 IdleSpdSts 0 "Not_In_Idle_Speed_Ststus" 1 "Idle_Speed_Status" ;
VAL_ 259 IdleCtrlWhlTrq 0 "Initial_value" 1 "Valid_values" ;
VAL_ 259 EngState_PHEV 0 "Stand by" 1 "Ready" 2 "Cranking" 3 "Running" 4 "Stopping" 5 "Finish" 6 "Autostopping" 7 "Reserved" ;
VAL_ 259 RollingCounter_ECM2 0 "Valid_value" 15 "Invalid_value" ;
VAL_ 259 EngState 0 "Stopped" 1 "Cranking" 2 "Running" 3 "Stalling" ;
VAL_ 259 AccelPedalPosnVldty 0 "Invalid" 1 "Valid" 2 "Init_value" 3 "Reserved" ;
VAL_ 259 AccelPedalPosn 0 "Valid_values" ;
VAL_ 259 Checksum_ECM2 0 "Valid_values" ;
VAL_ 259 RollingCounter_ECM9 0 "Valid_value" 15 "Invalid_value" ;
VAL_ 259 AccelPedlPosnDiagc 0 "Valid_values" ;
VAL_ 259 EngTgtIdleSpd 0 "Valid values" ;
VAL_ 259 Checksum_ECM9 0 "Valid_values" ;
VAL_ 273 EngSpdVldty 0 "InValid values" 1 "Valid values" 2 "Init value" 3 "Reserved" ;
VAL_ 273 EngSpd 0 "Valid values" ;
VAL_ 283 VMCFucActvSts 0 "Initial_value" 1 "NoVMCFunctionActive" 2 "VACActiveAndPSCNotActive" 3 "VACActiveAndPSCActive" 4 "ITRActive" 5 "VACNotActiveAndPSCActive" 6 "CWCActive" 7 "SRCActive" 8 "BSCActive" 9 "BSCNotActiveAndWheelError" 10 "CCSActv" ;
VAL_ 283 VCU_DrvReqTqWhl_FA 0 "Vaild_Value" 32767 "Invalid" ;
VAL_ 283 VCU_DrvReqTqWhl_RA 0 "Vaild_Value" 32767 "Invalid" ;
VAL_ 283 HCU_VirtLoad_FA 0 "_0_Percent" 1 "_5_Percent" 2 "_10_Percent" 3 "_15_Percent" 4 "_20_Percent" 5 "_25_Percent" 6 "_30_Percent" 7 "_35_Percent" 8 "_40_Percent" 9 "_45_Percent" 10 "_50_Percent" 11 "_55_Percent" 12 "_60_Percent" 13 "_65_Percent" 14 "_70_Percent" 15 "_75_Percent" 16 "_80_Percent" 17 "_85_Percent" 18 "_90_Percent" 19 "_95_Percent" 20 "_100_Percent" 31 "Invalid_Value" ;
VAL_ 283 IdleSpdSetPointReq 0 "vaild_Value" 2046 "Init" 2047 "Invalid" ;
VAL_ 283 AccrPedlAntiMsstpngSts 0 "Initial_Value" 1 "Not_Active" 2 "Active" 3 "Limited_Function" ;
VAL_ 283 IOTACoolingResp 0 "No_Response" 1 "Response" 2 "Reserved" ;
VAL_ 283 VCU_MaxSpdLimit 0 "Valid_Value" 3001 "Invalid" ;
VAL_ 283 RollingCounter_VCU26 0 "Valid_Value" 15 "Invalid_Value" ;
VAL_ 283 DrvTrqReqOvld 0 "No_Driver_Override" 1 "Driver_Override" 2 "Reserved" 3 "Invalid_Value" ;
VAL_ 283 ActTotWheelTrq 0 "Vaild_Value" 8191 "Invalid" ;
VAL_ 283 VCU_DrvReqTqWhl 0 "Vaild_Value" 4095 "Invalid" ;
VAL_ 283 MaxPsblPosWheelTrq 0 "Vaild_Value" 4095 "Invalid" ;
VAL_ 283 MinPsblNegWheelTrq 0 "Vaild_Value" 4095 "Invalid" ;
VAL_ 283 Checksum_VCU26 0 "Valid_Values" ;
VAL_ 283 RollingCounter_VCU21 0 "Valid_Value" 15 "Invalid_Value" ;
VAL_ 283 DrvgPrkgTrqRespFlg 0 "Initial_Value" 1 "Not_Response" 2 "Responsed" ;
VAL_ 283 DrvgPrkgTrqAvailSts 0 "Initial_Value" 1 "Not_Available" 2 "Available" 3 "Available_Degraded" ;
VAL_ 283 DrvTrqReqOvrdvld 0 "Invalid" 1 "Valid" ;
VAL_ 283 FMCUIdleSts 0 "Initial_value" 1 "No_Idle" 2 "Idle" ;
VAL_ 283 Checksum_VCU21 0 "Valid_Values" ;
VAL_ 283 RollingCounter_VCU12 0 "Valid_Value" 15 "Invalid_Value" ;
VAL_ 283 PTDrvMod 0 "Default value" 1 "EV-FWD（纯电前驱）" 2 "EV-AWD（纯电四驱）" 3 "EV-RWD （纯电后驱）" 4 "HEV-FWD（并联前驱）" 5 "HEV-AWD（并联四驱）" 6 "Power Split (功率分流）" 7 "Power Split-AWD(功率分流四驱）" ;
VAL_ 283 DrvMod 0 "Normal_mode_started" 1 "EV_mode_started" 2 "Save_mode_started" 3 "SPORT_mode_started" 4 "AWD_normal_mode_started" 5 "Snow_mode_started" 6 "Muddy_mode_started" 7 "Sand_mode_started" 8 "ECO_mode" 9 "SPORT_plus_mode_started" 10 "OPD_mode" 11 "Auto_mode" 12 "ECOPlus_mode" 13 "Individuation_mode" 14 "Lady_mode" 15 "Wet_mode" 16 "Track_mode" 17 "Hybrid_mode" 18 "Trailer_mode" 19 "Z_mode" ;
VAL_ 283 VCU_ACCComIf 0 "No_Response" 1 "Response" ;
VAL_ 283 ActDrvMod 0 "Normal_Mode" 1 "Sport_Mode" 2 "ECO_Mode" 3 "OPD_Mode" 4 "ECOplus_Mode" 5 "Snow_Mode" 6 "Reserved" 7 "Reserved" 8 "Mud_Mode" 9 "Sand_Mode" 10 "Sportplus_Mode" 11 "Lady" 12 "Reserved" ;
VAL_ 283 Checksum_VCU12 0 "Valid_Values" ;
VAL_ 295 AutoLmpSwtSts_HUT 0 "Non-Auto" 1 "Auto" ;
VAL_ 295 LowBeamSwtSts_HUT 0 "OFF" 1 "ON" ;
VAL_ 295 RearFogLmpSwtSts_HUT 0 "OFF" 1 "ON" ;
VAL_ 302 RollingCounter_IBC_FD1_5 0 "Valid value" 15 "Invalid value" ;
VAL_ 302 APCFailrSts 0 "no error" 1 "APC1(APA) driver not present（预留）" 2 "APC124 too high slope" 3 "too high speed" 4 "Unexpected_EPB Apply" 5 "Unexpected_Gear Intervention" 6 "Vehicle Block" 7 "Error" ;
VAL_ 302 BrkgOvrdVld 0 "Invalid" 1 "Valid" ;
VAL_ 302 MEBavailability 0 "NotAvailable" 1 "Available" ;
VAL_ 302 APCSts 0 "Standby" 1 "Active_APA" 2 "Active_RPA" 3 "Active_AVP" 4 "Active_MEB" 5 "Reserved" ;
VAL_ 302 RPAavailability 0 "NotAvailable" 1 "Available" 2 "TestPending" 3 "Reserved" ;
VAL_ 302 APAavailability 0 "NotAvailable" 1 "Available" ;
VAL_ 302 CddApActvVehHld 0 "Flase" 1 "True" ;
VAL_ 302 AVPavailability 0 "NotAvailable" 1 "Available" 2 "TestPending" 3 "Reserved" ;
VAL_ 302 DrvBrkOvrdFlg 0 "Flase" 1 "True" 2 "Reserved" ;
VAL_ 302 Checksum_IBC_FD1_5 0 "Valid values" ;
VAL_ 302 HydBrkgActTrq 0 "Initial_value" ;
VAL_ 302 HydBrkgTrqReq 0 "Initial_value" ;
VAL_ 302 DrvBrkgTrqReq 0 "Initial_value" ;
VAL_ 302 RollingCounter_IBC_FD1_2 0 "Valid value" 15 "Invalid value" ;
VAL_ 302 BrkHldActvSts 0 "Initial_value" 1 "Not_active" 2 "Active" ;
VAL_ 302 BrkHldAvailSts 0 "Initial_value" 1 "Not_available" 2 "Available" ;
VAL_ 302 BrkgTrqModResp 0 "Initial_value" 1 "NotActive" 2 "APA_Active" 3 "ACC_Active" ;
VAL_ 302 PrkgBrkgTrqAvailSts 0 "Initial_value" 1 "Not_available" 2 "Available" 3 "Degraded1" 4 "Degraded2" 5 "Overspeed" ;
VAL_ 302 DrvgBrkgTrqAvailSts 0 "Initial_value" 1 "Not_available" 2 "Available" 3 "Degraded1" 4 "Degraded2" ;
VAL_ 302 Checksum_IBC_FD1_2 0 "Valid value" ;
VAL_ 302 RollingCounter_IBC_FD1_1 0 "Valid value" 15 "Invalid value" ;
VAL_ 302 CST_Status 0 "CST_is_disabled" 1 "CST_is_Standby" 2 "CST_is_Active" 3 "CST_is_Failure" ;
VAL_ 302 PushrodStauts 0 "Not_Pressed_Init_Default" 1 "Pressed" 3 "Error" ;
VAL_ 302 BrkFldWarn 0 "BrakeFluid_Normal_or_Init_or_Default" 1 "BrakeFluid_Empty" 2 "BrakeFluid_Electric_Error" ;
VAL_ 302 InpRodStk 0 "Valid" ;
VAL_ 302 InpRodStkSts 0 "Valid" 1 "Invalid" ;
VAL_ 302 FWA_Warn 0 "No_failure_Init_Default" 1 "Warnig_level_1_for_high_Temp_of_Brake_system" 2 "Warnig_level_2_for_high_Temp_of_Brake_system" ;
VAL_ 302 PlungerPressSts 0 "Valid" 1 "Invalid" ;
VAL_ 302 PlungerPress 0 "Valid" 1024 "Reserved" ;
VAL_ 302 IBCSysSts 0 "BBF_FullSys_Init_Default" 1 "BBF_DegradedPedalFeel" 2 "BBF_CircuitSperation" 3 "BBF_C1_2BoostOnly" 4 "HydBack_W_Act_HydBack_W_O_Act" ;
VAL_ 302 SimtorPressSts 0 "Valid" 1 "Invalid" ;
VAL_ 302 SimtorPress 0 "Valid_values" ;
VAL_ 302 Checksum_IBC_FD1_1 0 "Valid values" ;
VAL_ 311 RWSAngMinLimn 0 "Valid_Value" 1001 "Reserved" 1023 "Initial_Value" ;
VAL_ 311 RWSAngMaxLimn 0 "Valid_Value" 1001 "Reserved" 1023 "Initial_Value" ;
VAL_ 311 RollingCounter_ABS3 0 "Valid value" 15 "Invalid value" ;
VAL_ 311 VehOdoInfo 0 "Valid_values" ;
VAL_ 311 VehOdoInfoSts 0 "Invalid" 1 "Valid" ;
VAL_ 311 ABSActv 0 "Not active" 1 "Active" ;
VAL_ 311 ESP_MILSts 0 "The_Warning_Mil_light_is_off" 1 "The_Warning_Mil_light_is_on" ;
VAL_ 311 EBDActv 0 "Not active" 1 "Active" ;
VAL_ 311 VehSpd 0 "Valid values" 5334 "Reserved" ;
VAL_ 311 VehSpdVld 0 "Invalid" 1 "Valid" ;
VAL_ 311 EBDFailSts 0 "No failure" 1 "Failure" ;
VAL_ 311 ABSFailSts 0 "No failure" 1 "Failure" ;
VAL_ 311 Checksum_ABS3 0 "Valid values" ;
VAL_ 311 RollingCounter_ESP4 0 "Valid_value" 15 "Invalid_value" ;
VAL_ 311 EBDfailsts_RM 0 "No_failure" 1 "Failure" 2 "Diagnostic" ;
VAL_ 311 DrvTrqIncReqActv_FA 0 "Not active" 1 "Active" ;
VAL_ 311 DrvTrqRedReqActv_FA 0 "Not active" 1 "Active" ;
VAL_ 311 DrvTrqRedSlowReq_FA 0 "Valid_values" ;
VAL_ 311 DrvTrqIncReq_FA 0 "Valid value" 8001 "Reserved" ;
VAL_ 311 Checksum_ESP4 0 "Valid_value" ;
VAL_ 311 RollingCounter_ESP7 0 "Valid value" 15 "Invalid value" ;
VAL_ 311 ESP_APS_GearBoxEna 0 "No_Request" 1 "Request" ;
VAL_ 311 ESP_APS_TgtGear 0 "Idle" 1 "P" 2 "R" 3 "N" 4 "D" ;
VAL_ 311 APS_EngTrqReqEna 0 "No demand" 1 "Valid values torque demand" ;
VAL_ 311 EngTrqReq 0 "Valid value" 32768 "Reserved" ;
VAL_ 311 LgtCtrlrFailr 0 "No Error" 1 "Vehicle_Blocked" 2 "Unexpected_GearPosition" 3 "Unexpected_EPB_Action" 4 "Reserved" 5 "Unexpected_GearIntervention" 6 "Active Braking failure" 7 "Invalid values" ;
VAL_ 311 LgtCtrlrSts 0 "Off" 1 "Standby" 2 "Reserved" 3 "Reserved" 4 "Active_AutomaticPark" 5 "Reserved" 6 "Reserved" 7 "Invalid_value" ;
VAL_ 311 ESP_MEBBrkAvail 0 "Not_Available" 1 "Available" ;
VAL_ 311 FourWhlsBrkTrq 0 "Valid values value" ;
VAL_ 311 Checksum_ESP7 0 "Valid values" ;
VAL_ 311 RollingCounter_ESP1 0 "Valid value" 15 "Invalid value" ;
VAL_ 311 TrqMaxLim 0 "Valid_values" 4095 "Invalid" ;
VAL_ 311 ClutOpenReq 0 "Passive" 1 "Fast_open" 2 "Torque_max_limit" 3 "Error" ;
VAL_ 311 MSRActv_RA 0 "Inactive" 1 "Active" ;
VAL_ 311 IMC_Actv 0 "Not_active" 1 "Active" ;
VAL_ 311 ESP_MasterCylBrkPress 0 "Valid value" 14961 "Reserved" ;
VAL_ 311 ESP_MasterCylBrkPressVld 0 "Invalid" 1 "Valid" ;
VAL_ 311 GearShftInhibitReq_FA 0 "Not_active" 1 "Active" ;
VAL_ 311 VDCActv 0 "Not active" 1 "Active" ;
VAL_ 311 MSRActv 0 "Not active" 1 "Active" ;
VAL_ 311 PTCActv 0 "Not active" 1 "Active" ;
VAL_ 311 BTCActv 0 "Not active" 1 "Active" ;
VAL_ 311 PTCActv_RA 0 "Inactive" 1 "Active" ;
VAL_ 311 BTCActv_RA 0 "Inactive" 1 "Active" ;
VAL_ 311 ESPFuncOffSts 0 "Available/On" 1 "Unavailable/Off" ;
VAL_ 311 ESPActvInfoLmp 0 "Not_Active" 1 "Active" ;
VAL_ 311 ESPBrkLmpCtrl 0 "Brake light off" 1 "Brake light on" ;
VAL_ 311 ESPFailSts 0 "No failure" 1 "Failure" ;
VAL_ 311 Checksum_ESP1 0 "Valid values" ;
VAL_ 311 RollingCounter_ESP2 0 "Valid value" 15 "Invalid value" ;
VAL_ 311 SysOperatingMod_ESP 0 "ESP_OFF" 1 "Normal" 2 "Snow" 3 "Mud" 4 "Sand" 5 "Sport" ;
VAL_ 311 TAB_Sts 0 "Function_OFF" 1 "Standby" 2 "Active" 3 "Failure" ;
VAL_ 311 Shift_N_Warn 0 "Shift_N" 1 "No_shift_N" ;
VAL_ 311 DrivingModDis 0 "Standard" 1 "Sport" 2 "Snow" 3 "Mud" 4 "Sand" 5 "_4L" 6 "Economic" 7 "Mode_Unkown" 8 "Auto" 9 "Sport_Up" 10 "Off_Road" 11 "Standard_2H" 12 "Expert" 13 "Standard_4H" 14 "Failed" 15 "Invalid_Value" 16 "Snow_4H" 17 "Normal_4L" 18 "Rock_4L" 19 "Pothle_4L" 20 "Mud_Or_Sand_4L" 21 "Mountain_4L" 22 "Turbo" 23 "Race" 24 "Grass_Gravel" 26 "Wade_4H" 27 "Wade_4L" 28 "_2H" 29 "_4H" 30 "Noviciate" ;
VAL_ 311 FOURLModShift_Flg 0 "Allow" 1 "Not_allow" ;
VAL_ 311 FOURL_Warn 0 "No_warn" 1 "Warn" ;
VAL_ 311 Over_Spd_Warn 0 "No_warn" 1 "Warn" ;
VAL_ 311 DrivingModReq_ESP 0 "No_Terrain_Control" 1 "Standard" 2 "Sport" 3 "Snow_Nex" 4 "Expert" 5 "Deep_Mud" 6 "2H" 7 "Soft_sand" 8 "4H" 9 "4L" 10 "Economic" 11 "Snow_ESOF" 12 "Snow_TOD" 13 "Off_road" 14 "Sport+" 15 "Invalid_Value" 16 "Stand_2H" 17 "Noviciate" 18 "Stand_4H" 19 "Snow_4H" 20 "Normal_4L" 21 "Rock_4L" 22 "Pothole_4L" 23 "Mud/Sand_4L" 24 "Mountain_4L" 25 "Turbo" 26 "Race" 27 "Grass/Gravel" 28 "Uneven_Nex" 29 "Wade_4H" 30 "Wade_4L" 31 "Climb_4L" ;
VAL_ 311 SS_func_off 0 "allow_start_stop" 1 "forbid_start_stop" ;
VAL_ 311 AVHErrSts 0 "No failure" 1 "Failure when AVH is on need" 2 "Failure when is not on need" 3 "Reserved" ;
VAL_ 311 AVHSts 0 "Off" 1 "Standby" 2 "active" 3 "Reserved" ;
VAL_ 311 CDPVld 0 "Invalid_values" 1 "Valid_values" ;
VAL_ 311 CDPActv 0 "Not active" 1 "Active" ;
VAL_ 311 HDCFault 0 "No_Failure" 1 "Failure_When_HDC_Is_On_Need" 2 "Failure_When_Is_Not_On_Need" ;
VAL_ 311 HDCCtrl 0 "OFF" 1 "On active braking" 2 "On not active braking" 3 "Reserved" ;
VAL_ 311 CDDActv 0 "Not active" 1 "Active" ;
VAL_ 311 CDDAvailable 0 "Not available" 1 "Available" ;
VAL_ 311 AWBAvailable 0 "Unusable" 1 "Usable" ;
VAL_ 311 AWBActv 0 "Not active" 1 "Active" ;
VAL_ 311 HHCSts 0 "Not active" 1 "Active" ;
VAL_ 311 AEBIBActv 0 "Not active" 1 "Active" ;
VAL_ 311 AEBBAActv 0 "Not active" 1 "Active" ;
VAL_ 311 AEBAvailable 0 "Unusable" 1 "Usable" ;
VAL_ 311 ABPAvailable 0 "Unusable" 1 "Usable" ;
VAL_ 311 ABPActv 0 "Not active" 1 "Active" ;
VAL_ 311 ABAavailable 0 "Unusable" 1 "Usable" ;
VAL_ 311 ABAActv 0 "Not active" 1 "Active" ;
VAL_ 311 SCMActv 0 "Not_Active" 1 "Active" ;
VAL_ 311 ESP_DiagActv 0 "ESP diagnosis is inactive" 1 "ESP diagnosis is active" ;
VAL_ 311 CTABrkAvailable 0 "Not Available" 1 "Available" ;
VAL_ 311 BrkDskOvrheatd 0 "Not high" 1 "Temp too high" ;
VAL_ 311 NoBrkForce 0 "EXist brake force" 1 "No brake force" ;
VAL_ 311 VehStandstill 0 "Not standstill" 1 "Standstill" 2 "Invalid (short unavailability, maX 3s)" 3 "Reserved" ;
VAL_ 311 SwtOffCrsCtrl 0 "Not_switch_off_cruise_control" 1 "Switch_off_cruise_control" ;
VAL_ 311 Checksum_ESP2 0 "Valid values" ;
VAL_ 311 RWSAngLimnSts 0 "No_Limit" 1 "Limiting_Rear_Steering_Angle" 2 "Reserved" ;
VAL_ 311 RWSAngLimnVld 0 "Invalid_value" 1 "Valid_value" ;
VAL_ 315 RollingCounter_ABS2 0 "Valid value" 15 "Invalid value" ;
VAL_ 315 WssRREdgesSumVld 0 "Invalid" 1 "Valid" ;
VAL_ 315 WssRLEdgesSumVld 0 "Invalid" 1 "Valid" ;
VAL_ 315 WssRLEdgesSum 0 "Valid Values" ;
VAL_ 315 WssRREdgesSum 0 "Valid Values" ;
VAL_ 315 RRWheelSpd 0 "Valid values" 5334 "Reserved" ;
VAL_ 315 RRWheelSpdVld 0 "Invalid" 1 "Valid" ;
VAL_ 315 RRWheelDriveDirection 0 "Invalid" 1 "Forward" 2 "Backward" 3 "Stop" ;
VAL_ 315 RLWheelSpd 0 "Valid values" 5334 "Reserved" ;
VAL_ 315 RLWheelSpdVld 0 "Invalid" 1 "Valid" ;
VAL_ 315 RLWheelDriveDirection 0 "Invalid" 1 "Forward" 2 "Backward" 3 "Stop" ;
VAL_ 315 Checksum_ABS2 0 "Valid values" ;
VAL_ 315 RollingCounter_ESP9 0 "Valid_values" 15 "Invalid_value" ;
VAL_ 315 IBC_RwsAngReq 0 "Valid_values" 4095 "Initial_value" ;
VAL_ 315 WheelSpdSnsr_GenDir 0 "Not_Error" 1 "Error" ;
VAL_ 315 WheelSpdSnsrGeneralErr 0 "Not_Error" 1 "Error" ;
VAL_ 315 RRWheelSpdSnsr_Dir 0 "Not_Error" 1 "Error" ;
VAL_ 315 RRWheelSpdSnsr_UnderLineFail 0 "Not_Error" 1 "Error" ;
VAL_ 315 RRWheelSpdSnsr_MultiSigFail 0 "Not_Error" 1 "Error" ;
VAL_ 315 RRWheelSpdSnsr_Open 0 "Not_Error" 1 "Error" ;
VAL_ 315 RRWheelSpdSnsr_ShortUBAT 0 "Not_Error" 1 "Error" ;
VAL_ 315 RRWheelSpdSnsr_GND 0 "Not_Error" 1 "Error" ;
VAL_ 315 RLWheelSpdSnsr_Dir 0 "Not_Error" 1 "Error" ;
VAL_ 315 RLWheelSpdSnsr_UnderLineFail 0 "Not_Error" 1 "Error" ;
VAL_ 315 RLWheelSpdSnsr_MultiSigFail 0 "Not_Error" 1 "Error" ;
VAL_ 315 RLWheelSpdSnsr_Open 0 "Not_Error" 1 "Error" ;
VAL_ 315 RLWheelSpdSnsr_ShortUBAT 0 "Not_Error" 1 "Error" ;
VAL_ 315 RLWheelSpdSnsr_GND 0 "Not_Error" 1 "Error" ;
VAL_ 315 FRWheelSpdSnsr_Dir 0 "Not_Error" 1 "Error" ;
VAL_ 315 FRWheelSpdSnsr_UnderLineFail 0 "Not_Error" 1 "Error" ;
VAL_ 315 FRWheelSpdSnsr_MultiSigFail 0 "Not_Error" 1 "Error" ;
VAL_ 315 FRWheelSpdSnsr_Open 0 "Not_Error" 1 "Error" ;
VAL_ 315 FRWheelSpdSnsr_ShortUBAT 0 "Not_Error" 1 "Error" ;
VAL_ 315 FRWheelSpdSnsr_GND 0 "Not_Error" 1 "Error" ;
VAL_ 315 FLWheelSpdSnsr_Dir 0 "Not_Error" 1 "Error" ;
VAL_ 315 FLWheelSpdSnsr_UnderLineFail 0 "Not_Error" 1 "Error" ;
VAL_ 315 FLWheelSpdSnsr_MultiSigFail 0 "Not_Error" 1 "Error" ;
VAL_ 315 FLWheelSpdSnsr_Open 0 "Not_Error" 1 "Error" ;
VAL_ 315 FLWheelSpdSnsr_ShortUBAT 0 "Not_Error" 1 "Error" ;
VAL_ 315 FLWheelSpdSnsr_GND 0 "Not_Error" 1 "Error" ;
VAL_ 315 RollingCounter_ESP13 0 "Valid_values" 15 "Invalid_value" ;
VAL_ 315 IBC_RwsCtrlMod 0 "Initial_value" 1 "Not_control" 2 "normal_control" 3 "special_control" ;
VAL_ 315 DrvTrqIncReqActv_RA 0 "Not active" 1 "Active" ;
VAL_ 315 DrvTrqRedReqActv_RA 0 "Not active" 1 "Active" ;
VAL_ 315 MSRVld 0 "Unusable" 1 "Usable" ;
VAL_ 315 GearShftInhibitReq_RA 0 "No_request_Inactive" 1 "Request_Active" ;
VAL_ 315 DrvTrqRedReq_RA 0 "Valid  value" 20476 "Reserved" ;
VAL_ 315 DrvTrqIncReq_RA 0 "Valid  value" 20476 "Reserved" ;
VAL_ 315 RollingCounter_ESP8 0 "Valid_values" 15 "Invalid_value" ;
VAL_ 315 BumpSts 0 "Inactive" 1 "Active" ;
VAL_ 315 DrivingModShiftLimn 0 "No_limit" 1 "High_speed_not_allow" ;
VAL_ 315 CCO_TrqReq 0 "Valid_values" ;
VAL_ 315 CCO_TgtVel 0 "Valid_values" ;
VAL_ 315 HBASts 0 "Not_active" 1 "Active" ;
VAL_ 315 CCO_Warn 0 "No_Warn" 1 "Please_Release_EPB" 2 "Please_slow_down" 3 "Plesase_enter_4H_4L" ;
VAL_ 315 EspFuncOffSts_mode 0 "Available_On" 1 "Cross_country_expert_mode" ;
VAL_ 315 CCO_Active 0 "Not_Active" 1 "Active" 2 "Stand_by" 3 "Failed" ;
VAL_ 315 DrivingModShiftLimnDisp 0 "No_Warn" 1 "High_Spd_Swiching_Limit" ;
VAL_ 315 SSASts 0 "Initial_Value" 1 "Not_active" 2 "Active" 3 "Failure" 4 "Limitation" 5 "Ramp_off" ;
VAL_ 315 RollingCounter_EPB1 0 "Valid value" 15 "Invalid value" ;
VAL_ 315 ESP_DSTSts 0 "Not active" 1 "Active" 2 "Not available" 3 "Reserved" ;
VAL_ 315 ESP_DSTTrqReqDir 0 "Positive_Left" 1 "Negative_Right" ;
VAL_ 315 ESP_DSTTrqReq 0 "Valid_values" 1023 "Invalid_value" ;
VAL_ 315 EPBTextDisp 0 "No_Display" 1 "Gradient_Too_High" 2 "Park_Brake_Force_Not_Enough" 3 "Park_Brake_System_Overheated" 4 "Remind_Driver_To_Apply_Safety_Belt" 5 "Park_Brake_Maintenance_Mode" 6 "Roller_Bench_Mode" 7 "Please_Release_EPB" 8 "Please_Release_Rear_ELD" 9 "Switch_To_Non_P_and_Release_The_Parking" 10 "Please_Quit_TAB" 11 "Freestanding_EPB_Controller_with_Limited_Control" 12 "Please_enter_4H_4L" 13 "Please_switch_to_off_rpad_modes_such_as_mud_sand_and_4L" ;
VAL_ 315 EPBRedLmpSts 0 "Lamp off" 1 "Lamp on" 2 "Lamp flash" 3 "Reserved" ;
VAL_ 315 EPBErrSts 0 "Undefined" 1 "No Error" 2 "Error" 3 "Diagnosis" ;
VAL_ 315 EPBSts 0 "Released" 1 "Closed" 2 "In progress" 3 "unknown" ;
VAL_ 315 EPB_SwtPosn 0 "Neutral" 1 "Release" 2 "Apply" 3 "Reserved" ;
VAL_ 315 EPB_SwtPosnVld 0 "Invalid" 1 "Valid" ;
VAL_ 315 PressBrakePedalPointOut 0 "No_reminder" 1 "Pedal_needs_to_be_applied" ;
VAL_ 315 EPB_VirtSwtAvailable 0 "Not_available" 1 "available" ;
VAL_ 315 Checksum_EPB1 0 "Valid values" ;
VAL_ 315 RollingCounter_ABS1 0 "Valid value" 15 "Invalid value" ;
VAL_ 315 WssFREdgesSumVld 0 "Invalid" 1 "Valid" ;
VAL_ 315 WssFLEdgesSumVld 0 "Invalid" 1 "Valid" ;
VAL_ 315 WssFREdgesSum 0 "Valid Values" ;
VAL_ 315 WssFLEdgesSum 0 "Valid Values" ;
VAL_ 315 FRWheelSpd 0 "Valid values" 5334 "Reserved" ;
VAL_ 315 FRWheelSpdVld 0 "Invalid" 1 "Valid" ;
VAL_ 315 FRWheelDriveDirection 0 "Invalid" 1 "Forward" 2 "Backward" 3 "Stop" ;
VAL_ 315 FLWheelSpd 0 "Valid values" 5334 "Reserved" ;
VAL_ 315 FLWheelSpdVld 0 "Invalid" 1 "Valid" ;
VAL_ 315 FLWheelDriveDirection 0 "Invalid" 1 "Forward" 2 "Backward" 3 "Stop" ;
VAL_ 315 Checksum_ABS1 0 "Valid values" ;
VAL_ 327 RollingCounter_EPS3 0 "Valid_value" 15 "Invalid_value" ;
VAL_ 327 EPS_HADHndShkRespSt 0 "Off" 1 "Reserved" 2 "Reserved" 3 "Reserved" 4 "HWP Active" 5 "Failure" 6 "Reserved" ;
VAL_ 327 EPS_AngCmdOverRange 0 "Not over ange" 1 "Over ange" ;
VAL_ 327 EPS_AvailStsforHAD 0 "Not available" 1 "Available degraded" 2 "Available" 3 "Reserved" ;
VAL_ 327 EPS_SteerWheelAngVld 0 "Invalid_value" 1 "Valid_value" ;
VAL_ 327 EPS_HADerror_Reason 0 "No_Error" 1 "IDC_L3_Request_Is_Invalid_" 2 "IDC_L3_Communication_Error" 3 "IDC_L3_Fault" 4 "EPS_Internal_Error_Detected_" 5 "Under_Voltage_Detected_" 6 "Over_Voltage_Detected_" 7 "ADS_Requested_Steering_Angle_Is_Above_The_Limit" 8 "Change_Rate_Of_ADS_Requested_Steering_Angle_Is_Above_The_Limit_" 9 "Vehicle_Speed_Wheel_Speed_Error" 10 "IDC_L2_Error" 11 "TAS_Sensor_Error" 12 "Reserved" ;
VAL_ 327 EPS_SteerWheelSpdSign 0 "Left_Positive" 1 "Right_Negative" ;
VAL_ 327 EPS_SteerWheelSpd 0 "Valid_value" 10161 "Reserved" 32767 "Invalid_value" ;
VAL_ 327 EPS_SteerWheelAngSign 0 "Left_Positive" 1 "Right_Negative" ;
VAL_ 327 EPS_SteerWheelAng 0 "Valid_value" 7801 "Reserved" 32767 "Invalid_value" ;
VAL_ 327 Checksum_EPS3 0 "Valid_value" ;
VAL_ 327 RollingCounter_EPS2 0 "Valid value" 15 "Invalid value" ;
VAL_ 327 EPS_LKATrqOvlDlvdSts 0 "Not active" 1 "Active" 2 "Temporary inhibit" 3 "Permanently failed" ;
VAL_ 327 EPS_DrvInpTrqVal_HighResVld 0 "Invalid" 1 "Valid" ;
VAL_ 327 EPS_LKATorqOvrlDlvdVld 0 "Invalid" 1 "Valid" ;
VAL_ 327 EPS_LKATorqOvrlDlvd 0 "Valid value" 3001 "Reserved" ;
VAL_ 327 EPS_LKAAngDlvdSts 0 "Not active" 1 "Active" 2 "Temporary inhibit" 3 "Permanently failed" ;
VAL_ 327 EPS_DrvInpTrqVal_HighReslolution 0 "Valid Values" ;
VAL_ 327 Checksum_EPS2 0 "Valid values" ;
VAL_ 327 RollingCounter_EPS1 0 "Valid value" 15 "Invalid value" ;
VAL_ 327 EPS_SteerMod 0 "Comfort Mode" 1 "sport mode" 2 "Handiness Mode" 3 "Reserved" ;
VAL_ 327 SteerSysFltTyp 0 "Initial_value" 1 "Adas_AngReqLimit_Exceed" 2 "Adas_AngSpdReqLimit_Exceed" 3 "Adas_TrqReqLimit_Exceed" 4 "Adas_TrqSpdReqLimit_Exceed" 5 "Adas_Msg_Invalid" 6 "Adas_VehSpdLimit_Exceed" 7 "Steer_Sys_Failure" 8 "Steer_override" 9 "Steer_Tgt_LimitExceed" ;
VAL_ 327 EPS_AvailSts 0 "Temporary inhibit" 1 "Available for control" 2 "Active" 3 "Permanently failed" ;
VAL_ 327 EPS_InterferDetdVld 0 "Invalid" 1 "Valid" ;
VAL_ 327 EPS_InterferDetd 0 "No Interference" 1 "Interference" ;
VAL_ 327 EPS_DSTCtrlSts 0 "Permanently fail" 1 "Temporary inhibit" 2 "Available for control" 3 "Active" 4 "Reserved" ;
VAL_ 327 EPS_FailSts 0 "No fault" 1 "Permanent Error Detected" 2 "Intermittent Error Detected" 3 "Reserved" ;
VAL_ 327 EPS_TrqSnsrSts 0 "Normal" 1 "Abnormal" ;
VAL_ 327 Checksum_EPS1 0 "Valid values" ;
VAL_ 338 RearELDLckSts 0 "UnLocked" 1 "Locked" 2 "Over-Speed Warning" 3 "Driving Mode Select Error" 4 "Lock Request Deny" 5 "Reserved" 14 "Fault" 15 "Invalid" ;
VAL_ 357 TurnLmpSwtErrSts 0 "No Error" 1 "Error" ;
VAL_ 357 LowBeamSwtSts 0 "OFF" 1 "ON" ;
VAL_ 357 HiBeamSwtSts 0 "OFF" 1 "ON" ;
VAL_ 357 OverVehBeamSwtSts 0 "OFF" 1 "ON" ;
VAL_ 357 AutoLmpSwtSts 0 "Non-Auto" 1 "Auto" ;
VAL_ 357 RLSSensitivityReq 0 "Sensitivity_1_R_0_Ohm_Slow" 1 "Sensitivity_2_R_220_Ohm" 2 "Sensitivity_3_R_650_Ohm" 3 "Sensitivity_4_R_1210_Ohm" 4 "Sensitivity_5_R_1830_Ohm" 5 "Sensitivity_6_R_2580_Ohm_Fast" ;
VAL_ 357 LTurnLmpSwtSts 0 "OFF" 1 "ON" ;
VAL_ 357 RTurnLmpSwtSts 0 "OFF" 1 "ON" ;
VAL_ 357 FrntFogLmpSwtSts 0 "OFF" 1 "ON" ;
VAL_ 357 FrntWiprSwtSts 0 "Wiper Off" 1 "Wiper Auto Or Intermittent" 2 "Low Speed" 3 "High Speed" 4 "reserved" 7 "Error" ;
VAL_ 357 FrntWshrSwtSts 0 "OFF" 1 "Wiper Wash" 2 "Wash in Auto Mode" 3 "Reserved" ;
VAL_ 388 RollingCounter_VCU_FD28_2 15 "Invalid_value" ;
VAL_ 388 RRIntgrtdWheelSpd 0 "Initial_value" ;
VAL_ 388 RLIntgrtdWheelSpd 0 "Initial_value" ;
VAL_ 388 RollingCounter_VCU_FD28_1 15 "Invalid_value" ;
VAL_ 388 EstimrResutReliabt 0 "Initial_valid" 1 "Trusted" 2 "UnTrusted" ;
VAL_ 388 EstimdRoadFricCoeff 0 "Initial_value" ;
VAL_ 388 FRIntgrtdWheelSpd 0 "Initial_value" ;
VAL_ 388 FLIntgrtdWheelSpd 0 "Initial_value" ;
VAL_ 388 IntgrtdVehSpd 0 "Initial_value" ;
VAL_ 474 OneclickClsIntellgntDrvgReq 0 "Initial_value" 1 "OFF" 2 "ON" ;
VAL_ 474 OutdPrkgReq 0 "No_action" 1 "Request" ;
VAL_ 474 CamFolwSwtReq 0 "No_Request" 1 "Request_to_Change" ;
VAL_ 474 PrkModReq 0 "No_Action" 1 "Head_parking_in" 2 "Tail_parking_in" 3 "Reserved" ;
VAL_ 474 TJA_ASCruise 0 "No_action" 1 "OFF" 2 "ON" 3 "Reserved" ;
VAL_ 474 RCTA_DispSwtReq 0 "No_Request" 1 "Request_to_Change" ;
VAL_ 474 AutoPrkOutSwtReq 0 "No_Request" 1 "Request_to_Change" ;
VAL_ 474 PrkgSlotId 0 "No_action" 1 "Valid_value" ;
VAL_ 474 HAVP_UseMod 0 "No_action" 1 "Use_on_car" 2 "Use_on_mobile" 3 "Reserved" ;
VAL_ 474 HUT_HAVP_APA_Permit 0 "Idle" 1 "NO" 2 "YES" 3 "Reserved" ;
VAL_ 474 UserDefinedParkCmd 0 "No Request" 1 "Request" ;
VAL_ 474 SlotNum_VR 0 "Invalid" 1 "Select_1_15_carport" ;
VAL_ 474 UserDefPrkMenuSelCmd 0 "No_Request" 1 "Parallel_Slot_Selected" 2 "Vertical_Slot_Selected" 3 "Request_Back_APA" 4 "Slot_adsorption_request" 5 "Clock_wise_Selected" 6 "Anticlock_wise_Selected" ;
VAL_ 474 HUT_HAVP_Set_Path_Ending 0 "No request" 1 "Request" ;
VAL_ 474 HUT_HAVP_Comfirm_Btn 0 "No Request" 1 "Request" ;
VAL_ 474 HUT_HAVP_SelfParLot_Ending 0 "No Request" 1 "Request" ;
VAL_ 474 HUT_HAVP_Set_Starting 0 "No Request" 1 "Request" ;
VAL_ 474 BackReq_RPA 0 "No_request" 1 "Request" ;
VAL_ 474 SteerWheelsilentReq 0 "No_action" 1 "OFF" 2 "ON" ;
VAL_ 489 BackReq_AVM 0 "No request" 1 "Request" ;
VAL_ 490 RmtPrkRadShieldSet 0 "No_action" 1 "OFF" 2 "Shielded_bilateral_radar" 3 "Shield_all_radars" ;
VAL_ 493 TraOvlSwtCmd 0 "No_Request" 1 "Request" ;
VAL_ 493 StartPrkgPath2Cmd 0 "No request" 1 "Request" ;
VAL_ 493 DeletePath2Cmd 0 "No request" 1 "Request" ;
VAL_ 493 StartPrkgPath1Cmd 0 "No request" 1 "Request" ;
VAL_ 493 DeletePath1Cmd 0 "No request" 1 "Request" ;
VAL_ 493 SelPrkgFctnCmd 0 "No selection" 1 "Select APA parking" 2 "Select P2P parking" 3 "Select Explore Forward" 4 "Select drive back" 5 "Select HAVP Parking" 6 "Select PAVP Parking" 7 "Reserved" ;
VAL_ 493 P2P_PrkgDirectSwtCmd 0 "No Request" 1 "Request" ;
VAL_ 493 PathLrngFinshCmd 0 "No request" 1 "Request" ;
VAL_ 493 PathLrngStartCmd 0 "No request" 1 "Request" ;
VAL_ 493 ParkMdlCmd 0 "No request" 1 "Request" ;
VAL_ 493 BackReq_APS 0 "No request" 1 "Request" ;
VAL_ 493 SelPrkOutDirReq 0 "No selection" 1 "Park out front/vertical head out" 2 "Park out rear/vertical tail out" 3 "Park out left/parallel left out" 4 "Park out right/parallel right out" 5 "Park_out_left_vertical_left_out" 6 "Park_out_right_vertical_right_out" 7 "Reserved" ;
VAL_ 493 PrkInDirChoice 0 "None" 1 "Tail in" 2 "Head in" 3 "Reserved" ;
VAL_ 494 APSSwtReq_VR 0 "No action" 1 "off" 2 "on" 3 "Reserved" ;
VAL_ 494 APSPrkgTypSeln 0 "No Select" 1 "Select parallel parking" 2 "Select vertical parking" 3 "Reserved" ;
VAL_ 494 SDWSwtSet 0 "No Request" 1 "Request" ;
VAL_ 545 RollingCounter_DCT5 0 "Valid value" 15 "Invalid value" ;
VAL_ 545 ShiftLeverPosn_SBWM 0 "P" 1 "D" 2 "N" 3 "R" 4 "M" 5 "Blank" 6 "Reserved" 7 "Invalid value" ;
VAL_ 545 TRANS_Warning_LAMP 0 "The_Warning_Mil_light_is_off" 1 "The_Warning_Mil_light_is_on" ;
VAL_ 545 TGS_LEVER 0 "Select_lever_in_position_P" 1 "Reserved" 2 "Reserved" 3 "Reserved" 4 "Reserved" 5 "Select_lever_in_position_D" 6 "Select_lever_in_position_N" 7 "Select_lever_in_position_R" 8 "Select_lever_in_position_M" 9 "Reserved" 14 "Intermediate_position" 15 "Invalid_Values" ;
VAL_ 545 CURRENT_GEAR 0 "Current gear -N- or -P-" 1 "Current gear -1-" 2 "Current gear -2-" 3 "Current gear -3-" 4 "Current gear -4-" 5 "Current gear -5-" 6 "Current gear -6-" 7 "Current gear -7-" 8 "Current gear -R-" 9 "Current gear -8-" 10 "Current gear -9-" 11 "Reserved" ;
VAL_ 545 TCU_OSS 0 "Valid_values" 16383 "Invalid_value" ;
VAL_ 545 TARGET_GEAR 0 "Target gear -N- or -P -" 1 "Target gear -1-" 2 "Target gear -2-" 3 "Target gear -3-" 4 "Target gear -4-" 5 "Target gear -5-" 6 "Target gear -6-" 7 "Target gear -7-" 8 "Target gear -R-" 9 "Target gear -8-" 10 "Target gear -9-" 11 "Reserved" ;
VAL_ 545 TCU_APS_Available 0 "Available" 1 "Not available" ;
VAL_ 545 ShiftInPrgValid 0 "Invalid" 1 "Valid" ;
VAL_ 545 TargetGearValid 0 "Invalid" 1 "Valid" ;
VAL_ 545 SHIFT_IN_PROGRESS 0 "Gear Shift NOT in progress." 1 "Gear Shif is in progress" ;
VAL_ 545 CurrentGearValid 0 "Invalid" 1 "Valid" ;
VAL_ 545 TCUDrivingMode 0 "Standard" 1 "Sport" 2 "Economic" 3 "Snow_Mode" 4 "Mud" 5 "Sand" 6 "_4L" 7 "Off_road" 8 "Rock" 9 "Manual" 10 "Failure" 11 "Invalid" 12 "_4LUneven" 13 "_4LMou" 14 "_4LMud_Sand" 15 "_4HStandard" 16 "_4HSnow" 17 "Sport_Plus" 18 "EV_Standard" 19 "EV_ECO" 20 "Save_Standard" 21 "Save_ECO" 22 "Turbo" 23 "Uneven_Nex" 24 "Wade_4H" 25 "Climb_4L" ;
VAL_ 545 TCU_ESP_DriverIntervention 0 "False" 1 "True" ;
VAL_ 545 TGS_LEVERValid 0 "Invalid_Value" 1 "Valid_Value" ;
VAL_ 545 TCU_PEPSAuthReq 0 "Not_request" 1 "Request" ;
VAL_ 545 TrsmShaftDirection 0 "Invalid_values" 1 "Forward" 2 "Backward" 3 "Stop" ;
VAL_ 545 Checksum_DCT5 0 "Valid values" ;
VAL_ 555 RollingCounter_HOD_1 15 "Invalid_value" ;
VAL_ 555 HOD_HandOffSts 0 "Initial_Value" 1 "HANDS_OFF_DETECTED" 2 "HANDS_OFF_NOT_DETECTED" 3 "HANDS_NOT_AVAILABLE" 4 "HANDS_OFF_ERROR" 15 "SNA" ;
VAL_ 555 HOD_CalcThreshold 0 "Valid_values" 255 "Invalid_Calculated_Threshold_value" ;
VAL_ 555 HOD_RespErr 0 "NO_ERROR" 1 "ERROR" ;
VAL_ 555 HOD_ErrInfo 0 "NO_ERROR" 1 "HOD_EEPROM_ERROR" 2 "HOD_ROM_ERROR" 3 "HOD_WATCHDOG_ERROR" 4 "HOD_CPU_ERROR" 5 "HOD_GUARD_INTERRUPTION_ERROR" 6 "HOD_SENSE_INTERRUPTION_ERROR" 7 "HOD_CPU_DEFECT_OR_MAT_SHORTAGE" 8 "UNDERVOLTAGE_ERROR" 9 "OVERVOLTAGE_ERROR" 10 "HOD_CODING_ERROR" 11 "HOD_GENERIC_SYSTEM_ERROR" 15 "SNA" ;
VAL_ 565 DrvFaiMsg 0 "No_Message" 1 "Transmission_Malfunction" 2 "Transmission_P_Engagement_Fault" 3 "Transmission_P_Disengagement_Fault" 4 "Authentication_Failure" 5 "E_Shift_Faulty" 6 "Please_Press_The_Brake_Pedal_Untill_The_P_Gear_Reference_Is_Completed" 7 "Reference_Is_Not_Completed_Please_Shift_Gears_After_Reference_Is_Completed" 8 "P_Gear_Reference_Completed_Please_Released_The_Brake_Pedal" 9 "Reserved" 15 "transmission_Limit_Function" ;
VAL_ 570 CustomSwtSts_Park 0 "Released" 1 "Pressed" 2 "Error" 3 "Invalidation" ;
